VERSION ""

NS_ :

BS_:

BU_: ESM HIB HIP HIS SaGE CBC DASM DIAGNOST EBCM ECM EPS ESC ESL ETM HALF HCP IC OCM ORC PTS RF_HUB SCCM SGW

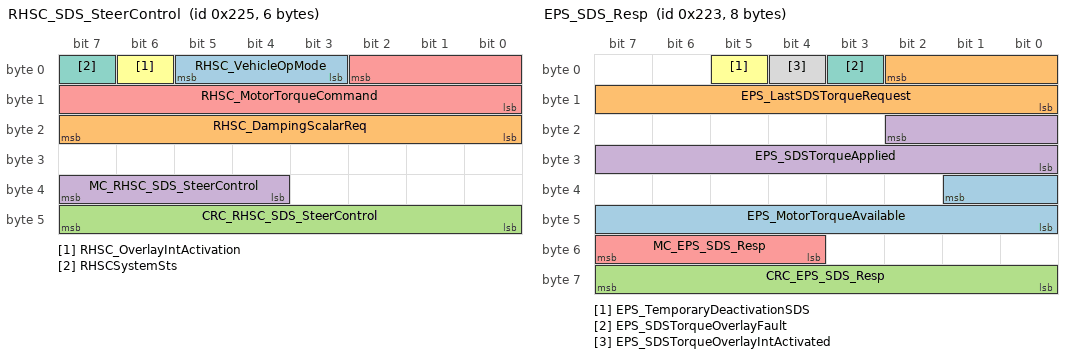
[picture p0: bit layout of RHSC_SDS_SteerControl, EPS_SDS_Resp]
BO_ 549 RHSC_SDS_SteerControl: 6 HIS
 SG_ RHSC_VehicleOpMode : 5|3@0+ (1,0) [0|6] "%"  EPS
 SG_ RHSC_DampingScalarReq : 23|8@0+ (1,0) [0|254] "%"  EPS
 SG_ CRC_RHSC_SDS_SteerControl : 40|8@1+ (1,0) [0|0] ""  EPS
 SG_ MC_RHSC_SDS_SteerControl : 36|4@1+ (1,0) [0|15] ""  EPS
 SG_ RHSC_MotorTorqueCommand : 2|11@0+ (0.0048828125,-5) [-5|4.9951171875] "Nm"  EPS
 SG_ RHSC_OverlayIntActivation : 6|1@1+ (1,0) [0|0] ""  EPS
 SG_ RHSCSystemSts : 7|1@1+ (1,0) [0|0] ""  EPS

BO_ 547 EPS_SDS_Resp: 8 EPS
 SG_ EPS_MotorTorqueAvailable : 33|10@0+ (0.00488281,0) [0|4.99022926] "Nm"  HIS
 SG_ EPS_LastSDSTorqueRequest : 2|11@0+ (0.00488281,-5) [-5|4.99022926] "Nm"  HIS
 SG_ CRC_EPS_SDS_Resp : 56|8@1+ (1,0) [0|0] ""  HIS
 SG_ EPS_SDSTorqueApplied : 18|11@0+ (0.00488281,-5) [-5|4.99022926] "Nm"  HIS
 SG_ MC_EPS_SDS_Resp : 52|4@1+ (1,0) [0|15] ""  HIS
 SG_ EPS_TemporaryDeactivationSDS : 5|1@1+ (1,0) [0|0] ""  HIS
 SG_ EPS_SDSTorqueOverlayFault : 3|1@1+ (1,0) [0|0] ""  HIS
 SG_ EPS_SDSTorqueOverlayIntActivated : 4|1@1+ (1,0) [0|0] ""  HIS

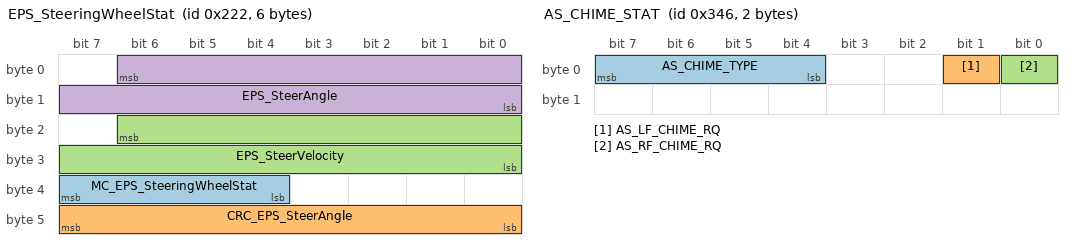
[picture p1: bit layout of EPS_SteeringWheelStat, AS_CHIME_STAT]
BO_ 546 EPS_SteeringWheelStat: 6 EPS
 SG_ MC_EPS_SteeringWheelStat : 36|4@1+ (1,0) [0|15] ""  HIS
 SG_ CRC_EPS_SteerAngle : 40|8@1+ (1,0) [0|0] ""  HIS
 SG_ EPS_SteerVelocity : 22|15@0+ (0.1,-1638.3) [-1638.3|1638.3] "deg/s"  HIS
 SG_ EPS_SteerAngle : 6|15@0+ (0.1,-1638.3) [-1638.3|1638.3] "deg"  HIS

BO_ 969 AMB_TEMP_DISP: 4 CBC
 SG_ AMB_TEMP_AVG_C : 8|8@1+ (1,-40) [-40|210] "°C"  IC,SGW
 SG_ AMB_TEMP_AVG_F : 0|8@1+ (1,-40) [-40|210] "°F"  IC,SGW

BO_ 1788 APPL_ECU_BSMO: 8 DIAGNOST
 SG_ APPL_ECU_BSMO : 7|64@0+ (1,0) [0|0] ""  ESC

BO_ 1729 APPL_ECU_CBC: 8 DIAGNOST
 SG_ APPL_ECU_CBC : 7|64@0+ (1,0) [0|0] ""  CBC

BO_ 1747 APPL_ECU_DASM: 8 DIAGNOST
 SG_ APPL_ECU_DASM : 7|64@0+ (1,0) [0|0] ""  DASM

BO_ 1787 APPL_ECU_EBCM: 8 DIAGNOST
 SG_ APPL_ECU_EBCM : 7|64@0+ (1,0) [0|0] ""  EBCM

BO_ 1784 APPL_ECU_ECM: 8 DIAGNOST
 SG_ APPL_ECU_ECM : 7|64@0+ (1,0) [0|0] ""  ECM

BO_ 1754 APPL_ECU_EPS: 8 DIAGNOST
 SG_ APPL_ECU_EPS : 7|64@0+ (1,0) [0|0] ""  EPS

BO_ 1736 APPL_ECU_ESL: 8 DIAGNOST
 SG_ APPL_ECU_ESL : 7|64@0+ (1,0) [0|0] ""  ESL

BO_ 1737 APPL_ECU_ESM: 8 DIAGNOST
 SG_ APPL_ECU_ESM : 7|64@0+ (1,0) [0|0] "" Vector__XXX

BO_ 1764 APPL_ECU_HALF: 8 DIAGNOST
 SG_ APPL_ECU_HaLF : 7|64@0+ (1,0) [0|0] ""  HALF

BO_ 1786 APPL_ECU_HCP: 8 DIAGNOST
 SG_ APPL_ECU_HCP : 7|64@0+ (1,0) [0|0] ""  HCP

BO_ 1730 APPL_ECU_IC: 8 DIAGNOST
 SG_ APPL_ECU_IC : 7|64@0+ (1,0) [0|0] ""  IC

BO_ 1758 APPL_ECU_OCM: 8 DIAGNOST
 SG_ APPL_ECU_OCM : 7|64@0+ (1,0) [0|0] ""  OCM

BO_ 1732 APPL_ECU_ORC: 8 DIAGNOST
 SG_ APPL_ECU_ORC : 7|64@0+ (1,0) [0|0] ""  ORC

BO_ 1762 APPL_ECU_PTS: 8 DIAGNOST
 SG_ APPL_ECU_PTS : 7|64@0+ (1,0) [0|0] ""  PTS

BO_ 1728 APPL_ECU_RF_HUB: 8 DIAGNOST
 SG_ APPL_ECU_RF_HUB : 7|64@0+ (1,0) [0|0] ""  RF_HUB

BO_ 1763 APPL_ECU_SCCM: 8 DIAGNOST
 SG_ APPL_ECU_SCCM : 7|64@0+ (1,0) [0|0] ""  SCCM

BO_ 838 AS_CHIME_STAT: 2 DASM
 SG_ AS_CHIME_TYPE : 4|4@1+ (1,0) [0|0] ""  CBC,ORC,SGW
 SG_ AS_LF_CHIME_RQ : 1|1@1+ (1,0) [0|0] ""  CBC,SGW
 SG_ AS_RF_CHIME_RQ : 0|1@1+ (1,0) [0|0] ""  CBC,SGW

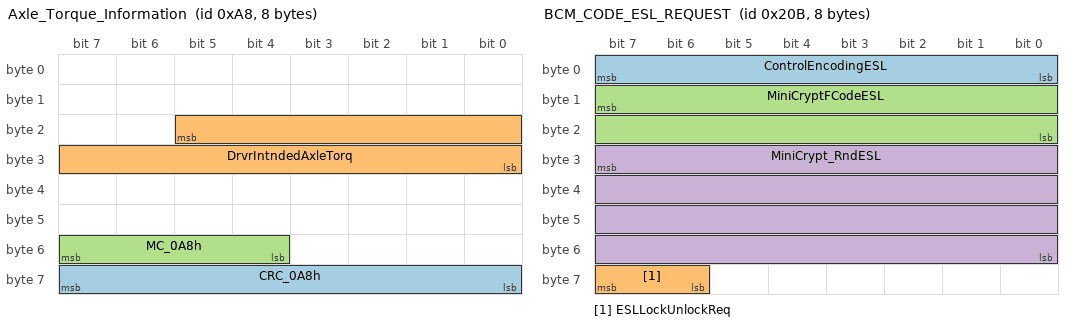
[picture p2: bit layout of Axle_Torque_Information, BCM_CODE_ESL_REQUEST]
BO_ 168 Axle_Torque_Information: 8 ECM
 SG_ CRC_0A8h : 56|8@1+ (1,0) [0|0] ""  HIB,DASM,ESC,SGW
 SG_ DrvrIntndedAxleTorq : 21|14@0+ (1.5625,-4604.688) [-4604.688|20970.3125] "Nm"  HIB,DASM,ESC,ORC,SGW
 SG_ MC_0A8h : 52|4@1+ (1,0) [0|15] ""  HIB,DASM,ESC,SGW

BO_ 523 BCM_CODE_ESL_REQUEST: 8 CBC
 SG_ ControlEncodingESL : 0|8@1+ (1,0) [0|0] ""  ESL,SGW
 SG_ ESLLockUnlockReq : 62|2@1+ (1,0) [0|0] ""  ESL,SGW
 SG_ MiniCryptFCodeESL : 15|16@0+ (1,0) [0|0] ""  ESL,SGW
 SG_ MiniCrypt_RndESL : 31|32@0+ (1,0) [0|0] ""  ESL,SGW

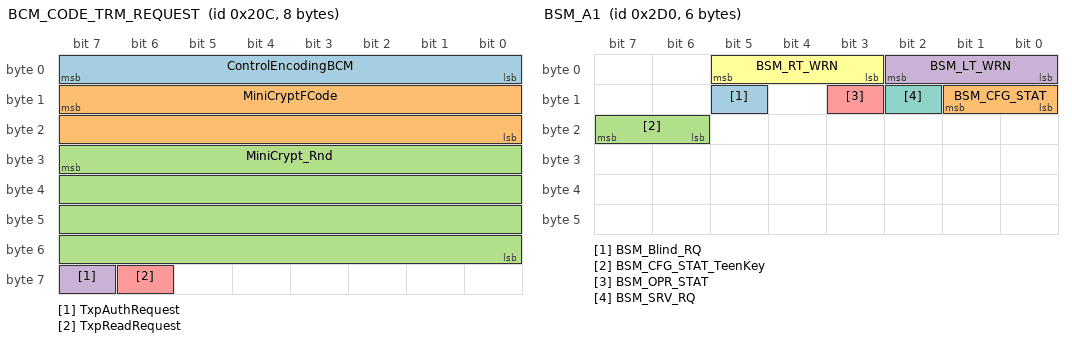
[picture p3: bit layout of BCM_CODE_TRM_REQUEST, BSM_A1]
BO_ 524 BCM_CODE_TRM_REQUEST: 8 CBC
 SG_ ControlEncodingBCM : 0|8@1+ (1,0) [0|0] ""  RF_HUB,SGW
 SG_ MiniCryptFCode : 15|16@0+ (1,0) [0|0] ""  RF_HUB,SGW
 SG_ MiniCrypt_Rnd : 31|32@0+ (1,0) [0|0] ""  RF_HUB,SGW
 SG_ TxpAuthRequest : 63|1@1+ (1,0) [0|0] ""  RF_HUB,SGW
 SG_ TxpReadRequest : 62|1@1+ (1,0) [0|0] ""  RF_HUB,SGW

BO_ 525 BCM_MINICRYPT_ACK: 1 CBC
 SG_ MinicryptReceptionSts : 7|1@1+ (1,0) [0|0] ""  RF_HUB,SGW

BO_ 720 BSM_A1: 6 CBC
 SG_ BSM_Blind_RQ : 13|1@1+ (1,0) [0|0] ""  HIB,DASM,IC,ORC,SGW
 SG_ BSM_CFG_STAT : 8|2@1+ (1,0) [0|0] ""  HIB,DASM,IC,ORC,SGW
 SG_ BSM_CFG_STAT_TeenKey : 22|2@1+ (1,0) [0|0] ""  HIB,DASM,SGW
 SG_ BSM_LT_WRN : 0|3@1+ (1,0) [0|0] ""  HIB,DASM,ORC,SGW
 SG_ BSM_OPR_STAT : 11|1@1+ (1,0) [0|0] ""  HIB,DASM,IC,SGW
 SG_ BSM_RT_WRN : 3|3@1+ (1,0) [0|0] ""  HIB,DASM,ORC,SGW
 SG_ BSM_SRV_RQ : 10|1@1+ (1,0) [0|0] ""  HIB,DASM,IC,ORC,SGW

BO_ 998 BU_NET_CFG_INT: 8 RF_HUB
 SG_ BU_NET_CFG_STAT_INT : 0|2@1+ (1,0) [0|0] ""  CBC,SGW
 SG_ BU_NetCfg_AMP_I : 24|1@1+ (1,0) [0|0] ""  CBC,SGW
 SG_ BU_NetCfg_ANC_I : 39|1@1+ (1,0) [0|0] ""  CBC,SGW
 SG_ BU_NetCfg_BSM : 3|1@1+ (1,0) [0|0] ""  CBC,SGW
 SG_ BU_NetCfg_CBC_IN : 4|1@1+ (1,0) [0|0] ""  CBC,SGW
 SG_ BU_NetCfg_CLOCK : 21|1@1+ (1,0) [0|0] ""  CBC,SGW
 SG_ BU_NetCfg_CRSM : 30|1@1+ (1,0) [0|0] ""  CBC,SGW
 SG_ BU_NetCfg_CSWM : 5|1@1+ (1,0) [0|0] ""  CBC,SGW
 SG_ BU_NetCfg_CVPM : 32|1@1+ (1,0) [0|0] ""  CBC,SGW
 SG_ BU_NetCfg_DCM_DR : 6|1@1+ (1,0) [0|0] ""  CBC,SGW
 SG_ BU_NetCfg_DCM_PASS : 7|1@1+ (1,0) [0|0] ""  CBC,SGW
 SG_ BU_NetCfg_DCM_RL : 8|1@1+ (1,0) [0|0] ""  CBC,SGW
 SG_ BU_NetCfg_DCM_RR : 9|1@1+ (1,0) [0|0] ""  CBC,SGW
 SG_ BU_NetCfg_DCSD : 37|1@1+ (1,0) [0|0] ""  CBC,SGW
 SG_ BU_NetCfg_DTV : 19|1@1+ (1,0) [0|0] ""  CBC,SGW
 SG_ BU_NetCfg_DVD_CDM : 25|1@1+ (1,0) [0|0] ""  CBC,SGW
 SG_ BU_NetCfg_FSM : 16|1@1+ (1,0) [0|0] ""  CBC,SGW
 SG_ BU_NetCfg_HFM_CTM : 26|1@1+ (1,0) [0|0] ""  CBC,SGW
 SG_ BU_NetCfg_HVAC : 10|1@1+ (1,0) [0|0] ""  CBC,SGW
 SG_ BU_NetCfg_HVAC_R : 31|1@1+ (1,0) [0|0] ""  CBC,SGW
 SG_ BU_NetCfg_ICS_I : 27|1@1+ (1,0) [0|0] ""  CBC,SGW
 SG_ BU_NetCfg_ICS_R : 34|1@1+ (1,0) [0|0] ""  CBC,SGW
 SG_ BU_NetCfg_ITM : 23|1@1+ (1,0) [0|0] ""  CBC,SGW
 SG_ BU_NetCfg_MSM : 11|1@1+ (1,0) [0|0] ""  CBC,SGW
 SG_ BU_NetCfg_MSM_PASS : 35|1@1+ (1,0) [0|0] ""  CBC,SGW
 SG_ BU_NetCfg_PLG : 12|1@1+ (1,0) [0|0] ""  CBC,SGW
 SG_ BU_NetCfg_PSD_LT : 14|1@1+ (1,0) [0|0] ""  CBC,SGW
 SG_ BU_NetCfg_PSD_RT : 15|1@1+ (1,0) [0|0] ""  CBC,SGW
 SG_ BU_NetCfg_PTCM : 17|1@1+ (1,0) [0|0] ""  CBC,SGW
 SG_ BU_NetCfg_RBC : 18|1@1+ (1,0) [0|0] ""  CBC,SGW
 SG_ BU_NetCfg_RBSS : 2|1@1+ (1,0) [0|0] ""  CBC,SGW
 SG_ BU_NetCfg_TBM : 38|1@1+ (1,0) [0|0] ""  CBC,SGW
 SG_ BU_NetCfg_TGW : 20|1@1+ (1,0) [0|0] ""  CBC,SGW
 SG_ BU_NetCfg_TMM : 33|1@1+ (1,0) [0|0] ""  CBC,SGW
 SG_ BU_NetCfg_VES2_I : 28|1@1+ (1,0) [0|0] ""  CBC,SGW
 SG_ BU_NetCfg_VES3_I : 29|1@1+ (1,0) [0|0] ""  CBC,SGW
 SG_ BU_NetCfg_VRM : 36|1@1+ (1,0) [0|0] ""  CBC,SGW
 SG_ BU_NetCfg_VSIM : 22|1@1+ (1,0) [0|0] ""  CBC,SGW
 SG_ BU_NetCfg_VTM : 13|1@1+ (1,0) [0|0] ""  CBC,SGW

BO_ 999 BU_NET_CFG_PT: 8 RF_HUB
 SG_ BU_NET_CFG_STAT_PT : 0|2@1+ (1,0) [0|0] ""  CBC,SGW
 SG_ BU_NetCfg_ACC : 2|1@1+ (1,0) [0|0] ""  CBC,SGW
 SG_ BU_NetCfg_ADCM : 3|1@1+ (1,0) [0|0] ""  CBC,SGW
 SG_ BU_NetCfg_AFLS : 28|1@1+ (1,0) [0|0] ""  CBC,SGW
 SG_ BU_NetCfg_AHLM : 4|1@1+ (1,0) [0|0] ""  CBC,SGW
 SG_ BU_NetCfg_ANC : 39|1@1+ (1,0) [0|0] ""  CBC,SGW
 SG_ BU_NetCfg_ASCM : 6|1@1+ (1,0) [0|0] ""  CBC,SGW
 SG_ BU_NetCfg_BSMO : 36|1@1+ (1,0) [0|0] ""  CBC,SGW
 SG_ BU_NetCfg_CBC_PT : 7|1@1+ (1,0) [0|0] ""  CBC,SGW
 SG_ BU_NetCfg_DASM : 16|1@1+ (1,0) [0|0] ""  CBC,SGW
 SG_ BU_NetCfg_DTCM : 8|1@1+ (1,0) [0|0] ""  CBC,SGW
 SG_ BU_NetCfg_ECM : 9|1@1+ (1,0) [0|0] ""  CBC,SGW
 SG_ BU_NetCfg_ELSD : 24|1@1+ (1,0) [0|0] ""  CBC,SGW
 SG_ BU_NetCfg_EPB : 13|1@1+ (1,0) [0|0] ""  CBC,SGW
 SG_ BU_NetCfg_EPPM : 18|1@1+ (1,0) [0|0] ""  CBC,SGW
 SG_ BU_NetCfg_EPS : 10|1@1+ (1,0) [0|0] ""  CBC,SGW
 SG_ BU_NetCfg_ESC : 12|1@1+ (1,0) [0|0] ""  CBC,SGW
 SG_ BU_NetCfg_ESL : 37|1@1+ (1,0) [0|0] ""  CBC,SGW
 SG_ BU_NetCfg_ESM : 11|1@1+ (1,0) [0|0] ""  CBC,SGW
 SG_ BU_NetCfg_FDCM : 17|1@1+ (1,0) [0|0] ""  CBC,SGW
 SG_ BU_NetCfg_HCP : 38|1@1+ (1,0) [0|0] ""  CBC,SGW
 SG_ BU_NetCfg_HaLF : 31|1@1+ (1,0) [0|0] ""  CBC,SGW
 SG_ BU_NetCfg_IC : 15|1@1+ (1,0) [0|0] ""  CBC,SGW
 SG_ BU_NetCfg_ITBM : 29|1@1+ (1,0) [0|0] ""  CBC,SGW
 SG_ BU_NetCfg_OCM : 30|1@1+ (1,0) [0|0] ""  CBC,SGW
 SG_ BU_NetCfg_ORC : 19|1@1+ (1,0) [0|0] ""  CBC,SGW
 SG_ BU_NetCfg_PASS_PT : 27|1@1+ (1,0) [0|0] ""  CBC,SGW
 SG_ BU_NetCfg_PTS : 20|1@1+ (1,0) [0|0] ""  CBC,SGW
 SG_ BU_NetCfg_RF_HUB : 14|1@1+ (1,0) [0|0] ""  CBC,SGW
 SG_ BU_NetCfg_RHSC2 : 44|1@1+ (1,0) [0|0] ""  CBC,SGW
 SG_ BU_NetCfg_SCCM : 23|1@1+ (1,0) [0|0] ""  CBC,SGW
 SG_ BU_NetCfg_TCM : 25|1@1+ (1,0) [0|0] ""  CBC,SGW
 SG_ BU_NetCfg_TPM : 26|1@1+ (1,0) [0|0] ""  CBC,SGW
 SG_ BU_NetCfg_VSIM_C : 5|1@1+ (1,0) [0|0] ""  CBC,SGW

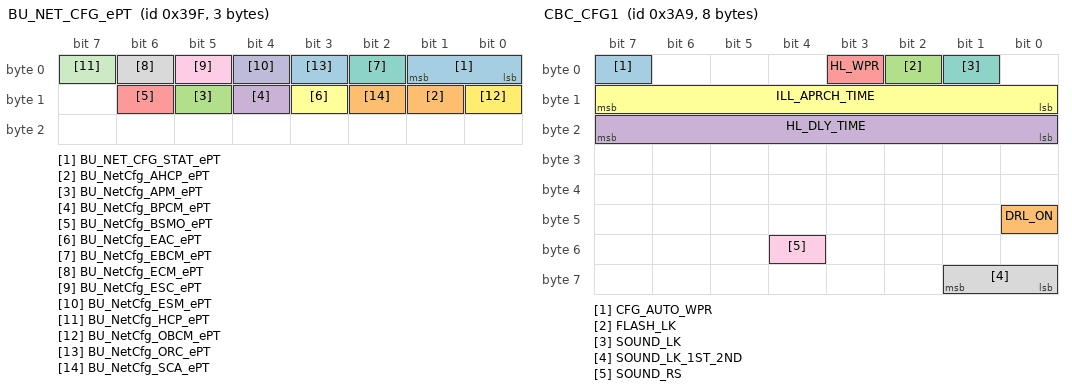
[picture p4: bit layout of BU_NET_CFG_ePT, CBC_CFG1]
BO_ 927 BU_NET_CFG_ePT: 3 RF_HUB
 SG_ BU_NET_CFG_STAT_ePT : 0|2@1+ (1,0) [0|0] ""  CBC,SGW
 SG_ BU_NetCfg_AHCP_ePT : 9|1@1+ (1,0) [0|0] ""  CBC,SGW
 SG_ BU_NetCfg_APM_ePT : 13|1@1+ (1,0) [0|0] ""  CBC,SGW
 SG_ BU_NetCfg_BPCM_ePT : 12|1@1+ (1,0) [0|0] ""  CBC,SGW
 SG_ BU_NetCfg_BSMO_ePT : 14|1@1+ (1,0) [0|0] ""  CBC,SGW
 SG_ BU_NetCfg_EAC_ePT : 11|1@1+ (1,0) [0|0] ""  CBC,SGW
 SG_ BU_NetCfg_EBCM_ePT : 2|1@1+ (1,0) [0|0] ""  CBC,SGW
 SG_ BU_NetCfg_ECM_ePT : 6|1@1+ (1,0) [0|0] ""  CBC,SGW
 SG_ BU_NetCfg_ESC_ePT : 5|1@1+ (1,0) [0|0] ""  CBC,SGW
 SG_ BU_NetCfg_ESM_ePT : 4|1@1+ (1,0) [0|0] ""  CBC,SGW
 SG_ BU_NetCfg_HCP_ePT : 7|1@1+ (1,0) [0|0] ""  CBC,SGW
 SG_ BU_NetCfg_OBCM_ePT : 8|1@1+ (1,0) [0|0] ""  CBC,SGW
 SG_ BU_NetCfg_ORC_ePT : 3|1@1+ (1,0) [0|0] ""  CBC,SGW
 SG_ BU_NetCfg_SCA_ePT : 10|1@1+ (1,0) [0|0] ""  CBC,SGW

BO_ 937 CBC_CFG1: 8 CBC
 SG_ CFG_AUTO_WPR : 7|1@1+ (1,0) [0|0] ""  SGW
 SG_ DRL_ON : 40|1@1+ (1,0) [0|0] ""  SGW
 SG_ FLASH_LK : 2|1@1+ (1,0) [0|0] ""  SGW
 SG_ HL_DLY_TIME : 16|8@1+ (1,0) [0|254] "sec"  SGW
 SG_ HL_WPR : 3|1@1+ (1,0) [0|0] ""  SGW
 SG_ ILL_APRCH_TIME : 8|8@1+ (1,0) [0|254] "sec"  SGW
 SG_ SOUND_LK : 1|1@1+ (1,0) [0|0] ""  SGW
 SG_ SOUND_LK_1ST_2ND : 56|2@1+ (1,0) [0|0] ""  SGW
 SG_ SOUND_RS : 52|1@1+ (1,0) [0|0] ""  SGW

BO_ 820 CBC_PT1: 8 CBC
 SG_ AHB_ACT : 14|1@1+ (1,0) [0|0] ""  IC,SGW
 SG_ BRK_FLUID_LO : 62|1@1+ (1,0) [0|0] ""  ESC,ETM,IC,SGW
 SG_ DAY_LGT_MD : 40|1@1+ (1,0) [0|0] ""  IC,RF_HUB,SCCM,SGW
 SG_ DRV_AJAR : 17|1@1+ (1,0) [0|0] ""  HIB,DASM,ECM,ESC,ETM,HCP,IC,PTS,RF_HUB,SGW
 SG_ DR_LK_STAT : 5|2@1+ (1,0) [0|0] ""  SGW
 SG_ FOB_SrchRq : 8|2@1+ (1,0) [0|0] ""  RF_HUB,SGW
 SG_ FT_FOG_RQ : 2|1@1+ (1,0) [0|0] ""  ETM,IC,SGW
 SG_ FT_WPR_NOT_PRK : 56|1@1+ (1,0) [0|0] ""  HIB,DASM,ECM,HALF,SGW
 SG_ HIBEAM_ON : 58|1@1+ (1,0) [0|0] ""  HIB,ETM,HALF,IC,SGW
 SG_ IGN_OFF_TIME_LNG : 27|12@0+ (1,0) [0|4080] "min"  HIB,DASM,ECM,ESC,SGW
 SG_ LOBEAM_ON : 57|1@1+ (1,0) [0|0] ""  SGW
 SG_ L_R_AJAR : 19|1@1+ (1,0) [0|0] ""  ETM,IC,RF_HUB,SGW
 SG_ PANEL_INTS : 48|8@1+ (0.5,0) [0|100] "%"  IC,RF_HUB,SCCM,SGW
 SG_ PARK_LMP_ON : 16|1@1+ (1,0) [0|0] ""  IC,SGW
 SG_ PSG_AJAR : 18|1@1+ (1,0) [0|0] ""  ESC,ETM,IC,RF_HUB,SGW
 SG_ REV_GEAR : 4|1@1+ (1,0) [0|0] ""  EPS,HALF,ORC,SGW
 SG_ R_FOG_RQ : 3|1@1+ (1,0) [0|0] ""  IC,SGW
 SG_ R_R_AJAR : 20|1@1+ (1,0) [0|0] ""  ETM,IC,RF_HUB,SGW
 SG_ SHIP_STAT : 28|2@1+ (1,0) [0|0] ""  HIB,DASM,HCP,IC,RF_HUB,SGW
 SG_ TLG_AJAR : 22|1@1+ (1,0) [0|0] ""  ETM,IC,PTS,RF_HUB,SGW
 SG_ TurnInd_LT_ON : 30|1@1+ (1,0) [0|0] ""  HIB,ETM,HALF,IC,SGW
 SG_ TurnInd_RT_ON : 31|1@1+ (1,0) [0|0] ""  HIB,ETM,HALF,IC,SGW
 SG_ WASH_FLUID_LO : 63|1@1+ (1,0) [0|0] ""  ETM,IC,SGW

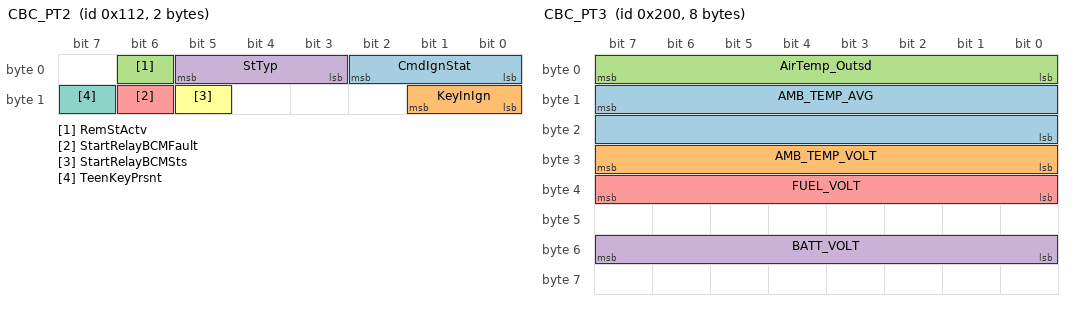
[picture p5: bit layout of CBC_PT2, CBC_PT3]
BO_ 274 CBC_PT2: 2 CBC
 SG_ CmdIgnStat : 0|3@1+ (1,0) [0|0] ""  HIB,DASM,EBCM,ECM,EPS,ESC,ESL,HALF,HCP,IC,OCM,ORC,PTS,RF_HUB,SCCM,SGW
 SG_ KeyInIgn : 8|2@1+ (1,0) [0|0] ""  ESL,HCP,IC,RF_HUB,SGW
 SG_ RemStActv : 6|1@1+ (1,0) [0|0] ""  ECM,HCP,IC,RF_HUB,SGW
 SG_ StTyp : 3|3@1+ (1,0) [0|0] ""  RF_HUB,SGW
 SG_ StartRelayBCMFault : 14|1@1+ (1,0) [0|0] ""  ECM,SGW
 SG_ StartRelayBCMSts : 13|1@1+ (1,0) [0|0] ""  ECM,SGW
 SG_ TeenKeyPrsnt : 15|1@1+ (1,0) [0|0] ""  HIB,DASM,ECM,IC,ORC,PTS,SGW

BO_ 512 CBC_PT3: 8 CBC
 SG_ AMB_TEMP_AVG : 15|16@0+ (0.01,-40) [-40|85] "°C"  HIB,DASM,ECM,EPS,ESC,OCM,PTS,RF_HUB,SGW
 SG_ AMB_TEMP_VOLT : 24|8@1+ (0.019607843,0) [0|4.98] "Volts"  ECM,HCP,SGW
 SG_ AirTemp_Outsd : 0|8@1+ (0.5,-40) [-40|85] "°C"  HIB,DASM,ECM,EPS,RF_HUB,SGW
 SG_ BATT_VOLT : 48|8@1+ (0.1,0) [5|18] "Volts"  HIB,DASM,EBCM,ECM,EPS,ESC,ESL,HALF,HCP,IC,OCM,ORC,PTS,RF_HUB,SCCM,SGW
 SG_ FUEL_VOLT : 32|8@1+ (0.019607843,0) [0|4.98] "Volts"  ECM,IC,SGW

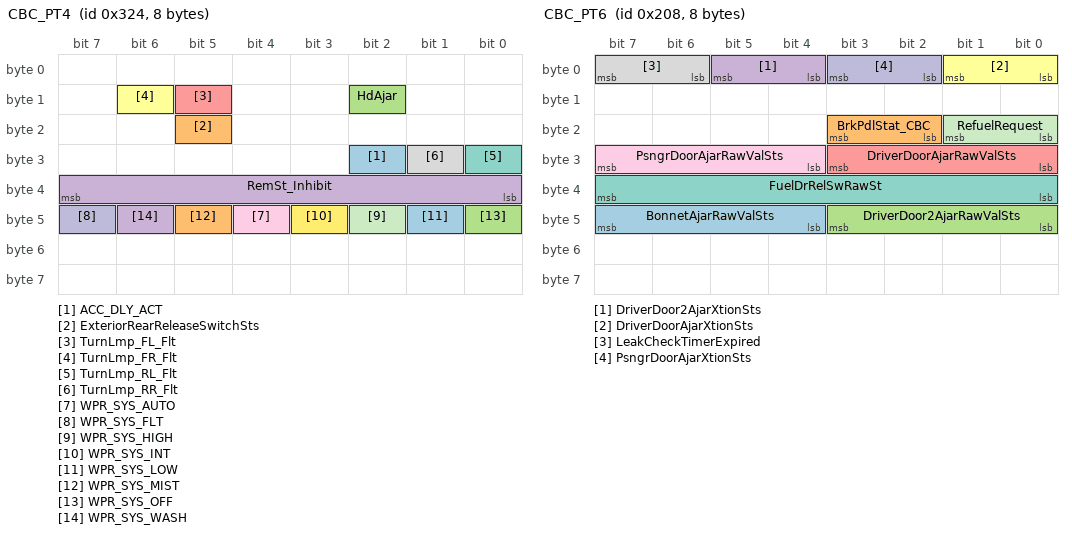
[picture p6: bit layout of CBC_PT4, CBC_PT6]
BO_ 804 CBC_PT4: 8 CBC
 SG_ ACC_DLY_ACT : 26|1@1+ (1,0) [0|0] ""  IC,SGW
 SG_ ExteriorRearReleaseSwitchSts : 21|1@1+ (1,0) [0|0] ""  RF_HUB,SGW
 SG_ HdAjar : 10|1@1+ (1,0) [0|0] ""  HCP,IC,SGW
 SG_ RemSt_Inhibit : 32|8@1+ (1,0) [0|0] ""  ETM,IC,SGW
 SG_ TurnLmp_FL_Flt : 13|1@1+ (1,0) [0|0] ""  HIB,ETM,HALF,IC,SGW
 SG_ TurnLmp_FR_Flt : 14|1@1+ (1,0) [0|0] ""  HIB,ETM,HALF,IC,SGW
 SG_ TurnLmp_RL_Flt : 24|1@1+ (1,0) [0|0] ""  HIB,ETM,HALF,IC,SGW
 SG_ TurnLmp_RR_Flt : 25|1@1+ (1,0) [0|0] ""  HIB,ETM,HALF,IC,SGW
 SG_ WPR_SYS_AUTO : 44|1@1+ (1,0) [0|0] ""  HIB,DASM,ESC,HALF,SGW
 SG_ WPR_SYS_FLT : 47|1@1+ (1,0) [0|0] ""  HIB,DASM,ESC,HALF,SGW
 SG_ WPR_SYS_HIGH : 42|1@1+ (1,0) [0|0] ""  HIB,DASM,ESC,HALF,SGW
 SG_ WPR_SYS_INT : 43|1@1+ (1,0) [0|0] ""  HIB,DASM,ESC,HALF,SGW
 SG_ WPR_SYS_LOW : 41|1@1+ (1,0) [0|0] ""  HIB,DASM,ESC,HALF,SGW
 SG_ WPR_SYS_MIST : 45|1@1+ (1,0) [0|0] ""  HIB,DASM,ESC,HALF,SGW
 SG_ WPR_SYS_OFF : 40|1@1+ (1,0) [0|0] ""  HIB,DASM,ESC,HALF,SGW
 SG_ WPR_SYS_WASH : 46|1@1+ (1,0) [0|0] ""  HIB,DASM,ESC,HALF,SGW

BO_ 520 CBC_PT6: 8 CBC
 SG_ BonnetAjarRawValSts : 44|4@1+ (1,0) [0|0] ""  ECM,HCP,ORC,SGW
 SG_ BrkPdlStat_CBC : 18|2@1+ (1,0) [0|0] ""  RF_HUB,SGW
 SG_ DriverDoor2AjarRawValSts : 40|4@1+ (1,0) [0|0] ""  ECM,ORC,SGW
 SG_ DriverDoor2AjarXtionSts : 4|2@1+ (1,0) [0|0] ""  ECM,SGW
 SG_ DriverDoorAjarRawValSts : 24|4@1+ (1,0) [0|0] ""  ECM,ESC,ORC,SGW
 SG_ DriverDoorAjarXtionSts : 0|2@1+ (1,0) [0|0] ""  ECM,ESC,SGW
 SG_ FuelDrRelSwRawSt : 32|8@1+ (0.019607843,0) [0|4.98] "Volts"  ECM,SGW
 SG_ LeakCheckTimerExpired : 6|2@1+ (1,0) [0|0] ""  ECM,SGW
 SG_ PsngrDoorAjarRawValSts : 28|4@1+ (1,0) [0|0] ""  ECM,ORC,SGW
 SG_ PsngrDoorAjarXtionSts : 2|2@1+ (1,0) [0|0] ""  SGW
 SG_ RefuelRequest : 16|2@1+ (1,0) [0|0] ""  ECM,SGW

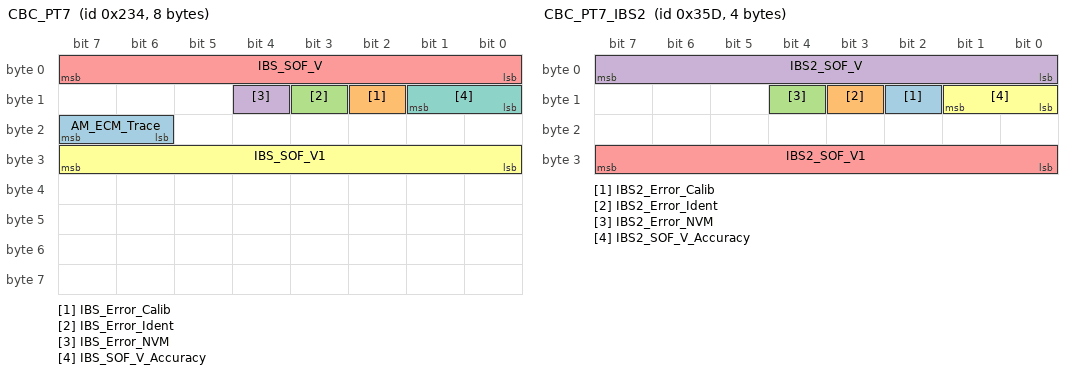
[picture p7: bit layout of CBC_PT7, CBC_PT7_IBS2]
BO_ 564 CBC_PT7: 8 CBC
 SG_ AM_ECM_Trace : 22|2@1+ (1,0) [0|0] ""  ECM,SGW
 SG_ IBS_Error_Calib : 10|1@1+ (1,0) [0|0] ""  SGW
 SG_ IBS_Error_Ident : 11|1@1+ (1,0) [0|0] ""  SGW
 SG_ IBS_Error_NVM : 12|1@1+ (1,0) [0|0] ""  SGW
 SG_ IBS_SOF_V : 0|8@1+ (0.0625,0) [0|15.875] "V"  SGW
 SG_ IBS_SOF_V1 : 24|8@1+ (0.0625,0) [0|15.875] "V"  SGW
 SG_ IBS_SOF_V_Accuracy : 8|2@1+ (1,0) [0|0] ""  SGW

BO_ 861 CBC_PT7_IBS2: 4 CBC
 SG_ IBS2_Error_Calib : 10|1@1+ (1,0) [0|0] ""  SGW
 SG_ IBS2_Error_Ident : 11|1@1+ (1,0) [0|0] ""  SGW
 SG_ IBS2_Error_NVM : 12|1@1+ (1,0) [0|0] ""  SGW
 SG_ IBS2_SOF_V : 0|8@1+ (0.0625,0) [0|15.875] "V"  SGW
 SG_ IBS2_SOF_V1 : 24|8@1+ (0.0625,0) [0|15.875] "V"  SGW
 SG_ IBS2_SOF_V_Accuracy : 8|2@1+ (1,0) [0|0] ""  SGW

BO_TX_BU_ 1788 : DIAGNOST,SGW;
BO_TX_BU_ 1729 : DIAGNOST,SGW;
BO_TX_BU_ 1747 : DIAGNOST,SGW;
BO_TX_BU_ 1787 : DIAGNOST,SGW;
BO_TX_BU_ 1784 : DIAGNOST,SGW;
BO_TX_BU_ 1754 : DIAGNOST,SGW;
BO_TX_BU_ 1736 : DIAGNOST,SGW;
BO_TX_BU_ 1737 : DIAGNOST,SGW;
BO_TX_BU_ 1764 : DIAGNOST,SGW;
BO_TX_BU_ 1786 : DIAGNOST,SGW;
BO_TX_BU_ 1730 : DIAGNOST,SGW;
BO_TX_BU_ 1758 : DIAGNOST,SGW;
BO_TX_BU_ 1732 : DIAGNOST,SGW;
BO_TX_BU_ 1762 : DIAGNOST,SGW;
BO_TX_BU_ 1728 : DIAGNOST,SGW;
BO_TX_BU_ 1763 : DIAGNOST,SGW;

CM_ "Excel Convert to DBC - Written by Vector CANtech, Inc. 2016";
CM_ SG_ 549 RHSC_VehicleOpMode "RHSC vehicle operating mode (Driver Present [0] / Driverless [1])";
CM_ SG_ 549 RHSC_DampingScalarReq "RHSC torque overlay damping scalar request";
CM_ SG_ 549 CRC_RHSC_SDS_SteerControl "CRC-checksum byte 1 to 7 according to SAE J1850";
CM_ SG_ 549 MC_RHSC_SDS_SteerControl "Message counter";
CM_ SG_ 549 RHSC_MotorTorqueCommand "RHSC torque overlay steering request";
CM_ SG_ 549 RHSC_OverlayIntActivation "Torque overlay interface activation; Active = [1]";
CM_ SG_ 549 RHSCSystemSts "Fault of the HALF torque overlay interface; Fault = [1]";
CM_ SG_ 547 EPS_MotorTorqueAvailable "EPS Motor Torque Available for SDS under current conditions";
CM_ SG_ 547 EPS_LastSDSTorqueRequest "Echo Back of Last SDS Valid Torque Request";
CM_ SG_ 547 CRC_EPS_SDS_Resp "CRC-checksum byte 1 to 7 according to SAE J1850";
CM_ SG_ 547 EPS_SDSTorqueApplied "EPS Motor Torque Applied for SDS";
CM_ SG_ 547 MC_EPS_SDS_Resp "Message counter";
CM_ SG_ 547 EPS_TemporaryDeactivationSDS "Temporary deactivation of the EPS SDS torque overlay function, False = [0], True = [1];";
CM_ SG_ 547 EPS_SDSTorqueOverlayFault "Fault of the SDS torque overlay interface, False = [0], True = [1];";
CM_ SG_ 547 EPS_SDSTorqueOverlayIntActivated "Activation Status of the SDS torque overlay interface, False = [0], True = [1];";
CM_ SG_ 546 MC_EPS_SteeringWheelStat "Message counter";
CM_ SG_ 546 CRC_EPS_SteerAngle "CRC-checksum byte 1 to 7 according to SAE J1850";
CM_ SG_ 546 EPS_SteerVelocity "Steer Velocity based on EPS Motor Position sensor";
CM_ SG_ 546 EPS_SteerAngle "Steer Angle based on EPS Motor Position sensor - relative angle from key on";
CM_ SG_ 969 AMB_TEMP_AVG_C "Ambient temperature average - in degrees Celsius";
CM_ SG_ 969 AMB_TEMP_AVG_F "Ambient temperature average - in degrees Fahrenheit";
CM_ SG_ 1788 APPL_ECU_BSMO "External Application to ECU";
CM_ SG_ 1729 APPL_ECU_CBC "External Application to ECU";
CM_ SG_ 1747 APPL_ECU_DASM "External Application to ECU";
CM_ SG_ 1787 APPL_ECU_EBCM "External Application to ECU";
CM_ SG_ 1784 APPL_ECU_ECM "External Application to ECU";
CM_ SG_ 1754 APPL_ECU_EPS "External Application to ECU";
CM_ SG_ 1736 APPL_ECU_ESL "External Application to ECU";
CM_ SG_ 1737 APPL_ECU_ESM "External Application to ECU";
CM_ SG_ 1764 APPL_ECU_HaLF "External Application to ECU";
CM_ SG_ 1786 APPL_ECU_HCP "External Application to ECU";
CM_ SG_ 1730 APPL_ECU_IC "External Application to ECU";
CM_ SG_ 1758 APPL_ECU_OCM "External Application to ECU";
CM_ SG_ 1732 APPL_ECU_ORC "External Application to ECU";
CM_ SG_ 1762 APPL_ECU_PTS "External Application to ECU";
CM_ SG_ 1728 APPL_ECU_RF_HUB "External Application to ECU";
CM_ SG_ 1763 APPL_ECU_SCCM "External Application to ECU";
CM_ SG_ 838 AS_CHIME_TYPE "AS chime type";
CM_ SG_ 838 AS_LF_CHIME_RQ "AS left front chime on request; True = [1]";
CM_ SG_ 838 AS_RF_CHIME_RQ "AS right front chime on request; True = [1]";
CM_ SG_ 168 CRC_0A8h "CRC-Checksum Byte 1 - 7 according to SAE J1850";
CM_ SG_ 168 DrvrIntndedAxleTorq "Driver Intended Axle Torque";
CM_ SG_ 168 MC_0A8h "Message counter   0A8h";
CM_ SG_ 523 ControlEncodingESL "ESL immobilizer action requested";
CM_ SG_ 523 ESLLockUnlockReq "Lock or unlock column";
CM_ SG_ 523 MiniCryptFCodeESL "BCM MiniCrypt code";
CM_ SG_ 523 MiniCrypt_RndESL "MiniCrypt random number";
CM_ SG_ 524 ControlEncodingBCM "Fob authentication or presence query";
CM_ SG_ 524 MiniCryptFCode "MiniCrypt 'F' code output";
CM_ SG_ 524 MiniCrypt_Rnd "MiniCrypt input random number";
CM_ SG_ 524 TxpAuthRequest "Transponder authentication request; Request = [0]";
CM_ SG_ 524 TxpReadRequest "Transponder reading request; Request = [0]";
CM_ SG_ 525 MinicryptReceptionSts "Acknowledge message reception; Received = [1]";
CM_ SG_ 720 BSM_Blind_RQ "Sensor blinded request from BSM; 1= sensor blocked request";
CM_ SG_ 720 BSM_CFG_STAT "BSM configuration status";
CM_ SG_ 720 BSM_CFG_STAT_TeenKey "BSM configuration status for teen key";
CM_ SG_ 720 BSM_LT_WRN "Blind spot detection left side warning";
CM_ SG_ 720 BSM_OPR_STAT "BSM operation status; 1= operational failure";
CM_ SG_ 720 BSM_RT_WRN "Blind spot detection Right side warning";
CM_ SG_ 720 BSM_SRV_RQ "BSM service warning request; 1= service request";
CM_ SG_ 998 BU_NET_CFG_STAT_INT "Backup for network configuration status";
CM_ SG_ 998 BU_NetCfg_AMP_I "Backup for CAN I Amplifier Module (1=present)";
CM_ SG_ 998 BU_NetCfg_ANC_I "Backup for Active Noise Cancellation interior (1=present)";
CM_ SG_ 998 BU_NetCfg_BSM "Backup for Blind-Spot Module (1=present)";
CM_ SG_ 998 BU_NetCfg_CBC_IN "Backup for Common Body Controller Int Bus (1=present)";
CM_ SG_ 998 BU_NetCfg_CLOCK "Backup for CAN I Clock Module (1=present)";
CM_ SG_ 998 BU_NetCfg_CRSM "Backup for CAN I Comfort Rear Seat Module (1=present)";
CM_ SG_ 998 BU_NetCfg_CSWM "Backup for Comfot Seats and Wheel Module (1=present)";
CM_ SG_ 998 BU_NetCfg_CVPM "Backup for CAN I Central Vision Processing Module (1=present)";
CM_ SG_ 998 BU_NetCfg_DCM_DR "Backup for Door Control Module Driver (1=present)";
CM_ SG_ 998 BU_NetCfg_DCM_PASS "Backup for Door Control Module Passenger (1=present)";
CM_ SG_ 998 BU_NetCfg_DCM_RL "Backup for Door Control Module Rear Left (1=present)";
CM_ SG_ 998 BU_NetCfg_DCM_RR "Backup for Door Control Module Rear Right (1=present)";
CM_ SG_ 998 BU_NetCfg_DCSD "Backup for Disassociated Center Stack Display Module (1=present)";
CM_ SG_ 998 BU_NetCfg_DTV "Backup for Digital TV Module (1=present)";
CM_ SG_ 998 BU_NetCfg_DVD_CDM "Backup for CAN I in-dash disc player module (1=present)";
CM_ SG_ 998 BU_NetCfg_FSM "Backup for Folding Seat Module (1=present)";
CM_ SG_ 998 BU_NetCfg_HFM_CTM "Backup for Convergence Telematics Module (1=present)";
CM_ SG_ 998 BU_NetCfg_HVAC "Backup for Heating Ventilation Air Conditioning (1=present)";
CM_ SG_ 998 BU_NetCfg_HVAC_R "Backup for CAN I Rear Heating Ventilation Air Conditioning (1=present)";
CM_ SG_ 998 BU_NetCfg_ICS_I "Backup for CAN I Integrated Center Stack Module (1=present)";
CM_ SG_ 998 BU_NetCfg_ICS_R "Backup for CAN I Integrated rear Center Stack Module (1=present)";
CM_ SG_ 998 BU_NetCfg_ITM "Backup for Intrusion module (1=present)";
CM_ SG_ 998 BU_NetCfg_MSM "Backup for Memory Seat Module (1=present)";
CM_ SG_ 998 BU_NetCfg_MSM_PASS "Backup for CAN I Memory Seat Module Passenger (1=present)";
CM_ SG_ 998 BU_NetCfg_PLG "Backup for Power Liftgate Module (1=present)";
CM_ SG_ 998 BU_NetCfg_PSD_LT "Backup for Power Sliding Door Left Module (1=present)";
CM_ SG_ 998 BU_NetCfg_PSD_RT "Backup for Power Sliding Door Right Module (1=present)";
CM_ SG_ 998 BU_NetCfg_PTCM "Backup for Power Top Control Module (1=present)";
CM_ SG_ 998 BU_NetCfg_RBC "Backup for Rear Body Controller Module (1=present)";
CM_ SG_ 998 BU_NetCfg_RBSS "Backup for Right Blind-Spot Module (1=present)";
CM_ SG_ 998 BU_NetCfg_TBM "Backup for Telematics Box Module (1=present)";
CM_ SG_ 998 BU_NetCfg_TGW "Backup for Telematics gateway (1=present)";
CM_ SG_ 998 BU_NetCfg_TMM "Backup for CAN I Track Mapping Module (1=present)";
CM_ SG_ 998 BU_NetCfg_VES2_I "Backup for CAN I Video Ent. System screen 2 Module (1=present)";
CM_ SG_ 998 BU_NetCfg_VES3_I "Backup for CAN I Video Ent. System screen 1 Module (1=present)";
CM_ SG_ 998 BU_NetCfg_VRM "Backup for Video Routing Module (1=present)";
CM_ SG_ 998 BU_NetCfg_VSIM "Backup for Vehicle System Interface Module (1=present)";
CM_ SG_ 998 BU_NetCfg_VTM "Backup for vehicle theft / tax module (1=present)";
CM_ SG_ 999 BU_NET_CFG_STAT_PT "Backup for network configuration status";
CM_ SG_ 999 BU_NetCfg_ACC "Backup for Active Cruise Control (1=present)";
CM_ SG_ 999 BU_NetCfg_ADCM "Backup for Active Damping Control Module (1=present)";
CM_ SG_ 999 BU_NetCfg_AFLS "Backup for Advanced Front Lighting System (1=present)";
CM_ SG_ 999 BU_NetCfg_AHLM "Backup for Automatic Headlamp Leveling Module (1=present)";
CM_ SG_ 999 BU_NetCfg_ANC "Backup for Active Noise Cancellation (1=present)";
CM_ SG_ 999 BU_NetCfg_ASCM "Backup for Air Suspension Control Module (1=present)";
CM_ SG_ 999 BU_NetCfg_BSMO "Backup for Brake System Module - OBD (1=present)";
CM_ SG_ 999 BU_NetCfg_CBC_PT "Backup for Common Body Controller PT Bus (1=present)";
CM_ SG_ 999 BU_NetCfg_DASM "Backup for Driver Assistance System Module (1=present)";
CM_ SG_ 999 BU_NetCfg_DTCM "Backup for Drivetrain Control Module (1=present)";
CM_ SG_ 999 BU_NetCfg_ECM "Backup for Engine Control Module (1=present)";
CM_ SG_ 999 BU_NetCfg_ELSD "Backup for Electric Limited Slip Differential (1=present)";
CM_ SG_ 999 BU_NetCfg_EPB "Backup for Electric Park Brake Module (1=present)";
CM_ SG_ 999 BU_NetCfg_EPPM "Backup for  Elect. Pedestrian protection module (1=present)";
CM_ SG_ 999 BU_NetCfg_EPS "Backup for Electric Power Steering (1=present)";
CM_ SG_ 999 BU_NetCfg_ESC "Backup for Electronic Stability Module / Anti-Lock Brake (1=present)";
CM_ SG_ 999 BU_NetCfg_ESL "Backup for Electric Steering Lock (1=present)";
CM_ SG_ 999 BU_NetCfg_ESM "Backup for Electronic Shift Module (1=present)";
CM_ SG_ 999 BU_NetCfg_FDCM "Backup for Final Drive Control Module (1=present)";
CM_ SG_ 999 BU_NetCfg_HCP "Backup for Hybrid Control Processor (1=present)";
CM_ SG_ 999 BU_NetCfg_HaLF "Backup for Haptic Lane Feedback module (1=present)";
CM_ SG_ 999 BU_NetCfg_IC "Backup for Instrument Cluster (1=present)";
CM_ SG_ 999 BU_NetCfg_ITBM "Backup for Integrated Trailer Brake Module (1=present)";
CM_ SG_ 999 BU_NetCfg_OCM "Backup for Occupant Classification Module (1=present)";
CM_ SG_ 999 BU_NetCfg_ORC "Backup for Occupant Restraint Controller (1=present)";
CM_ SG_ 999 BU_NetCfg_PASS_PT "Backup for Personal Assistant Safety System Module PT Bus (1=present)";
CM_ SG_ 999 BU_NetCfg_PTS "Backup for Parktronics System (1=present)";
CM_ SG_ 999 BU_NetCfg_RF_HUB "Backup for RF HUB Node (1=present)";
CM_ SG_ 999 BU_NetCfg_RHSC2 "RHSC2 module (1=present)";
CM_ SG_ 999 BU_NetCfg_SCCM "Backup for Steering Column Control Module (1=present)";
CM_ SG_ 999 BU_NetCfg_TCM "Backup for Automatic Transmission Controller (1=present)";
CM_ SG_ 999 BU_NetCfg_TPM "Backup for Tire Pressure Monitor (1=present)";
CM_ SG_ 999 BU_NetCfg_VSIM_C "Backup for Vehicle System Interface Module (1=present)";
CM_ SG_ 927 BU_NET_CFG_STAT_ePT "Backup for network configuration status";
CM_ SG_ 927 BU_NetCfg_AHCP_ePT "Backup for Auxiliary Hybrid Control Processor (1=present)";
CM_ SG_ 927 BU_NetCfg_APM_ePT "Backup for Auxiliary Power Module (1=present)";
CM_ SG_ 927 BU_NetCfg_BPCM_ePT "Backup for Battery Pack Control Module (1=present)";
CM_ SG_ 927 BU_NetCfg_BSMO_ePT "Backup for Brake System Module - OBD (1=present)";
CM_ SG_ 927 BU_NetCfg_EAC_ePT "Backup for Electric AC Compressor (1=present)";
CM_ SG_ 927 BU_NetCfg_EBCM_ePT "Backup for Electronic Boost Control Module (1=present)";
CM_ SG_ 927 BU_NetCfg_ECM_ePT "Backup for Engine Controller Module (1=present)";
CM_ SG_ 927 BU_NetCfg_ESC_ePT "Backup for Electronic Stability Control (1=present)";
CM_ SG_ 927 BU_NetCfg_ESM_ePT "Backup for Electronic Shifter Module (1=present)";
CM_ SG_ 927 BU_NetCfg_HCP_ePT "Backup for Hybrid Control Processor (1=present)";
CM_ SG_ 927 BU_NetCfg_OBCM_ePT "Backup for On Board Charging Module (1=present)";
CM_ SG_ 927 BU_NetCfg_ORC_ePT "Backup for Occupant Restraint Controller (1=present)";
CM_ SG_ 927 BU_NetCfg_SCA_ePT "Backup for Smart Cluch Actuator (1=present)";
CM_ SG_ 937 CFG_AUTO_WPR "Auto wiper configuration; no = [0], yes =[1]";
CM_ SG_ 937 DRL_ON "Daytime running lamps on; enabled = [1]";
CM_ SG_ 937 FLASH_LK "Flash lamps with lock; no = [0], yes = [1]";
CM_ SG_ 937 HL_DLY_TIME "Headlamp delay time";
CM_ SG_ 937 HL_WPR "Headlamp on with wiper; no = [0], yes =[1]";
CM_ SG_ 937 ILL_APRCH_TIME "Illuminated approach time";
CM_ SG_ 937 SOUND_LK "Sound horn on lock; no = [0], yes = [1]";
CM_ SG_ 937 SOUND_LK_1ST_2ND "Sound horn on lock status";
CM_ SG_ 937 SOUND_RS "Sound horn on Remote Start ; no = [0], yes = [1]";
CM_ SG_ 820 AHB_ACT "Automatic high beam active";
CM_ SG_ 820 BRK_FLUID_LO "Low brake fluid warning; low = [1]";
CM_ SG_ 820 DAY_LGT_MD "Day light brightness mode; Night=[0], Day=[1]";
CM_ SG_ 820 DRV_AJAR "Driver door ajar (1 = Door Ajar)";
CM_ SG_ 820 DR_LK_STAT "Door lock status";
CM_ SG_ 820 FOB_SrchRq "FOB search request";
CM_ SG_ 820 FT_FOG_RQ "Front fog request; off=[0], on=[1]";
CM_ SG_ 820 FT_WPR_NOT_PRK "Front wiper outside park position";
CM_ SG_ 820 HIBEAM_ON "High beam is on; off=[0], on=[1]";
CM_ SG_ 820 IGN_OFF_TIME_LNG "Time since last ignition on (long)";
CM_ SG_ 820 LOBEAM_ON "Low beam is on; off=[0], on=[1]";
CM_ SG_ 820 L_R_AJAR "Left rear door ajar";
CM_ SG_ 820 PANEL_INTS "Panel-/display intensity";
CM_ SG_ 820 PARK_LMP_ON "Parklamps are on; off=[0], on=[1]";
CM_ SG_ 820 PSG_AJAR "Passenger door ajar";
CM_ SG_ 820 REV_GEAR "Reverse Gear (manual trans)";
CM_ SG_ 820 R_FOG_RQ "Rear fog request; [0] = off, [1] = on";
CM_ SG_ 820 R_R_AJAR "Right rear door ajar";
CM_ SG_ 820 SHIP_STAT "Shipping status";
CM_ SG_ 820 TLG_AJAR "Trunk/Liftgate ajar";
CM_ SG_ 820 TurnInd_LT_ON "Turn indication left is on";
CM_ SG_ 820 TurnInd_RT_ON "Turn indication right is on";
CM_ SG_ 820 WASH_FLUID_LO "Low washer fluid warning (1=Fluid is low)";
CM_ SG_ 274 CmdIgnStat "Commanded ignition switch status";
CM_ SG_ 274 KeyInIgn "Key in ignition status";
CM_ SG_ 274 RemStActv "Ignition run active for remote start (0=not active, 1=active)";
CM_ SG_ 274 StTyp "Type of start being requested";
CM_ SG_ 274 StartRelayBCMFault "CBC starter relay fault detected";
CM_ SG_ 274 StartRelayBCMSts "CBC starter relay status; [1] = ON";
CM_ SG_ 274 TeenKeyPrsnt "Teen key present; Present = [1]";
CM_ SG_ 512 AMB_TEMP_AVG "Averaged ambient temperature";
CM_ SG_ 512 AMB_TEMP_VOLT "Ambient Temp Sensor A/D Voltage";
CM_ SG_ 512 AirTemp_Outsd "Outside air temperature";
CM_ SG_ 512 BATT_VOLT "System voltage";
CM_ SG_ 512 FUEL_VOLT "Fuel level A/D Voltage (Single tank OR Primary on Saddle/Dual Tank)";
CM_ SG_ 804 ACC_DLY_ACT "Accessory Delay Active";
CM_ SG_ 804 ExteriorRearReleaseSwitchSts "Exterior rear release switch status";
CM_ SG_ 804 HdAjar "Hood latch ajar, left or single (1=ajar)";
CM_ SG_ 804 RemSt_Inhibit "Remote start inhibit";
CM_ SG_ 804 TurnLmp_FL_Flt "Turn indication lamp front left fault";
CM_ SG_ 804 TurnLmp_FR_Flt "Turn indication lamp front right fault";
CM_ SG_ 804 TurnLmp_RL_Flt "Turn indication lamp rear left fault";
CM_ SG_ 804 TurnLmp_RR_Flt "Turn indication lamp rear right fault";
CM_ SG_ 804 WPR_SYS_AUTO "Wiper system auto; [1] = Auto wipers equipped";
CM_ SG_ 804 WPR_SYS_FLT "Wiper system fault present; [1] = fault present";
CM_ SG_ 804 WPR_SYS_HIGH "Wiper system high; [1] = switch is HIGH";
CM_ SG_ 804 WPR_SYS_INT "Wiper system intermittent; [1] = switch is INT";
CM_ SG_ 804 WPR_SYS_LOW "Wiper system low; [1] = switch is LOW";
CM_ SG_ 804 WPR_SYS_MIST "Wiper system mist; [1] = mist request";
CM_ SG_ 804 WPR_SYS_OFF "Wiper system off; [1] = switch is OFF";
CM_ SG_ 804 WPR_SYS_WASH "Wiper system wash; [1] = wash request";
CM_ SG_ 520 BonnetAjarRawValSts "Hood ajar status";
CM_ SG_ 520 BrkPdlStat_CBC "Brake pedal state reported by CBC";
CM_ SG_ 520 DriverDoor2AjarRawValSts "Drivers door switch - 2 ajar status";
CM_ SG_ 520 DriverDoor2AjarXtionSts "Drivers door switch - 2 ajar transition status";
CM_ SG_ 520 DriverDoorAjarRawValSts "Drivers door ajar status";
CM_ SG_ 520 DriverDoorAjarXtionSts "Drivers door ajar transition status";
CM_ SG_ 520 FuelDrRelSwRawSt "Raw voltage of fuel door release switch in the cabin";
CM_ SG_ 520 LeakCheckTimerExpired "Status of leak test timer";
CM_ SG_ 520 PsngrDoorAjarRawValSts "Passengers door ajar status";
CM_ SG_ 520 PsngrDoorAjarXtionSts "Front passenger door ajar transition status";
CM_ SG_ 520 RefuelRequest "Driver has initiated a refueling event";
CM_ SG_ 564 AM_ECM_Trace "Aftermarket ECM trace";
CM_ SG_ 564 IBS_Error_Calib "Error in IBS calibration data; Error = [1]";
CM_ SG_ 564 IBS_Error_Ident "Error in ECU identification; Error = [1]";
CM_ SG_ 564 IBS_Error_NVM "Error in IBS NVM data; Error = [1]";
CM_ SG_ 564 IBS_SOF_V "Predicted battery voltage during cranking V2";
CM_ SG_ 564 IBS_SOF_V1 "Predicted initial battery voltage dip during cranking";
CM_ SG_ 564 IBS_SOF_V_Accuracy "SOF_V accuracy status";
CM_ SG_ 861 IBS2_Error_Calib "Error in IBS2 calibration data; Error = [1]";
CM_ SG_ 861 IBS2_Error_Ident "Error in ECU identification Batt 2; Error = [1]";
CM_ SG_ 861 IBS2_Error_NVM "Error in IBS2 NVM data; Error = [1]";
CM_ SG_ 861 IBS2_SOF_V "Predicted 2nd battery voltage during cranking V2";
CM_ SG_ 861 IBS2_SOF_V1 "Predicted initial 2nd battery voltage dip during cranking";
CM_ SG_ 861 IBS2_SOF_V_Accuracy "SOF_V accuracy status Batt 2";
BA_DEF_ BO_  "App-Botschaft" ENUM  "nein","ja";
BA_DEF_ BO_  "CanMsgMinLen" INT 0 8;
BA_DEF_ BO_  "DiagRequest" ENUM  "nein","ja";
BA_DEF_ BO_  "DiagResponse" ENUM  "nein","ja";
BA_DEF_ BO_  "DiagState" ENUM  "nein","ja";
BA_DEF_ BO_  "GenMsgCycleTime" INT 0 65535;
BA_DEF_ BO_  "GenMsgCycleTimeActive" INT 0 65535;
BA_DEF_ BO_  "GenMsgDelayTime" INT 0 65535;
BA_DEF_ BO_  "GenMsgNrOfRepetitions" INT 0 65535;
BA_DEF_ BO_  "GenMsgSendType" ENUM  "cyclicX","spontanX","cyclicIfActiveX","spontanWithDelay","cyclicAndSpontanX","cyclicAndSpontanWithDelay","spontanWithRepitition","cyclicIfActiveAndSpontanWD","cyclicIfActiveFast","cyclicWithRepeatOnDemand","none";
BA_DEF_ BO_  "GenMsgStartDelayTime" INT 0 65535;
BA_DEF_ BO_  "GenMsgStartValue" STRING ;
BA_DEF_ BO_  "NWM-Botschaft" ENUM  "nein","ja";
BA_DEF_ BO_  "TpTxIndex" INT 0 99;
BA_DEF_  "Baudrate" INT 0 1000000;
BA_DEF_  "Manufacturer" ENUM  "DBAG","VAG","BMWAG","PAG","GM";
BA_DEF_  "NBTMax" INT 0 255;
BA_DEF_  "NBTMin" INT 0 255;
BA_DEF_  "NmMessageCount" INT 0 64;
BA_DEF_  "NWM-Basisadresse" HEX 0 536870911;
BA_DEF_  "NWM-Typ" ENUM  "zentral (MB-W210)","dezentral (MB-OSAN)","keines","VAG-OSEK","BMW-OSEK","PAG-OSEK","DBAG-OSEK";
BA_DEF_  "SamplePointMax" FLOAT 0 100;
BA_DEF_  "SamplePointMin" FLOAT 0 100;
BA_DEF_  "Version" HEX 0 4080;
BA_DEF_  "VersionWeek" INT 0 53;
BA_DEF_  "VersionYear" INT 0 99;
BA_DEF_ BU_  "NWM-Knoten" ENUM  "nein","ja";
BA_DEF_ BU_  "NWM-Stationsadresse" HEX 0 63;
BA_DEF_ BU_  "TpNodeBaseAddress" HEX 0 65535;
BA_DEF_ BU_  "TpOwnSystemEcuNumber" HEX 0 255;
BA_DEF_ SG_  "FlexKomComment" STRING ;
BA_DEF_ SG_  "FlexKomIsMotorola" ENUM  "nein","ja";
BA_DEF_ SG_  "FlexKomSID" INT 0 2147483647;
BA_DEF_ SG_  "FlexKomSigLaenge" INT 0 64;
BA_DEF_ SG_  "FlexKomSigName" STRING ;
BA_DEF_ SG_  "FlexKomSigStartPos" INT 0 63;
BA_DEF_ SG_  "FlexKomSigStartValue" STRING ;
BA_DEF_ SG_  "GenSigCycleTime" INT 0 65535;
BA_DEF_ SG_  "GenSigCycleTimeActive" INT 0 65535;
BA_DEF_ SG_  "GenSigSendType" ENUM  "cyclicX","spontanX","cyclicIfActiveX","spontanWithDelay","cyclicAndSpontanX","cyclicAndSpontanWithDelay","spontanWithRepitition","cyclicIfActiveAndSpontanWD","cyclicIfActiveFast","cyclicWithRepeatOnDemand","none";
BA_DEF_ SG_  "GenSigSNA" STRING ;
BA_DEF_ SG_  "GenSigStartValue" HEX 0 2147483648;
BA_DEF_ SG_  "GenSigTimeout_CBC" INT 0 65535;
BA_DEF_ SG_  "GenSigTimeout_EPS" INT 0 65535;
BA_DEF_ SG_  "GenSigTimeout_ESC" INT 0 65535;
BA_DEF_ SG_  "GenSigTimeout_ESL" INT 0 65535;
BA_DEF_ SG_  "GenSigTimeout_RHSC2" INT 0 65535;
BA_DEF_ SG_  "GenSigTimeout_ETM" INT 0 65535;
BA_DEF_ SG_  "GenSigTimeout_HaLF" INT 0 65535;
BA_DEF_ SG_  "GenSigTimeout_IC" INT 0 65535;
BA_DEF_ SG_  "GenSigTimeout_OCM" INT 0 65535;
BA_DEF_ SG_  "GenSigTimeout_ORC" INT 0 65535;
BA_DEF_ SG_  "GenSigTimeout_PTS" INT 0 65535;
BA_DEF_ SG_  "GenSigTimeout_RF_HUB" INT 0 65535;
BA_DEF_ SG_  "GenSigTimeout_SCCM" INT 0 65535;
BA_DEF_ SG_  "RID" STRING ;
BA_DEF_DEF_  "App-Botschaft" "nein";
BA_DEF_DEF_  "CanMsgMinLen" 0;
BA_DEF_DEF_  "DiagRequest" "nein";
BA_DEF_DEF_  "DiagResponse" "nein";
BA_DEF_DEF_  "DiagState" "nein";
BA_DEF_DEF_  "GenMsgCycleTime" 0;
BA_DEF_DEF_  "GenMsgCycleTimeActive" 0;
BA_DEF_DEF_  "GenMsgDelayTime" 0;
BA_DEF_DEF_  "GenMsgNrOfRepetitions" 0;
BA_DEF_DEF_  "GenMsgSendType" "cyclicX";
BA_DEF_DEF_  "GenMsgStartDelayTime" 0;
BA_DEF_DEF_  "GenMsgStartValue" "";
BA_DEF_DEF_  "NWM-Botschaft" "nein";
BA_DEF_DEF_  "TpTxIndex" 0;
BA_DEF_DEF_  "Baudrate" 500000;
BA_DEF_DEF_  "Manufacturer" "DBAG";
BA_DEF_DEF_  "NBTMax" 20;
BA_DEF_DEF_  "NBTMin" 10;
BA_DEF_DEF_  "NmMessageCount" 64;
BA_DEF_DEF_  "NWM-Basisadresse" 1024;
BA_DEF_DEF_  "NWM-Typ" "DBAG-OSEK";
BA_DEF_DEF_  "SamplePointMax" 81.25;
BA_DEF_DEF_  "SamplePointMin" 75;
BA_DEF_DEF_  "Version" 4;
BA_DEF_DEF_  "VersionWeek" 26;
BA_DEF_DEF_  "VersionYear" 18;
BA_DEF_DEF_  "NWM-Knoten" "nein";
BA_DEF_DEF_  "NWM-Stationsadresse" 0;
BA_DEF_DEF_  "TpNodeBaseAddress" 0;
BA_DEF_DEF_  "TpOwnSystemEcuNumber" 0;
BA_DEF_DEF_  "FlexKomComment" "";
BA_DEF_DEF_  "FlexKomIsMotorola" "nein";
BA_DEF_DEF_  "FlexKomSID" 0;
BA_DEF_DEF_  "FlexKomSigLaenge" 0;
BA_DEF_DEF_  "FlexKomSigName" "";
BA_DEF_DEF_  "FlexKomSigStartPos" 0;
BA_DEF_DEF_  "FlexKomSigStartValue" "";
BA_DEF_DEF_  "GenSigCycleTime" 0;
BA_DEF_DEF_  "GenSigCycleTimeActive" 0;
BA_DEF_DEF_  "GenSigSendType" "cyclicX";
BA_DEF_DEF_  "GenSigSNA" "";
BA_DEF_DEF_  "GenSigStartValue" 0;
BA_DEF_DEF_  "GenSigTimeout_CBC" 0;
BA_DEF_DEF_  "GenSigTimeout_EPS" 0;
BA_DEF_DEF_  "GenSigTimeout_ESC" 0;
BA_DEF_DEF_  "GenSigTimeout_ESL" 0;
BA_DEF_DEF_  "GenSigTimeout_RHSC2" 0;
BA_DEF_DEF_  "GenSigTimeout_ETM" 0;
BA_DEF_DEF_  "GenSigTimeout_HaLF" 0;
BA_DEF_DEF_  "GenSigTimeout_IC" 0;
BA_DEF_DEF_  "GenSigTimeout_OCM" 0;
BA_DEF_DEF_  "GenSigTimeout_ORC" 0;
BA_DEF_DEF_  "GenSigTimeout_PTS" 0;
BA_DEF_DEF_  "GenSigTimeout_RF_HUB" 0;
BA_DEF_DEF_  "GenSigTimeout_SCCM" 0;
BA_DEF_DEF_  "RID" "";
BA_ "NWM-Knoten" BU_ CBC 1;
BA_ "NWM-Stationsadresse" BU_ CBC 1;
BA_ "NWM-Knoten" BU_ EBCM 1;
BA_ "NWM-Stationsadresse" BU_ EBCM 59;
BA_ "NWM-Knoten" BU_ EPS 1;
BA_ "NWM-Stationsadresse" BU_ EPS 26;
BA_ "NWM-Knoten" BU_ ESC 1;
BA_ "NWM-Stationsadresse" BU_ ESC 7;
BA_ "NWM-Knoten" BU_ ESL 1;
BA_ "NWM-Stationsadresse" BU_ ESL 8;
BA_ "NWM-Knoten" BU_ HCP 1;
BA_ "NWM-Stationsadresse" BU_ HCP 58;
BA_ "NWM-Knoten" BU_ IC 1;
BA_ "NWM-Stationsadresse" BU_ IC 2;
BA_ "NWM-Knoten" BU_ RF_HUB 1;
BA_ "NWM-Knoten" BU_ SCCM 1;
BA_ "NWM-Stationsadresse" BU_ SCCM 35;
BA_ "GenMsgCycleTime" BO_ 549 10;
BA_ "GenMsgDelayTime" BO_ 549 20;
BA_ "GenMsgNrOfRepetitions" BO_ 549 2;
BA_ "GenMsgStartValue" BO_ 549 "0400000000FFh";
BA_ "GenMsgStartValue" BO_ 547 "07FF07FF03FF00FFh";
BA_ "GenMsgNrOfRepetitions" BO_ 547 2;
BA_ "GenMsgDelayTime" BO_ 547 20;
BA_ "GenMsgCycleTime" BO_ 547 10;
BA_ "GenMsgStartValue" BO_ 546 "7FFF7FFF00FFh";
BA_ "GenMsgDelayTime" BO_ 546 20;
BA_ "GenMsgCycleTime" BO_ 546 10;
BA_ "GenMsgCycleTime" BO_ 969 1000;
BA_ "GenMsgDelayTime" BO_ 969 20;
BA_ "GenMsgNrOfRepetitions" BO_ 969 2;
BA_ "GenMsgStartValue" BO_ 969 "FFFF0000h";
BA_ "App-Botschaft" BO_ 1788 1;
BA_ "GenMsgDelayTime" BO_ 1788 20;
BA_ "GenMsgNrOfRepetitions" BO_ 1788 2;
BA_ "GenMsgSendType" BO_ 1788 1;
BA_ "GenMsgStartValue" BO_ 1788 "0000000000000000h";
BA_ "App-Botschaft" BO_ 1729 1;
BA_ "GenMsgDelayTime" BO_ 1729 20;
BA_ "GenMsgNrOfRepetitions" BO_ 1729 2;
BA_ "GenMsgSendType" BO_ 1729 1;
BA_ "GenMsgStartValue" BO_ 1729 "0000000000000000h";
BA_ "App-Botschaft" BO_ 1747 1;
BA_ "GenMsgDelayTime" BO_ 1747 20;
BA_ "GenMsgNrOfRepetitions" BO_ 1747 2;
BA_ "GenMsgSendType" BO_ 1747 1;
BA_ "GenMsgStartValue" BO_ 1747 "0000000000000000h";
BA_ "App-Botschaft" BO_ 1787 1;
BA_ "GenMsgDelayTime" BO_ 1787 20;
BA_ "GenMsgNrOfRepetitions" BO_ 1787 2;
BA_ "GenMsgSendType" BO_ 1787 1;
BA_ "GenMsgStartValue" BO_ 1787 "0000000000000000h";
BA_ "App-Botschaft" BO_ 1784 1;
BA_ "GenMsgDelayTime" BO_ 1784 20;
BA_ "GenMsgNrOfRepetitions" BO_ 1784 2;
BA_ "GenMsgSendType" BO_ 1784 1;
BA_ "GenMsgStartValue" BO_ 1784 "0000000000000000h";
BA_ "App-Botschaft" BO_ 1754 1;
BA_ "GenMsgDelayTime" BO_ 1754 20;
BA_ "GenMsgNrOfRepetitions" BO_ 1754 2;
BA_ "GenMsgSendType" BO_ 1754 1;
BA_ "GenMsgStartValue" BO_ 1754 "0000000000000000h";
BA_ "App-Botschaft" BO_ 1736 1;
BA_ "GenMsgDelayTime" BO_ 1736 20;
BA_ "GenMsgNrOfRepetitions" BO_ 1736 2;
BA_ "GenMsgSendType" BO_ 1736 1;
BA_ "GenMsgStartValue" BO_ 1736 "0000000000000000h";
BA_ "App-Botschaft" BO_ 1737 1;
BA_ "GenMsgDelayTime" BO_ 1737 20;
BA_ "GenMsgNrOfRepetitions" BO_ 1737 2;
BA_ "GenMsgSendType" BO_ 1737 1;
BA_ "GenMsgStartValue" BO_ 1737 "0000000000000000h";
BA_ "App-Botschaft" BO_ 1764 1;
BA_ "GenMsgDelayTime" BO_ 1764 20;
BA_ "GenMsgNrOfRepetitions" BO_ 1764 2;
BA_ "GenMsgSendType" BO_ 1764 1;
BA_ "GenMsgStartValue" BO_ 1764 "0000000000000000h";
BA_ "App-Botschaft" BO_ 1786 1;
BA_ "GenMsgDelayTime" BO_ 1786 20;
BA_ "GenMsgNrOfRepetitions" BO_ 1786 2;
BA_ "GenMsgSendType" BO_ 1786 1;
BA_ "GenMsgStartValue" BO_ 1786 "0000000000000000h";
BA_ "App-Botschaft" BO_ 1730 1;
BA_ "GenMsgDelayTime" BO_ 1730 20;
BA_ "GenMsgNrOfRepetitions" BO_ 1730 2;
BA_ "GenMsgSendType" BO_ 1730 1;
BA_ "GenMsgStartValue" BO_ 1730 "0000000000000000h";
BA_ "App-Botschaft" BO_ 1758 1;
BA_ "GenMsgDelayTime" BO_ 1758 20;
BA_ "GenMsgNrOfRepetitions" BO_ 1758 2;
BA_ "GenMsgSendType" BO_ 1758 1;
BA_ "GenMsgStartValue" BO_ 1758 "0000000000000000h";
BA_ "App-Botschaft" BO_ 1732 1;
BA_ "GenMsgDelayTime" BO_ 1732 20;
BA_ "GenMsgNrOfRepetitions" BO_ 1732 2;
BA_ "GenMsgSendType" BO_ 1732 1;
BA_ "GenMsgStartValue" BO_ 1732 "0000000000000000h";
BA_ "App-Botschaft" BO_ 1762 1;
BA_ "GenMsgDelayTime" BO_ 1762 20;
BA_ "GenMsgNrOfRepetitions" BO_ 1762 2;
BA_ "GenMsgSendType" BO_ 1762 1;
BA_ "GenMsgStartValue" BO_ 1762 "0000000000000000h";
BA_ "App-Botschaft" BO_ 1728 1;
BA_ "GenMsgDelayTime" BO_ 1728 20;
BA_ "GenMsgNrOfRepetitions" BO_ 1728 2;
BA_ "GenMsgSendType" BO_ 1728 1;
BA_ "GenMsgStartValue" BO_ 1728 "0000000000000000h";
BA_ "App-Botschaft" BO_ 1763 1;
BA_ "GenMsgDelayTime" BO_ 1763 20;
BA_ "GenMsgNrOfRepetitions" BO_ 1763 2;
BA_ "GenMsgSendType" BO_ 1763 1;
BA_ "GenMsgStartValue" BO_ 1763 "0000000000000000h";
BA_ "GenMsgCycleTime" BO_ 838 1000;
BA_ "GenMsgDelayTime" BO_ 838 20;
BA_ "GenMsgNrOfRepetitions" BO_ 838 2;
BA_ "GenMsgSendType" BO_ 838 5;
BA_ "GenMsgStartValue" BO_ 838 "0000h";
BA_ "GenMsgCycleTime" BO_ 168 10;
BA_ "GenMsgDelayTime" BO_ 168 20;
BA_ "GenMsgNrOfRepetitions" BO_ 168 2;
BA_ "GenMsgStartValue" BO_ 168 "0B830B830B8300FFh";
BA_ "GenMsgDelayTime" BO_ 523 20;
BA_ "GenMsgNrOfRepetitions" BO_ 523 2;
BA_ "GenMsgSendType" BO_ 523 1;
BA_ "GenMsgStartValue" BO_ 523 "0000000000000000h";
BA_ "GenMsgDelayTime" BO_ 524 20;
BA_ "GenMsgNrOfRepetitions" BO_ 524 2;
BA_ "GenMsgSendType" BO_ 524 1;
BA_ "GenMsgStartValue" BO_ 524 "0000000000000000h";
BA_ "GenMsgDelayTime" BO_ 525 20;
BA_ "GenMsgNrOfRepetitions" BO_ 525 2;
BA_ "GenMsgSendType" BO_ 525 1;
BA_ "GenMsgStartValue" BO_ 525 "00h";
BA_ "GenMsgCycleTime" BO_ 720 500;
BA_ "GenMsgDelayTime" BO_ 720 20;
BA_ "GenMsgNrOfRepetitions" BO_ 720 2;
BA_ "GenMsgSendType" BO_ 720 5;
BA_ "GenMsgStartValue" BO_ 720 "0003C0000000h";
BA_ "GenMsgDelayTime" BO_ 998 20;
BA_ "GenMsgNrOfRepetitions" BO_ 998 2;
BA_ "GenMsgSendType" BO_ 998 1;
BA_ "GenMsgStartValue" BO_ 998 "0300000000000000h";
BA_ "GenMsgDelayTime" BO_ 999 20;
BA_ "GenMsgNrOfRepetitions" BO_ 999 2;
BA_ "GenMsgSendType" BO_ 999 1;
BA_ "GenMsgStartValue" BO_ 999 "0300000000000000h";
BA_ "GenMsgDelayTime" BO_ 927 20;
BA_ "GenMsgNrOfRepetitions" BO_ 927 2;
BA_ "GenMsgSendType" BO_ 927 1;
BA_ "GenMsgStartValue" BO_ 927 "030000h";
BA_ "GenMsgCycleTime" BO_ 937 1000;
BA_ "GenMsgDelayTime" BO_ 937 20;
BA_ "GenMsgNrOfRepetitions" BO_ 937 2;
BA_ "GenMsgSendType" BO_ 937 5;
BA_ "GenMsgStartDelayTime" BO_ 937 10;
BA_ "GenMsgStartValue" BO_ 937 "00FFFFFFFF00C003h";
BA_ "GenMsgCycleTime" BO_ 820 1000;
BA_ "GenMsgDelayTime" BO_ 820 20;
BA_ "GenMsgNrOfRepetitions" BO_ 820 2;
BA_ "GenMsgSendType" BO_ 820 5;
BA_ "GenMsgStartDelayTime" BO_ 820 20;
BA_ "GenMsgStartValue" BO_ 820 "6000003FFFFC0000h";
BA_ "GenMsgCycleTime" BO_ 274 20;
BA_ "GenMsgDelayTime" BO_ 274 20;
BA_ "GenMsgNrOfRepetitions" BO_ 274 2;
BA_ "GenMsgStartValue" BO_ 274 "0000h";
BA_ "GenMsgCycleTime" BO_ 512 100;
BA_ "GenMsgDelayTime" BO_ 512 20;
BA_ "GenMsgNrOfRepetitions" BO_ 512 2;
BA_ "GenMsgStartValue" BO_ 512 "FFFFFFFFFFFFFFFFh";
BA_ "GenMsgCycleTime" BO_ 804 1000;
BA_ "GenMsgDelayTime" BO_ 804 20;
BA_ "GenMsgNrOfRepetitions" BO_ 804 2;
BA_ "GenMsgSendType" BO_ 804 5;
BA_ "GenMsgStartDelayTime" BO_ 804 30;
BA_ "GenMsgStartValue" BO_ 804 "000C000000010000h";
BA_ "GenMsgCycleTime" BO_ 520 20;
BA_ "GenMsgDelayTime" BO_ 520 20;
BA_ "GenMsgNrOfRepetitions" BO_ 520 2;
BA_ "GenMsgStartDelayTime" BO_ 520 10;
BA_ "GenMsgStartValue" BO_ 520 "3FFF0C0000000000h";
BA_ "GenMsgCycleTime" BO_ 564 100;
BA_ "GenMsgDelayTime" BO_ 564 20;
BA_ "GenMsgNrOfRepetitions" BO_ 564 2;
BA_ "GenMsgStartDelayTime" BO_ 564 10;
BA_ "GenMsgStartValue" BO_ 564 "FF030CFFh";
BA_ "GenMsgCycleTime" BO_ 861 100;
BA_ "GenMsgDelayTime" BO_ 861 20;
BA_ "GenMsgNrOfRepetitions" BO_ 861 2;
BA_ "GenMsgStartDelayTime" BO_ 861 10;
BA_ "GenMsgStartValue" BO_ 861 "FF030CFFh";
BA_ "FlexKomComment" SG_ 549 RHSC_VehicleOpMode "RHSC_SDS_SteerControl_Pkt";
BA_ "FlexKomIsMotorola" SG_ 549 RHSC_VehicleOpMode 1;
BA_ "FlexKomSID" SG_ 549 RHSC_VehicleOpMode 2598;
BA_ "FlexKomSigLaenge" SG_ 549 RHSC_VehicleOpMode 48;
BA_ "FlexKomSigStartPos" SG_ 549 RHSC_VehicleOpMode 7;
BA_ "FlexKomSigStartValue" SG_ 549 RHSC_VehicleOpMode "0400000000FFh";
BA_ "GenSigCycleTime" SG_ 549 RHSC_VehicleOpMode 10;
BA_ "GenSigSNA" SG_ 549 RHSC_VehicleOpMode "0h";
BA_ "FlexKomSigName" SG_ 549 RHSC_VehicleOpMode "RHSC_SDS_SteerControl_Pkt";
BA_ "GenSigSNA" SG_ 549 RHSC_DampingScalarReq "0h";
BA_ "GenSigCycleTime" SG_ 549 RHSC_DampingScalarReq 10;
BA_ "FlexKomSigStartValue" SG_ 549 RHSC_DampingScalarReq "0400000000FFh";
BA_ "FlexKomSigStartPos" SG_ 549 RHSC_DampingScalarReq 7;
BA_ "FlexKomSigName" SG_ 549 RHSC_DampingScalarReq "RHSC_SDS_SteerControl_Pkt";
BA_ "FlexKomSigLaenge" SG_ 549 RHSC_DampingScalarReq 48;
BA_ "FlexKomSID" SG_ 549 RHSC_DampingScalarReq 2598;
BA_ "FlexKomIsMotorola" SG_ 549 RHSC_DampingScalarReq 1;
BA_ "FlexKomComment" SG_ 549 RHSC_DampingScalarReq "RHSC_SDS_SteerControl_Pkt";
BA_ "FlexKomComment" SG_ 549 CRC_RHSC_SDS_SteerControl "RHSC_SDS_SteerControl_Pkt";
BA_ "FlexKomIsMotorola" SG_ 549 CRC_RHSC_SDS_SteerControl 1;
BA_ "FlexKomSID" SG_ 549 CRC_RHSC_SDS_SteerControl 2598;
BA_ "FlexKomSigLaenge" SG_ 549 CRC_RHSC_SDS_SteerControl 64;
BA_ "FlexKomSigName" SG_ 549 CRC_RHSC_SDS_SteerControl "RHSC_SDS_SteerControl_Pkt";
BA_ "FlexKomSigStartPos" SG_ 549 CRC_RHSC_SDS_SteerControl 7;
BA_ "FlexKomSigStartValue" SG_ 549 CRC_RHSC_SDS_SteerControl "0400000000FFh";
BA_ "GenSigCycleTime" SG_ 549 CRC_RHSC_SDS_SteerControl 10;
BA_ "GenSigSNA" SG_ 549 CRC_RHSC_SDS_SteerControl "FFh";
BA_ "GenSigStartValue" SG_ 549 CRC_RHSC_SDS_SteerControl 255;
BA_ "FlexKomComment" SG_ 549 MC_RHSC_SDS_SteerControl "RHSC_SDS_SteerControl_Pkt";
BA_ "FlexKomIsMotorola" SG_ 549 MC_RHSC_SDS_SteerControl 1;
BA_ "FlexKomSID" SG_ 549 MC_RHSC_SDS_SteerControl 2598;
BA_ "FlexKomSigLaenge" SG_ 549 MC_RHSC_SDS_SteerControl 64;
BA_ "FlexKomSigName" SG_ 549 MC_RHSC_SDS_SteerControl "RHSC_SDS_SteerControl_Pkt";
BA_ "FlexKomSigStartPos" SG_ 549 MC_RHSC_SDS_SteerControl 7;
BA_ "FlexKomSigStartValue" SG_ 549 MC_RHSC_SDS_SteerControl "0400000000FFh";
BA_ "GenSigCycleTime" SG_ 549 MC_RHSC_SDS_SteerControl 10;
BA_ "GenSigSNA" SG_ 549 MC_RHSC_SDS_SteerControl "0h";
BA_ "FlexKomComment" SG_ 549 RHSC_MotorTorqueCommand "RHSC_SDS_SteerControl_Pkt";
BA_ "FlexKomIsMotorola" SG_ 549 RHSC_MotorTorqueCommand 1;
BA_ "FlexKomSID" SG_ 549 RHSC_MotorTorqueCommand 2598;
BA_ "FlexKomSigLaenge" SG_ 549 RHSC_MotorTorqueCommand 48;
BA_ "FlexKomSigName" SG_ 549 RHSC_MotorTorqueCommand "RHSC_SDS_SteerControl_Pkt";
BA_ "FlexKomSigStartPos" SG_ 549 RHSC_MotorTorqueCommand 7;
BA_ "FlexKomSigStartValue" SG_ 549 RHSC_MotorTorqueCommand "0400000000FFh";
BA_ "GenSigCycleTime" SG_ 549 RHSC_MotorTorqueCommand 10;
BA_ "GenSigSNA" SG_ 549 RHSC_MotorTorqueCommand "0h";
BA_ "GenSigStartValue" SG_ 549 RHSC_MotorTorqueCommand 1024;
BA_ "FlexKomComment" SG_ 549 RHSC_OverlayIntActivation "RHSC_SDS_SteerControl_Pkt";
BA_ "FlexKomIsMotorola" SG_ 549 RHSC_OverlayIntActivation 1;
BA_ "FlexKomSID" SG_ 549 RHSC_OverlayIntActivation 2598;
BA_ "FlexKomSigLaenge" SG_ 549 RHSC_OverlayIntActivation 48;
BA_ "FlexKomSigName" SG_ 549 RHSC_OverlayIntActivation "RHSC_SDS_SteerControl_Pkt";
BA_ "FlexKomSigStartPos" SG_ 549 RHSC_OverlayIntActivation 7;
BA_ "FlexKomSigStartValue" SG_ 549 RHSC_OverlayIntActivation "0400000000FFh";
BA_ "GenSigCycleTime" SG_ 549 RHSC_OverlayIntActivation 10;
BA_ "GenSigSNA" SG_ 549 RHSC_OverlayIntActivation "0h";
BA_ "FlexKomComment" SG_ 549 RHSCSystemSts "RHSC_SDS_SteerControl_Pkt";
BA_ "FlexKomIsMotorola" SG_ 549 RHSCSystemSts 1;
BA_ "FlexKomSID" SG_ 549 RHSCSystemSts 2598;
BA_ "FlexKomSigLaenge" SG_ 549 RHSCSystemSts 64;
BA_ "FlexKomSigName" SG_ 549 RHSCSystemSts "RHSC_SDS_SteerControl_Pkt";
BA_ "FlexKomSigStartPos" SG_ 549 RHSCSystemSts 7;
BA_ "FlexKomSigStartValue" SG_ 549 RHSCSystemSts "0400000000FFh";
BA_ "GenSigCycleTime" SG_ 549 RHSCSystemSts 10;
BA_ "GenSigSNA" SG_ 549 RHSCSystemSts "0h";
BA_ "FlexKomComment" SG_ 547 EPS_MotorTorqueAvailable "EPS_SDS_Resp_Pkt";
BA_ "FlexKomIsMotorola" SG_ 547 EPS_MotorTorqueAvailable 1;
BA_ "FlexKomSID" SG_ 547 EPS_MotorTorqueAvailable 2594;
BA_ "FlexKomSigLaenge" SG_ 547 EPS_MotorTorqueAvailable 32;
BA_ "FlexKomSigName" SG_ 547 EPS_MotorTorqueAvailable "EPS_SDS_Resp_Pkt";
BA_ "FlexKomSigStartPos" SG_ 547 EPS_MotorTorqueAvailable 7;
BA_ "FlexKomSigStartValue" SG_ 547 EPS_MotorTorqueAvailable "07FF07FF03FF00FFh";
BA_ "GenSigCycleTime" SG_ 547 EPS_MotorTorqueAvailable 10;
BA_ "GenSigSNA" SG_ 547 EPS_MotorTorqueAvailable "0x7FFF";
BA_ "GenSigStartValue" SG_ 547 EPS_MotorTorqueAvailable 1023;
BA_ "GenSigSNA" SG_ 547 EPS_LastSDSTorqueRequest "0x7FFF";
BA_ "FlexKomSigStartValue" SG_ 547 EPS_LastSDSTorqueRequest "07FF07FF03FF00FFh";
BA_ "FlexKomSigStartPos" SG_ 547 EPS_LastSDSTorqueRequest 7;
BA_ "FlexKomSigName" SG_ 547 EPS_LastSDSTorqueRequest "EPS_SDS_Resp_Pkt";
BA_ "FlexKomSigLaenge" SG_ 547 EPS_LastSDSTorqueRequest 32;
BA_ "FlexKomSID" SG_ 547 EPS_LastSDSTorqueRequest 2594;
BA_ "FlexKomIsMotorola" SG_ 547 EPS_LastSDSTorqueRequest 1;
BA_ "FlexKomComment" SG_ 547 EPS_LastSDSTorqueRequest "EPS_SDS_Resp_Pkt";
BA_ "GenSigStartValue" SG_ 547 EPS_LastSDSTorqueRequest 2047;
BA_ "GenSigCycleTime" SG_ 547 EPS_LastSDSTorqueRequest 10;
BA_ "FlexKomComment" SG_ 547 CRC_EPS_SDS_Resp "EPS_SDS_Resp_Pkt";
BA_ "FlexKomIsMotorola" SG_ 547 CRC_EPS_SDS_Resp 1;
BA_ "FlexKomSID" SG_ 547 CRC_EPS_SDS_Resp 2594;
BA_ "FlexKomSigLaenge" SG_ 547 CRC_EPS_SDS_Resp 64;
BA_ "FlexKomSigName" SG_ 547 CRC_EPS_SDS_Resp "EPS_SDS_Resp_Pkt";
BA_ "FlexKomSigStartPos" SG_ 547 CRC_EPS_SDS_Resp 7;
BA_ "FlexKomSigStartValue" SG_ 547 CRC_EPS_SDS_Resp "07FF07FF03FF00FFh";
BA_ "GenSigCycleTime" SG_ 547 CRC_EPS_SDS_Resp 10;
BA_ "GenSigSNA" SG_ 547 CRC_EPS_SDS_Resp "FFh";
BA_ "GenSigStartValue" SG_ 547 CRC_EPS_SDS_Resp 255;
BA_ "FlexKomComment" SG_ 547 EPS_SDSTorqueApplied "EPS_SDS_Resp_Pkt";
BA_ "FlexKomIsMotorola" SG_ 547 EPS_SDSTorqueApplied 1;
BA_ "FlexKomSID" SG_ 547 EPS_SDSTorqueApplied 2594;
BA_ "FlexKomSigLaenge" SG_ 547 EPS_SDSTorqueApplied 32;
BA_ "FlexKomSigName" SG_ 547 EPS_SDSTorqueApplied "EPS_SDS_Resp_Pkt";
BA_ "FlexKomSigStartPos" SG_ 547 EPS_SDSTorqueApplied 7;
BA_ "FlexKomSigStartValue" SG_ 547 EPS_SDSTorqueApplied "07FF07FF03FF00FFh";
BA_ "GenSigCycleTime" SG_ 547 EPS_SDSTorqueApplied 10;
BA_ "GenSigSNA" SG_ 547 EPS_SDSTorqueApplied "7FFh";
BA_ "GenSigStartValue" SG_ 547 EPS_SDSTorqueApplied 2047;
BA_ "FlexKomComment" SG_ 547 MC_EPS_SDS_Resp "EPS_SDS_Resp_Pkt";
BA_ "FlexKomIsMotorola" SG_ 547 MC_EPS_SDS_Resp 1;
BA_ "FlexKomSID" SG_ 547 MC_EPS_SDS_Resp 2594;
BA_ "FlexKomSigLaenge" SG_ 547 MC_EPS_SDS_Resp 64;
BA_ "FlexKomSigName" SG_ 547 MC_EPS_SDS_Resp "EPS_SDS_Resp_Pkt";
BA_ "FlexKomSigStartPos" SG_ 547 MC_EPS_SDS_Resp 7;
BA_ "FlexKomSigStartValue" SG_ 547 MC_EPS_SDS_Resp "07FF07FF03FF00FFh";
BA_ "GenSigCycleTime" SG_ 547 MC_EPS_SDS_Resp 10;
BA_ "GenSigSNA" SG_ 547 MC_EPS_SDS_Resp "0h";
BA_ "FlexKomComment" SG_ 547 EPS_TemporaryDeactivationSDS "EPS_SDS_Resp_Pkt";
BA_ "FlexKomIsMotorola" SG_ 547 EPS_TemporaryDeactivationSDS 1;
BA_ "FlexKomSID" SG_ 547 EPS_TemporaryDeactivationSDS 2594;
BA_ "FlexKomSigLaenge" SG_ 547 EPS_TemporaryDeactivationSDS 64;
BA_ "FlexKomSigName" SG_ 547 EPS_TemporaryDeactivationSDS "EPS_SDS_Resp_Pkt";
BA_ "FlexKomSigStartPos" SG_ 547 EPS_TemporaryDeactivationSDS 7;
BA_ "FlexKomSigStartValue" SG_ 547 EPS_TemporaryDeactivationSDS "07FF07FF03FF00FFh";
BA_ "GenSigCycleTime" SG_ 547 EPS_TemporaryDeactivationSDS 10;
BA_ "GenSigSNA" SG_ 547 EPS_TemporaryDeactivationSDS "0h";
BA_ "FlexKomComment" SG_ 547 EPS_SDSTorqueOverlayFault "EPS_SDS_Resp_Pkt";
BA_ "FlexKomIsMotorola" SG_ 547 EPS_SDSTorqueOverlayFault 1;
BA_ "FlexKomSID" SG_ 547 EPS_SDSTorqueOverlayFault 2594;
BA_ "FlexKomSigLaenge" SG_ 547 EPS_SDSTorqueOverlayFault 64;
BA_ "FlexKomSigName" SG_ 547 EPS_SDSTorqueOverlayFault "EPS_SDS_Resp_Pkt";
BA_ "FlexKomSigStartPos" SG_ 547 EPS_SDSTorqueOverlayFault 7;
BA_ "FlexKomSigStartValue" SG_ 547 EPS_SDSTorqueOverlayFault "07FF07FF03FF00FFh";
BA_ "GenSigCycleTime" SG_ 547 EPS_SDSTorqueOverlayFault 10;
BA_ "GenSigSNA" SG_ 547 EPS_SDSTorqueOverlayFault "0h";
BA_ "FlexKomComment" SG_ 547 EPS_SDSTorqueOverlayIntActivated "EPS_SDS_Resp_Pkt";
BA_ "FlexKomIsMotorola" SG_ 547 EPS_SDSTorqueOverlayIntActivated 1;
BA_ "FlexKomSID" SG_ 547 EPS_SDSTorqueOverlayIntActivated 2594;
BA_ "FlexKomSigLaenge" SG_ 547 EPS_SDSTorqueOverlayIntActivated 64;
BA_ "FlexKomSigName" SG_ 547 EPS_SDSTorqueOverlayIntActivated "EPS_SDS_Resp_Pkt";
BA_ "FlexKomSigStartPos" SG_ 547 EPS_SDSTorqueOverlayIntActivated 7;
BA_ "FlexKomSigStartValue" SG_ 547 EPS_SDSTorqueOverlayIntActivated "07FF07FF03FF00FFh";
BA_ "GenSigCycleTime" SG_ 547 EPS_SDSTorqueOverlayIntActivated 10;
BA_ "GenSigSNA" SG_ 547 EPS_SDSTorqueOverlayIntActivated "0h";
BA_ "GenSigSNA" SG_ 546 MC_EPS_SteeringWheelStat "0h";
BA_ "GenSigCycleTime" SG_ 546 MC_EPS_SteeringWheelStat 10;
BA_ "FlexKomSigStartValue" SG_ 546 MC_EPS_SteeringWheelStat "7FFF7FFF00FFh";
BA_ "FlexKomSigStartPos" SG_ 546 MC_EPS_SteeringWheelStat 7;
BA_ "FlexKomSigName" SG_ 546 MC_EPS_SteeringWheelStat "EPS_SteeringWheelStat_Pkt";
BA_ "FlexKomSigLaenge" SG_ 546 MC_EPS_SteeringWheelStat 64;
BA_ "FlexKomSID" SG_ 546 MC_EPS_SteeringWheelStat 2596;
BA_ "FlexKomIsMotorola" SG_ 546 MC_EPS_SteeringWheelStat 1;
BA_ "FlexKomComment" SG_ 546 MC_EPS_SteeringWheelStat "EPS_SteeringWheelStat_Pkt";
BA_ "GenSigStartValue" SG_ 546 CRC_EPS_SteerAngle 255;
BA_ "GenSigSNA" SG_ 546 CRC_EPS_SteerAngle "FFh";
BA_ "GenSigCycleTime" SG_ 546 CRC_EPS_SteerAngle 10;
BA_ "FlexKomSigStartValue" SG_ 546 CRC_EPS_SteerAngle "7FFF7FFF00FFh";
BA_ "FlexKomSigStartPos" SG_ 546 CRC_EPS_SteerAngle 7;
BA_ "FlexKomSigName" SG_ 546 CRC_EPS_SteerAngle "EPS_SteeringWheelStat_Pkt";
BA_ "FlexKomSigLaenge" SG_ 546 CRC_EPS_SteerAngle 64;
BA_ "FlexKomSID" SG_ 546 CRC_EPS_SteerAngle 2596;
BA_ "FlexKomIsMotorola" SG_ 546 CRC_EPS_SteerAngle 1;
BA_ "FlexKomComment" SG_ 546 CRC_EPS_SteerAngle "EPS_SteeringWheelStat_Pkt";
BA_ "FlexKomComment" SG_ 546 EPS_SteerVelocity "EPS_SteeringWheelStat_Pkt";
BA_ "FlexKomIsMotorola" SG_ 546 EPS_SteerVelocity 1;
BA_ "FlexKomSID" SG_ 546 EPS_SteerVelocity 2596;
BA_ "FlexKomSigLaenge" SG_ 546 EPS_SteerVelocity 32;
BA_ "FlexKomSigName" SG_ 546 EPS_SteerVelocity "EPS_SteeringWheelStat_Pkt";
BA_ "FlexKomSigStartPos" SG_ 546 EPS_SteerVelocity 7;
BA_ "FlexKomSigStartValue" SG_ 546 EPS_SteerVelocity "7FFF7FFF00FFh";
BA_ "GenSigCycleTime" SG_ 546 EPS_SteerVelocity 10;
BA_ "GenSigSNA" SG_ 546 EPS_SteerVelocity "0x7FFFh";
BA_ "GenSigStartValue" SG_ 546 EPS_SteerVelocity 32767;
BA_ "FlexKomComment" SG_ 546 EPS_SteerAngle "EPS_SteeringWheelStat_Pkt";
BA_ "FlexKomIsMotorola" SG_ 546 EPS_SteerAngle 1;
BA_ "FlexKomSID" SG_ 546 EPS_SteerAngle 2596;
BA_ "FlexKomSigLaenge" SG_ 546 EPS_SteerAngle 32;
BA_ "FlexKomSigName" SG_ 546 EPS_SteerAngle "EPS_SteeringWheelStat_Pkt";
BA_ "FlexKomSigStartPos" SG_ 546 EPS_SteerAngle 7;
BA_ "FlexKomSigStartValue" SG_ 546 EPS_SteerAngle "7FFF7FFF00FFh";
BA_ "GenSigCycleTime" SG_ 546 EPS_SteerAngle 10;
BA_ "GenSigSNA" SG_ 546 EPS_SteerAngle "0x7FFF";
BA_ "GenSigStartValue" SG_ 546 EPS_SteerAngle 32767;
BA_ "FlexKomComment" SG_ 969 AMB_TEMP_AVG_C "Ambient temperature average - in degrees Celsius";
BA_ "FlexKomIsMotorola" SG_ 969 AMB_TEMP_AVG_C 1;
BA_ "FlexKomSID" SG_ 969 AMB_TEMP_AVG_C 1427;
BA_ "FlexKomSigLaenge" SG_ 969 AMB_TEMP_AVG_C 8;
BA_ "FlexKomSigName" SG_ 969 AMB_TEMP_AVG_C "AMB_TEMP_AVG_C";
BA_ "FlexKomSigStartPos" SG_ 969 AMB_TEMP_AVG_C 15;
BA_ "FlexKomSigStartValue" SG_ 969 AMB_TEMP_AVG_C "FFh";
BA_ "GenSigCycleTime" SG_ 969 AMB_TEMP_AVG_C 1000;
BA_ "GenSigSNA" SG_ 969 AMB_TEMP_AVG_C "FFh";
BA_ "GenSigStartValue" SG_ 969 AMB_TEMP_AVG_C 255;
BA_ "GenSigTimeout_IC" SG_ 969 AMB_TEMP_AVG_C 10500;
BA_ "FlexKomComment" SG_ 969 AMB_TEMP_AVG_F "Ambient temperature average - in degrees Fahrenhei";
BA_ "FlexKomIsMotorola" SG_ 969 AMB_TEMP_AVG_F 1;
BA_ "FlexKomSID" SG_ 969 AMB_TEMP_AVG_F 1428;
BA_ "FlexKomSigLaenge" SG_ 969 AMB_TEMP_AVG_F 8;
BA_ "FlexKomSigName" SG_ 969 AMB_TEMP_AVG_F "AMB_TEMP_AVG_F";
BA_ "FlexKomSigStartPos" SG_ 969 AMB_TEMP_AVG_F 7;
BA_ "FlexKomSigStartValue" SG_ 969 AMB_TEMP_AVG_F "FFh";
BA_ "GenSigCycleTime" SG_ 969 AMB_TEMP_AVG_F 1000;
BA_ "GenSigSNA" SG_ 969 AMB_TEMP_AVG_F "FFh";
BA_ "GenSigStartValue" SG_ 969 AMB_TEMP_AVG_F 255;
BA_ "GenSigTimeout_IC" SG_ 969 AMB_TEMP_AVG_F 10500;
BA_ "FlexKomComment" SG_ 1788 APPL_ECU_BSMO "External Application to ECU";
BA_ "FlexKomIsMotorola" SG_ 1788 APPL_ECU_BSMO 1;
BA_ "FlexKomSID" SG_ 1788 APPL_ECU_BSMO 2285;
BA_ "FlexKomSigLaenge" SG_ 1788 APPL_ECU_BSMO 64;
BA_ "FlexKomSigName" SG_ 1788 APPL_ECU_BSMO "APPL_ECU_BSMO";
BA_ "FlexKomSigStartPos" SG_ 1788 APPL_ECU_BSMO 7;
BA_ "FlexKomSigStartValue" SG_ 1788 APPL_ECU_BSMO "0000000000000000h";
BA_ "GenSigSendType" SG_ 1788 APPL_ECU_BSMO 1;
BA_ "GenSigSNA" SG_ 1788 APPL_ECU_BSMO "0h";
BA_ "FlexKomComment" SG_ 1729 APPL_ECU_CBC "External Application to ECU";
BA_ "FlexKomIsMotorola" SG_ 1729 APPL_ECU_CBC 1;
BA_ "FlexKomSID" SG_ 1729 APPL_ECU_CBC 280;
BA_ "FlexKomSigLaenge" SG_ 1729 APPL_ECU_CBC 64;
BA_ "FlexKomSigName" SG_ 1729 APPL_ECU_CBC "APPL_ECU_CBC";
BA_ "FlexKomSigStartPos" SG_ 1729 APPL_ECU_CBC 7;
BA_ "FlexKomSigStartValue" SG_ 1729 APPL_ECU_CBC "0000000000000000h";
BA_ "GenSigSendType" SG_ 1729 APPL_ECU_CBC 1;
BA_ "GenSigSNA" SG_ 1729 APPL_ECU_CBC "0h";
BA_ "FlexKomComment" SG_ 1747 APPL_ECU_DASM "External Application to ECU";
BA_ "FlexKomIsMotorola" SG_ 1747 APPL_ECU_DASM 1;
BA_ "FlexKomSID" SG_ 1747 APPL_ECU_DASM 298;
BA_ "FlexKomSigLaenge" SG_ 1747 APPL_ECU_DASM 64;
BA_ "FlexKomSigName" SG_ 1747 APPL_ECU_DASM "APPL_ECU_DASM";
BA_ "FlexKomSigStartPos" SG_ 1747 APPL_ECU_DASM 7;
BA_ "FlexKomSigStartValue" SG_ 1747 APPL_ECU_DASM "0000000000000000h";
BA_ "GenSigSendType" SG_ 1747 APPL_ECU_DASM 1;
BA_ "GenSigSNA" SG_ 1747 APPL_ECU_DASM "0h";
BA_ "FlexKomComment" SG_ 1787 APPL_ECU_EBCM "External Application to ECU";
BA_ "FlexKomIsMotorola" SG_ 1787 APPL_ECU_EBCM 1;
BA_ "FlexKomSID" SG_ 1787 APPL_ECU_EBCM 2149;
BA_ "FlexKomSigLaenge" SG_ 1787 APPL_ECU_EBCM 64;
BA_ "FlexKomSigName" SG_ 1787 APPL_ECU_EBCM "APPL_ECU_EBCM";
BA_ "FlexKomSigStartPos" SG_ 1787 APPL_ECU_EBCM 7;
BA_ "FlexKomSigStartValue" SG_ 1787 APPL_ECU_EBCM "0000000000000000h";
BA_ "GenSigSendType" SG_ 1787 APPL_ECU_EBCM 1;
BA_ "GenSigSNA" SG_ 1787 APPL_ECU_EBCM "0h";
BA_ "FlexKomComment" SG_ 1784 APPL_ECU_ECM "External Application to ECU";
BA_ "FlexKomIsMotorola" SG_ 1784 APPL_ECU_ECM 1;
BA_ "FlexKomSID" SG_ 1784 APPL_ECU_ECM 287;
BA_ "FlexKomSigLaenge" SG_ 1784 APPL_ECU_ECM 64;
BA_ "FlexKomSigName" SG_ 1784 APPL_ECU_ECM "APPL_ECU_ECM";
BA_ "FlexKomSigStartPos" SG_ 1784 APPL_ECU_ECM 7;
BA_ "FlexKomSigStartValue" SG_ 1784 APPL_ECU_ECM "0000000000000000h";
BA_ "GenSigSendType" SG_ 1784 APPL_ECU_ECM 1;
BA_ "GenSigSNA" SG_ 1784 APPL_ECU_ECM "0h";
BA_ "FlexKomComment" SG_ 1754 APPL_ECU_EPS "External Application to ECU";
BA_ "FlexKomIsMotorola" SG_ 1754 APPL_ECU_EPS 1;
BA_ "FlexKomSID" SG_ 1754 APPL_ECU_EPS 289;
BA_ "FlexKomSigLaenge" SG_ 1754 APPL_ECU_EPS 64;
BA_ "FlexKomSigName" SG_ 1754 APPL_ECU_EPS "APPL_ECU_EPS";
BA_ "FlexKomSigStartPos" SG_ 1754 APPL_ECU_EPS 7;
BA_ "FlexKomSigStartValue" SG_ 1754 APPL_ECU_EPS "0000000000000000h";
BA_ "GenSigSendType" SG_ 1754 APPL_ECU_EPS 1;
BA_ "GenSigSNA" SG_ 1754 APPL_ECU_EPS "0h";
BA_ "FlexKomComment" SG_ 1736 APPL_ECU_ESL "External Application to ECU";
BA_ "FlexKomIsMotorola" SG_ 1736 APPL_ECU_ESL 1;
BA_ "FlexKomSID" SG_ 1736 APPL_ECU_ESL 2338;
BA_ "FlexKomSigLaenge" SG_ 1736 APPL_ECU_ESL 64;
BA_ "FlexKomSigName" SG_ 1736 APPL_ECU_ESL "APPL_ECU_ESL";
BA_ "FlexKomSigStartPos" SG_ 1736 APPL_ECU_ESL 7;
BA_ "FlexKomSigStartValue" SG_ 1736 APPL_ECU_ESL "0000000000000000h";
BA_ "GenSigSendType" SG_ 1736 APPL_ECU_ESL 1;
BA_ "GenSigSNA" SG_ 1736 APPL_ECU_ESL "0h";
BA_ "FlexKomComment" SG_ 1737 APPL_ECU_ESM "External Application to ECU";
BA_ "FlexKomIsMotorola" SG_ 1737 APPL_ECU_ESM 1;
BA_ "FlexKomSID" SG_ 1737 APPL_ECU_ESM 290;
BA_ "FlexKomSigLaenge" SG_ 1737 APPL_ECU_ESM 64;
BA_ "FlexKomSigName" SG_ 1737 APPL_ECU_ESM "APPL_ECU_ESM";
BA_ "FlexKomSigStartPos" SG_ 1737 APPL_ECU_ESM 7;
BA_ "FlexKomSigStartValue" SG_ 1737 APPL_ECU_ESM "0000000000000000h";
BA_ "GenSigSendType" SG_ 1737 APPL_ECU_ESM 1;
BA_ "GenSigSNA" SG_ 1737 APPL_ECU_ESM "0h";
BA_ "RID" SG_ 1737 APPL_ECU_ESM "9609";
BA_ "FlexKomComment" SG_ 1764 APPL_ECU_HaLF "External Application to ECU";
BA_ "FlexKomIsMotorola" SG_ 1764 APPL_ECU_HaLF 1;
BA_ "FlexKomSID" SG_ 1764 APPL_ECU_HaLF 1631;
BA_ "FlexKomSigLaenge" SG_ 1764 APPL_ECU_HaLF 64;
BA_ "FlexKomSigName" SG_ 1764 APPL_ECU_HaLF "APPL_ECU_HaLF";
BA_ "FlexKomSigStartPos" SG_ 1764 APPL_ECU_HaLF 7;
BA_ "FlexKomSigStartValue" SG_ 1764 APPL_ECU_HaLF "0000000000000000h";
BA_ "GenSigSendType" SG_ 1764 APPL_ECU_HaLF 1;
BA_ "GenSigSNA" SG_ 1764 APPL_ECU_HaLF "0h";
BA_ "FlexKomComment" SG_ 1786 APPL_ECU_HCP "External Application to ECU";
BA_ "FlexKomIsMotorola" SG_ 1786 APPL_ECU_HCP 1;
BA_ "FlexKomSID" SG_ 1786 APPL_ECU_HCP 2117;
BA_ "FlexKomSigLaenge" SG_ 1786 APPL_ECU_HCP 64;
BA_ "FlexKomSigName" SG_ 1786 APPL_ECU_HCP "APPL_ECU_HCP";
BA_ "FlexKomSigStartPos" SG_ 1786 APPL_ECU_HCP 7;
BA_ "FlexKomSigStartValue" SG_ 1786 APPL_ECU_HCP "0000000000000000h";
BA_ "GenSigSendType" SG_ 1786 APPL_ECU_HCP 1;
BA_ "GenSigSNA" SG_ 1786 APPL_ECU_HCP "0h";
BA_ "FlexKomComment" SG_ 1730 APPL_ECU_IC "External Application to ECU";
BA_ "FlexKomIsMotorola" SG_ 1730 APPL_ECU_IC 1;
BA_ "FlexKomSID" SG_ 1730 APPL_ECU_IC 296;
BA_ "FlexKomSigLaenge" SG_ 1730 APPL_ECU_IC 64;
BA_ "FlexKomSigName" SG_ 1730 APPL_ECU_IC "APPL_ECU_IC";
BA_ "FlexKomSigStartPos" SG_ 1730 APPL_ECU_IC 7;
BA_ "FlexKomSigStartValue" SG_ 1730 APPL_ECU_IC "0000000000000000h";
BA_ "GenSigSendType" SG_ 1730 APPL_ECU_IC 1;
BA_ "GenSigSNA" SG_ 1730 APPL_ECU_IC "0h";
BA_ "FlexKomComment" SG_ 1758 APPL_ECU_OCM "External Application to ECU";
BA_ "FlexKomIsMotorola" SG_ 1758 APPL_ECU_OCM 1;
BA_ "FlexKomSID" SG_ 1758 APPL_ECU_OCM 1539;
BA_ "FlexKomSigLaenge" SG_ 1758 APPL_ECU_OCM 64;
BA_ "FlexKomSigName" SG_ 1758 APPL_ECU_OCM "APPL_ECU_OCM";
BA_ "FlexKomSigStartPos" SG_ 1758 APPL_ECU_OCM 7;
BA_ "FlexKomSigStartValue" SG_ 1758 APPL_ECU_OCM "0000000000000000h";
BA_ "GenSigSendType" SG_ 1758 APPL_ECU_OCM 1;
BA_ "GenSigSNA" SG_ 1758 APPL_ECU_OCM "0h";
BA_ "FlexKomComment" SG_ 1732 APPL_ECU_ORC "External Application to ECU";
BA_ "FlexKomIsMotorola" SG_ 1732 APPL_ECU_ORC 1;
BA_ "FlexKomSID" SG_ 1732 APPL_ECU_ORC 302;
BA_ "FlexKomSigLaenge" SG_ 1732 APPL_ECU_ORC 64;
BA_ "FlexKomSigName" SG_ 1732 APPL_ECU_ORC "APPL_ECU_ORC";
BA_ "FlexKomSigStartPos" SG_ 1732 APPL_ECU_ORC 7;
BA_ "FlexKomSigStartValue" SG_ 1732 APPL_ECU_ORC "0000000000000000h";
BA_ "GenSigSendType" SG_ 1732 APPL_ECU_ORC 1;
BA_ "GenSigSNA" SG_ 1732 APPL_ECU_ORC "0h";
BA_ "FlexKomComment" SG_ 1762 APPL_ECU_PTS "External Application to ECU";
BA_ "FlexKomIsMotorola" SG_ 1762 APPL_ECU_PTS 1;
BA_ "FlexKomSID" SG_ 1762 APPL_ECU_PTS 310;
BA_ "FlexKomSigLaenge" SG_ 1762 APPL_ECU_PTS 64;
BA_ "FlexKomSigName" SG_ 1762 APPL_ECU_PTS "APPL_ECU_PTS";
BA_ "FlexKomSigStartPos" SG_ 1762 APPL_ECU_PTS 7;
BA_ "FlexKomSigStartValue" SG_ 1762 APPL_ECU_PTS "0000000000000000h";
BA_ "GenSigSendType" SG_ 1762 APPL_ECU_PTS 1;
BA_ "GenSigSNA" SG_ 1762 APPL_ECU_PTS "0h";
BA_ "FlexKomComment" SG_ 1728 APPL_ECU_RF_HUB "External Application to ECU";
BA_ "FlexKomIsMotorola" SG_ 1728 APPL_ECU_RF_HUB 1;
BA_ "FlexKomSID" SG_ 1728 APPL_ECU_RF_HUB 293;
BA_ "FlexKomSigLaenge" SG_ 1728 APPL_ECU_RF_HUB 64;
BA_ "FlexKomSigName" SG_ 1728 APPL_ECU_RF_HUB "APPL_ECU_RF_HUB";
BA_ "FlexKomSigStartPos" SG_ 1728 APPL_ECU_RF_HUB 7;
BA_ "FlexKomSigStartValue" SG_ 1728 APPL_ECU_RF_HUB "0000000000000000h";
BA_ "GenSigSendType" SG_ 1728 APPL_ECU_RF_HUB 1;
BA_ "GenSigSNA" SG_ 1728 APPL_ECU_RF_HUB "0h";
BA_ "FlexKomComment" SG_ 1763 APPL_ECU_SCCM "External Application to ECU";
BA_ "FlexKomIsMotorola" SG_ 1763 APPL_ECU_SCCM 1;
BA_ "FlexKomSID" SG_ 1763 APPL_ECU_SCCM 314;
BA_ "FlexKomSigLaenge" SG_ 1763 APPL_ECU_SCCM 64;
BA_ "FlexKomSigName" SG_ 1763 APPL_ECU_SCCM "APPL_ECU_SCCM";
BA_ "FlexKomSigStartPos" SG_ 1763 APPL_ECU_SCCM 7;
BA_ "FlexKomSigStartValue" SG_ 1763 APPL_ECU_SCCM "0000000000000000h";
BA_ "GenSigSendType" SG_ 1763 APPL_ECU_SCCM 1;
BA_ "GenSigSNA" SG_ 1763 APPL_ECU_SCCM "0h";
BA_ "FlexKomComment" SG_ 838 AS_CHIME_TYPE "AS chime status";
BA_ "FlexKomIsMotorola" SG_ 838 AS_CHIME_TYPE 1;
BA_ "FlexKomSID" SG_ 838 AS_CHIME_TYPE 1016;
BA_ "FlexKomSigLaenge" SG_ 838 AS_CHIME_TYPE 16;
BA_ "FlexKomSigName" SG_ 838 AS_CHIME_TYPE "AS_CHIME_STAT";
BA_ "FlexKomSigStartPos" SG_ 838 AS_CHIME_TYPE 7;
BA_ "FlexKomSigStartValue" SG_ 838 AS_CHIME_TYPE "0000h";
BA_ "GenSigCycleTime" SG_ 838 AS_CHIME_TYPE 1000;
BA_ "GenSigSendType" SG_ 838 AS_CHIME_TYPE 5;
BA_ "GenSigSNA" SG_ 838 AS_CHIME_TYPE "Fh";
BA_ "GenSigTimeout_IC" SG_ 838 AS_CHIME_TYPE 10500;
BA_ "GenSigTimeout_ORC" SG_ 838 AS_CHIME_TYPE 3500;
BA_ "RID" SG_ 838 AS_CHIME_TYPE "1056";
BA_ "FlexKomComment" SG_ 838 AS_LF_CHIME_RQ "AS chime status";
BA_ "FlexKomIsMotorola" SG_ 838 AS_LF_CHIME_RQ 1;
BA_ "FlexKomSID" SG_ 838 AS_LF_CHIME_RQ 1016;
BA_ "FlexKomSigLaenge" SG_ 838 AS_LF_CHIME_RQ 16;
BA_ "FlexKomSigName" SG_ 838 AS_LF_CHIME_RQ "AS_CHIME_STAT";
BA_ "FlexKomSigStartPos" SG_ 838 AS_LF_CHIME_RQ 7;
BA_ "FlexKomSigStartValue" SG_ 838 AS_LF_CHIME_RQ "0000h";
BA_ "GenSigCycleTime" SG_ 838 AS_LF_CHIME_RQ 1000;
BA_ "GenSigSendType" SG_ 838 AS_LF_CHIME_RQ 5;
BA_ "GenSigSNA" SG_ 838 AS_LF_CHIME_RQ "0h";
BA_ "RID" SG_ 838 AS_LF_CHIME_RQ "1121";
BA_ "FlexKomComment" SG_ 838 AS_RF_CHIME_RQ "AS chime status";
BA_ "FlexKomIsMotorola" SG_ 838 AS_RF_CHIME_RQ 1;
BA_ "FlexKomSID" SG_ 838 AS_RF_CHIME_RQ 1016;
BA_ "FlexKomSigLaenge" SG_ 838 AS_RF_CHIME_RQ 16;
BA_ "FlexKomSigName" SG_ 838 AS_RF_CHIME_RQ "AS_CHIME_STAT";
BA_ "FlexKomSigStartPos" SG_ 838 AS_RF_CHIME_RQ 7;
BA_ "FlexKomSigStartValue" SG_ 838 AS_RF_CHIME_RQ "0000h";
BA_ "GenSigCycleTime" SG_ 838 AS_RF_CHIME_RQ 1000;
BA_ "GenSigSendType" SG_ 838 AS_RF_CHIME_RQ 5;
BA_ "GenSigSNA" SG_ 838 AS_RF_CHIME_RQ "0h";
BA_ "RID" SG_ 838 AS_RF_CHIME_RQ "1245";
BA_ "FlexKomComment" SG_ 168 CRC_0A8h ".";
BA_ "FlexKomIsMotorola" SG_ 168 CRC_0A8h 1;
BA_ "FlexKomSID" SG_ 168 CRC_0A8h 2291;
BA_ "FlexKomSigLaenge" SG_ 168 CRC_0A8h 64;
BA_ "FlexKomSigName" SG_ 168 CRC_0A8h "Axle_Torque_Information";
BA_ "FlexKomSigStartPos" SG_ 168 CRC_0A8h 7;
BA_ "FlexKomSigStartValue" SG_ 168 CRC_0A8h "0B830B830B8300FFh";
BA_ "GenSigCycleTime" SG_ 168 CRC_0A8h 10;
BA_ "GenSigSNA" SG_ 168 CRC_0A8h "FFh";
BA_ "GenSigStartValue" SG_ 168 CRC_0A8h 255;
BA_ "FlexKomComment" SG_ 168 DrvrIntndedAxleTorq ".";
BA_ "FlexKomIsMotorola" SG_ 168 DrvrIntndedAxleTorq 1;
BA_ "FlexKomSID" SG_ 168 DrvrIntndedAxleTorq 2291;
BA_ "FlexKomSigLaenge" SG_ 168 DrvrIntndedAxleTorq 64;
BA_ "FlexKomSigName" SG_ 168 DrvrIntndedAxleTorq "Axle_Torque_Information";
BA_ "FlexKomSigStartPos" SG_ 168 DrvrIntndedAxleTorq 7;
BA_ "FlexKomSigStartValue" SG_ 168 DrvrIntndedAxleTorq "0B830B830B8300FFh";
BA_ "GenSigCycleTime" SG_ 168 DrvrIntndedAxleTorq 10;
BA_ "GenSigSNA" SG_ 168 DrvrIntndedAxleTorq "3FFFh";
BA_ "GenSigStartValue" SG_ 168 DrvrIntndedAxleTorq 2947;
BA_ "FlexKomComment" SG_ 168 MC_0A8h ".";
BA_ "FlexKomIsMotorola" SG_ 168 MC_0A8h 1;
BA_ "FlexKomSID" SG_ 168 MC_0A8h 2291;
BA_ "FlexKomSigLaenge" SG_ 168 MC_0A8h 64;
BA_ "FlexKomSigName" SG_ 168 MC_0A8h "Axle_Torque_Information";
BA_ "FlexKomSigStartPos" SG_ 168 MC_0A8h 7;
BA_ "FlexKomSigStartValue" SG_ 168 MC_0A8h "0B830B830B8300FFh";
BA_ "GenSigCycleTime" SG_ 168 MC_0A8h 10;
BA_ "GenSigSNA" SG_ 168 MC_0A8h "0h";
BA_ "FlexKomComment" SG_ 523 ControlEncodingESL "Code steering lock request packet";
BA_ "FlexKomIsMotorola" SG_ 523 ControlEncodingESL 1;
BA_ "FlexKomSID" SG_ 523 ControlEncodingESL 2345;
BA_ "FlexKomSigLaenge" SG_ 523 ControlEncodingESL 64;
BA_ "FlexKomSigName" SG_ 523 ControlEncodingESL "Code_ESL_RqPkt";
BA_ "FlexKomSigStartPos" SG_ 523 ControlEncodingESL 7;
BA_ "FlexKomSigStartValue" SG_ 523 ControlEncodingESL "0000000000000000h";
BA_ "GenSigSendType" SG_ 523 ControlEncodingESL 1;
BA_ "GenSigSNA" SG_ 523 ControlEncodingESL "0h";
BA_ "FlexKomComment" SG_ 523 ESLLockUnlockReq "Code steering lock request packet";
BA_ "FlexKomIsMotorola" SG_ 523 ESLLockUnlockReq 1;
BA_ "FlexKomSID" SG_ 523 ESLLockUnlockReq 2345;
BA_ "FlexKomSigLaenge" SG_ 523 ESLLockUnlockReq 64;
BA_ "FlexKomSigName" SG_ 523 ESLLockUnlockReq "Code_ESL_RqPkt";
BA_ "FlexKomSigStartPos" SG_ 523 ESLLockUnlockReq 7;
BA_ "FlexKomSigStartValue" SG_ 523 ESLLockUnlockReq "0000000000000000h";
BA_ "GenSigSendType" SG_ 523 ESLLockUnlockReq 1;
BA_ "GenSigSNA" SG_ 523 ESLLockUnlockReq "0h";
BA_ "FlexKomComment" SG_ 523 MiniCryptFCodeESL "Code steering lock request packet";
BA_ "FlexKomIsMotorola" SG_ 523 MiniCryptFCodeESL 1;
BA_ "FlexKomSID" SG_ 523 MiniCryptFCodeESL 2345;
BA_ "FlexKomSigLaenge" SG_ 523 MiniCryptFCodeESL 64;
BA_ "FlexKomSigName" SG_ 523 MiniCryptFCodeESL "Code_ESL_RqPkt";
BA_ "FlexKomSigStartPos" SG_ 523 MiniCryptFCodeESL 7;
BA_ "FlexKomSigStartValue" SG_ 523 MiniCryptFCodeESL "0000000000000000h";
BA_ "GenSigSendType" SG_ 523 MiniCryptFCodeESL 1;
BA_ "GenSigSNA" SG_ 523 MiniCryptFCodeESL "0h";
BA_ "FlexKomComment" SG_ 523 MiniCrypt_RndESL "Code steering lock request packet";
BA_ "FlexKomIsMotorola" SG_ 523 MiniCrypt_RndESL 1;
BA_ "FlexKomSID" SG_ 523 MiniCrypt_RndESL 2345;
BA_ "FlexKomSigLaenge" SG_ 523 MiniCrypt_RndESL 64;
BA_ "FlexKomSigName" SG_ 523 MiniCrypt_RndESL "Code_ESL_RqPkt";
BA_ "FlexKomSigStartPos" SG_ 523 MiniCrypt_RndESL 7;
BA_ "FlexKomSigStartValue" SG_ 523 MiniCrypt_RndESL "0000000000000000h";
BA_ "GenSigSendType" SG_ 523 MiniCrypt_RndESL 1;
BA_ "GenSigSNA" SG_ 523 MiniCrypt_RndESL "0h";
BA_ "FlexKomComment" SG_ 524 ControlEncodingBCM "Code transponder request packet";
BA_ "FlexKomIsMotorola" SG_ 524 ControlEncodingBCM 1;
BA_ "FlexKomSID" SG_ 524 ControlEncodingBCM 2331;
BA_ "FlexKomSigLaenge" SG_ 524 ControlEncodingBCM 64;
BA_ "FlexKomSigName" SG_ 524 ControlEncodingBCM "Code_TRM_RqPkt";
BA_ "FlexKomSigStartPos" SG_ 524 ControlEncodingBCM 7;
BA_ "FlexKomSigStartValue" SG_ 524 ControlEncodingBCM "0000000000000000h";
BA_ "GenSigSendType" SG_ 524 ControlEncodingBCM 1;
BA_ "GenSigSNA" SG_ 524 ControlEncodingBCM "0h";
BA_ "FlexKomComment" SG_ 524 MiniCryptFCode "Code transponder request packet";
BA_ "FlexKomIsMotorola" SG_ 524 MiniCryptFCode 1;
BA_ "FlexKomSID" SG_ 524 MiniCryptFCode 2331;
BA_ "FlexKomSigLaenge" SG_ 524 MiniCryptFCode 64;
BA_ "FlexKomSigName" SG_ 524 MiniCryptFCode "Code_TRM_RqPkt";
BA_ "FlexKomSigStartPos" SG_ 524 MiniCryptFCode 7;
BA_ "FlexKomSigStartValue" SG_ 524 MiniCryptFCode "0000000000000000h";
BA_ "GenSigSendType" SG_ 524 MiniCryptFCode 1;
BA_ "GenSigSNA" SG_ 524 MiniCryptFCode "0h";
BA_ "FlexKomComment" SG_ 524 MiniCrypt_Rnd "Code transponder request packet";
BA_ "FlexKomIsMotorola" SG_ 524 MiniCrypt_Rnd 1;
BA_ "FlexKomSID" SG_ 524 MiniCrypt_Rnd 2331;
BA_ "FlexKomSigLaenge" SG_ 524 MiniCrypt_Rnd 64;
BA_ "FlexKomSigName" SG_ 524 MiniCrypt_Rnd "Code_TRM_RqPkt";
BA_ "FlexKomSigStartPos" SG_ 524 MiniCrypt_Rnd 7;
BA_ "FlexKomSigStartValue" SG_ 524 MiniCrypt_Rnd "0000000000000000h";
BA_ "GenSigSendType" SG_ 524 MiniCrypt_Rnd 1;
BA_ "GenSigSNA" SG_ 524 MiniCrypt_Rnd "0h";
BA_ "FlexKomComment" SG_ 524 TxpAuthRequest "Code transponder request packet";
BA_ "FlexKomIsMotorola" SG_ 524 TxpAuthRequest 1;
BA_ "FlexKomSID" SG_ 524 TxpAuthRequest 2331;
BA_ "FlexKomSigLaenge" SG_ 524 TxpAuthRequest 64;
BA_ "FlexKomSigName" SG_ 524 TxpAuthRequest "Code_TRM_RqPkt";
BA_ "FlexKomSigStartPos" SG_ 524 TxpAuthRequest 7;
BA_ "FlexKomSigStartValue" SG_ 524 TxpAuthRequest "0000000000000000h";
BA_ "GenSigSendType" SG_ 524 TxpAuthRequest 1;
BA_ "GenSigSNA" SG_ 524 TxpAuthRequest "0h";
BA_ "FlexKomComment" SG_ 524 TxpReadRequest "Code transponder request packet";
BA_ "FlexKomIsMotorola" SG_ 524 TxpReadRequest 1;
BA_ "FlexKomSID" SG_ 524 TxpReadRequest 2331;
BA_ "FlexKomSigLaenge" SG_ 524 TxpReadRequest 64;
BA_ "FlexKomSigName" SG_ 524 TxpReadRequest "Code_TRM_RqPkt";
BA_ "FlexKomSigStartPos" SG_ 524 TxpReadRequest 7;
BA_ "FlexKomSigStartValue" SG_ 524 TxpReadRequest "0000000000000000h";
BA_ "GenSigSendType" SG_ 524 TxpReadRequest 1;
BA_ "GenSigSNA" SG_ 524 TxpReadRequest "0h";
BA_ "FlexKomComment" SG_ 525 MinicryptReceptionSts "Minicrypt acknowledge packet";
BA_ "FlexKomIsMotorola" SG_ 525 MinicryptReceptionSts 1;
BA_ "FlexKomSID" SG_ 525 MinicryptReceptionSts 2332;
BA_ "FlexKomSigLaenge" SG_ 525 MinicryptReceptionSts 8;
BA_ "FlexKomSigName" SG_ 525 MinicryptReceptionSts "Minicrypt_AckPkt";
BA_ "FlexKomSigStartPos" SG_ 525 MinicryptReceptionSts 7;
BA_ "FlexKomSigStartValue" SG_ 525 MinicryptReceptionSts "00h";
BA_ "GenSigSendType" SG_ 525 MinicryptReceptionSts 1;
BA_ "GenSigSNA" SG_ 525 MinicryptReceptionSts "0h";
BA_ "FlexKomComment" SG_ 720 BSM_Blind_RQ "Sensor blinded request from BSM; 1= sensor blocked";
BA_ "FlexKomIsMotorola" SG_ 720 BSM_Blind_RQ 1;
BA_ "FlexKomSID" SG_ 720 BSM_Blind_RQ 1362;
BA_ "FlexKomSigLaenge" SG_ 720 BSM_Blind_RQ 1;
BA_ "FlexKomSigName" SG_ 720 BSM_Blind_RQ "BSM_Blind_RQ";
BA_ "FlexKomSigStartPos" SG_ 720 BSM_Blind_RQ 13;
BA_ "FlexKomSigStartValue" SG_ 720 BSM_Blind_RQ "00h";
BA_ "GenSigCycleTime" SG_ 720 BSM_Blind_RQ 500;
BA_ "GenSigSendType" SG_ 720 BSM_Blind_RQ 5;
BA_ "GenSigSNA" SG_ 720 BSM_Blind_RQ "0h";
BA_ "GenSigTimeout_HaLF" SG_ 720 BSM_Blind_RQ 5250;
BA_ "GenSigTimeout_IC" SG_ 720 BSM_Blind_RQ 5250;
BA_ "RID" SG_ 720 BSM_Blind_RQ "1158";
BA_ "FlexKomComment" SG_ 720 BSM_CFG_STAT "BSM configuration status";
BA_ "FlexKomIsMotorola" SG_ 720 BSM_CFG_STAT 1;
BA_ "FlexKomSID" SG_ 720 BSM_CFG_STAT 4;
BA_ "FlexKomSigLaenge" SG_ 720 BSM_CFG_STAT 2;
BA_ "FlexKomSigName" SG_ 720 BSM_CFG_STAT "BSM_CFG_STAT";
BA_ "FlexKomSigStartPos" SG_ 720 BSM_CFG_STAT 9;
BA_ "FlexKomSigStartValue" SG_ 720 BSM_CFG_STAT "03h";
BA_ "GenSigCycleTime" SG_ 720 BSM_CFG_STAT 500;
BA_ "GenSigSendType" SG_ 720 BSM_CFG_STAT 5;
BA_ "GenSigSNA" SG_ 720 BSM_CFG_STAT "3h";
BA_ "GenSigStartValue" SG_ 720 BSM_CFG_STAT 3;
BA_ "GenSigTimeout_HaLF" SG_ 720 BSM_CFG_STAT 5250;
BA_ "GenSigTimeout_IC" SG_ 720 BSM_CFG_STAT 5250;
BA_ "RID" SG_ 720 BSM_CFG_STAT "1248";
BA_ "FlexKomComment" SG_ 720 BSM_CFG_STAT_TeenKey "BSM configuration status for teen key";
BA_ "FlexKomIsMotorola" SG_ 720 BSM_CFG_STAT_TeenKey 1;
BA_ "FlexKomSID" SG_ 720 BSM_CFG_STAT_TeenKey 2328;
BA_ "FlexKomSigLaenge" SG_ 720 BSM_CFG_STAT_TeenKey 2;
BA_ "FlexKomSigName" SG_ 720 BSM_CFG_STAT_TeenKey "BSM_CFG_STAT_TeenKey";
BA_ "FlexKomSigStartPos" SG_ 720 BSM_CFG_STAT_TeenKey 23;
BA_ "FlexKomSigStartValue" SG_ 720 BSM_CFG_STAT_TeenKey "03h";
BA_ "GenSigCycleTime" SG_ 720 BSM_CFG_STAT_TeenKey 500;
BA_ "GenSigSendType" SG_ 720 BSM_CFG_STAT_TeenKey 5;
BA_ "GenSigSNA" SG_ 720 BSM_CFG_STAT_TeenKey "3h";
BA_ "GenSigStartValue" SG_ 720 BSM_CFG_STAT_TeenKey 3;
BA_ "RID" SG_ 720 BSM_CFG_STAT_TeenKey "2164";
BA_ "FlexKomComment" SG_ 720 BSM_LT_WRN "Blind spot detection warning status";
BA_ "FlexKomIsMotorola" SG_ 720 BSM_LT_WRN 1;
BA_ "FlexKomSID" SG_ 720 BSM_LT_WRN 9;
BA_ "FlexKomSigLaenge" SG_ 720 BSM_LT_WRN 6;
BA_ "FlexKomSigName" SG_ 720 BSM_LT_WRN "BSM_WRN";
BA_ "FlexKomSigStartPos" SG_ 720 BSM_LT_WRN 5;
BA_ "FlexKomSigStartValue" SG_ 720 BSM_LT_WRN "00h";
BA_ "GenSigCycleTime" SG_ 720 BSM_LT_WRN 500;
BA_ "GenSigSendType" SG_ 720 BSM_LT_WRN 5;
BA_ "GenSigSNA" SG_ 720 BSM_LT_WRN "7h";
BA_ "GenSigTimeout_HaLF" SG_ 720 BSM_LT_WRN 5250;
BA_ "GenSigTimeout_IC" SG_ 720 BSM_LT_WRN 5250;
BA_ "RID" SG_ 720 BSM_LT_WRN "1209";
BA_ "FlexKomComment" SG_ 720 BSM_OPR_STAT "BSM operation status; 1= operational failure";
BA_ "FlexKomIsMotorola" SG_ 720 BSM_OPR_STAT 1;
BA_ "FlexKomSID" SG_ 720 BSM_OPR_STAT 7;
BA_ "FlexKomSigLaenge" SG_ 720 BSM_OPR_STAT 1;
BA_ "FlexKomSigName" SG_ 720 BSM_OPR_STAT "BSM_OPR_STAT";
BA_ "FlexKomSigStartPos" SG_ 720 BSM_OPR_STAT 11;
BA_ "FlexKomSigStartValue" SG_ 720 BSM_OPR_STAT "00h";
BA_ "GenSigCycleTime" SG_ 720 BSM_OPR_STAT 500;
BA_ "GenSigSendType" SG_ 720 BSM_OPR_STAT 5;
BA_ "GenSigSNA" SG_ 720 BSM_OPR_STAT "0h";
BA_ "GenSigTimeout_HaLF" SG_ 720 BSM_OPR_STAT 5250;
BA_ "GenSigTimeout_IC" SG_ 720 BSM_OPR_STAT 5250;
BA_ "RID" SG_ 720 BSM_OPR_STAT "1115";
BA_ "FlexKomComment" SG_ 720 BSM_RT_WRN "Blind spot detection warning status";
BA_ "FlexKomIsMotorola" SG_ 720 BSM_RT_WRN 1;
BA_ "FlexKomSID" SG_ 720 BSM_RT_WRN 9;
BA_ "FlexKomSigLaenge" SG_ 720 BSM_RT_WRN 6;
BA_ "FlexKomSigName" SG_ 720 BSM_RT_WRN "BSM_WRN";
BA_ "FlexKomSigStartPos" SG_ 720 BSM_RT_WRN 5;
BA_ "FlexKomSigStartValue" SG_ 720 BSM_RT_WRN "00h";
BA_ "GenSigCycleTime" SG_ 720 BSM_RT_WRN 500;
BA_ "GenSigSendType" SG_ 720 BSM_RT_WRN 5;
BA_ "GenSigSNA" SG_ 720 BSM_RT_WRN "7h";
BA_ "GenSigTimeout_HaLF" SG_ 720 BSM_RT_WRN 5250;
BA_ "GenSigTimeout_IC" SG_ 720 BSM_RT_WRN 5250;
BA_ "RID" SG_ 720 BSM_RT_WRN "1169";
BA_ "FlexKomComment" SG_ 720 BSM_SRV_RQ "BSM service warning request; 1= service request";
BA_ "FlexKomIsMotorola" SG_ 720 BSM_SRV_RQ 1;
BA_ "FlexKomSID" SG_ 720 BSM_SRV_RQ 6;
BA_ "FlexKomSigLaenge" SG_ 720 BSM_SRV_RQ 1;
BA_ "FlexKomSigName" SG_ 720 BSM_SRV_RQ "BSM_SRV_RQ";
BA_ "FlexKomSigStartPos" SG_ 720 BSM_SRV_RQ 10;
BA_ "FlexKomSigStartValue" SG_ 720 BSM_SRV_RQ "00h";
BA_ "GenSigCycleTime" SG_ 720 BSM_SRV_RQ 500;
BA_ "GenSigSendType" SG_ 720 BSM_SRV_RQ 5;
BA_ "GenSigSNA" SG_ 720 BSM_SRV_RQ "0h";
BA_ "GenSigTimeout_HaLF" SG_ 720 BSM_SRV_RQ 5250;
BA_ "GenSigTimeout_IC" SG_ 720 BSM_SRV_RQ 5250;
BA_ "RID" SG_ 720 BSM_SRV_RQ "1242";
BA_ "FlexKomComment" SG_ 998 BU_NET_CFG_STAT_INT "Backup for network ECU config data for interior";
BA_ "FlexKomIsMotorola" SG_ 998 BU_NET_CFG_STAT_INT 1;
BA_ "FlexKomSID" SG_ 998 BU_NET_CFG_STAT_INT 871;
BA_ "FlexKomSigLaenge" SG_ 998 BU_NET_CFG_STAT_INT 64;
BA_ "FlexKomSigName" SG_ 998 BU_NET_CFG_STAT_INT "BU_NET_CFG_DATA_INT";
BA_ "FlexKomSigStartPos" SG_ 998 BU_NET_CFG_STAT_INT 7;
BA_ "FlexKomSigStartValue" SG_ 998 BU_NET_CFG_STAT_INT "0300000000000000h";
BA_ "GenSigSendType" SG_ 998 BU_NET_CFG_STAT_INT 1;
BA_ "GenSigSNA" SG_ 998 BU_NET_CFG_STAT_INT "3h";
BA_ "GenSigStartValue" SG_ 998 BU_NET_CFG_STAT_INT 3;
BA_ "FlexKomComment" SG_ 998 BU_NetCfg_AMP_I "Backup for network ECU config data for interior";
BA_ "FlexKomIsMotorola" SG_ 998 BU_NetCfg_AMP_I 1;
BA_ "FlexKomSID" SG_ 998 BU_NetCfg_AMP_I 871;
BA_ "FlexKomSigLaenge" SG_ 998 BU_NetCfg_AMP_I 64;
BA_ "FlexKomSigName" SG_ 998 BU_NetCfg_AMP_I "BU_NET_CFG_DATA_INT";
BA_ "FlexKomSigStartPos" SG_ 998 BU_NetCfg_AMP_I 7;
BA_ "FlexKomSigStartValue" SG_ 998 BU_NetCfg_AMP_I "0300000000000000h";
BA_ "GenSigSendType" SG_ 998 BU_NetCfg_AMP_I 1;
BA_ "GenSigSNA" SG_ 998 BU_NetCfg_AMP_I "0h";
BA_ "FlexKomComment" SG_ 998 BU_NetCfg_ANC_I "Backup for network ECU config data for interior";
BA_ "FlexKomIsMotorola" SG_ 998 BU_NetCfg_ANC_I 1;
BA_ "FlexKomSID" SG_ 998 BU_NetCfg_ANC_I 871;
BA_ "FlexKomSigLaenge" SG_ 998 BU_NetCfg_ANC_I 64;
BA_ "FlexKomSigName" SG_ 998 BU_NetCfg_ANC_I "BU_NET_CFG_DATA_INT";
BA_ "FlexKomSigStartPos" SG_ 998 BU_NetCfg_ANC_I 7;
BA_ "FlexKomSigStartValue" SG_ 998 BU_NetCfg_ANC_I "0300000000000000h";
BA_ "GenSigSendType" SG_ 998 BU_NetCfg_ANC_I 1;
BA_ "GenSigSNA" SG_ 998 BU_NetCfg_ANC_I "0h";
BA_ "FlexKomComment" SG_ 998 BU_NetCfg_BSM "Backup for network ECU config data for interior";
BA_ "FlexKomIsMotorola" SG_ 998 BU_NetCfg_BSM 1;
BA_ "FlexKomSID" SG_ 998 BU_NetCfg_BSM 871;
BA_ "FlexKomSigLaenge" SG_ 998 BU_NetCfg_BSM 64;
BA_ "FlexKomSigName" SG_ 998 BU_NetCfg_BSM "BU_NET_CFG_DATA_INT";
BA_ "FlexKomSigStartPos" SG_ 998 BU_NetCfg_BSM 7;
BA_ "FlexKomSigStartValue" SG_ 998 BU_NetCfg_BSM "0300000000000000h";
BA_ "GenSigSendType" SG_ 998 BU_NetCfg_BSM 1;
BA_ "GenSigSNA" SG_ 998 BU_NetCfg_BSM "0h";
BA_ "FlexKomComment" SG_ 998 BU_NetCfg_CBC_IN "Backup for network ECU config data for interior";
BA_ "FlexKomIsMotorola" SG_ 998 BU_NetCfg_CBC_IN 1;
BA_ "FlexKomSID" SG_ 998 BU_NetCfg_CBC_IN 871;
BA_ "FlexKomSigLaenge" SG_ 998 BU_NetCfg_CBC_IN 64;
BA_ "FlexKomSigName" SG_ 998 BU_NetCfg_CBC_IN "BU_NET_CFG_DATA_INT";
BA_ "FlexKomSigStartPos" SG_ 998 BU_NetCfg_CBC_IN 7;
BA_ "FlexKomSigStartValue" SG_ 998 BU_NetCfg_CBC_IN "0300000000000000h";
BA_ "GenSigSendType" SG_ 998 BU_NetCfg_CBC_IN 1;
BA_ "GenSigSNA" SG_ 998 BU_NetCfg_CBC_IN "0h";
BA_ "FlexKomComment" SG_ 998 BU_NetCfg_CLOCK "Backup for network ECU config data for interior";
BA_ "FlexKomIsMotorola" SG_ 998 BU_NetCfg_CLOCK 1;
BA_ "FlexKomSID" SG_ 998 BU_NetCfg_CLOCK 871;
BA_ "FlexKomSigLaenge" SG_ 998 BU_NetCfg_CLOCK 64;
BA_ "FlexKomSigName" SG_ 998 BU_NetCfg_CLOCK "BU_NET_CFG_DATA_INT";
BA_ "FlexKomSigStartPos" SG_ 998 BU_NetCfg_CLOCK 7;
BA_ "FlexKomSigStartValue" SG_ 998 BU_NetCfg_CLOCK "0300000000000000h";
BA_ "GenSigSendType" SG_ 998 BU_NetCfg_CLOCK 1;
BA_ "GenSigSNA" SG_ 998 BU_NetCfg_CLOCK "0h";
BA_ "FlexKomComment" SG_ 998 BU_NetCfg_CRSM "Backup for network ECU config data for interior";
BA_ "FlexKomIsMotorola" SG_ 998 BU_NetCfg_CRSM 1;
BA_ "FlexKomSID" SG_ 998 BU_NetCfg_CRSM 871;
BA_ "FlexKomSigLaenge" SG_ 998 BU_NetCfg_CRSM 64;
BA_ "FlexKomSigName" SG_ 998 BU_NetCfg_CRSM "BU_NET_CFG_DATA_INT";
BA_ "FlexKomSigStartPos" SG_ 998 BU_NetCfg_CRSM 7;
BA_ "FlexKomSigStartValue" SG_ 998 BU_NetCfg_CRSM "0300000000000000h";
BA_ "GenSigSendType" SG_ 998 BU_NetCfg_CRSM 1;
BA_ "GenSigSNA" SG_ 998 BU_NetCfg_CRSM "0h";
BA_ "FlexKomComment" SG_ 998 BU_NetCfg_CSWM "Backup for network ECU config data for interior";
BA_ "FlexKomIsMotorola" SG_ 998 BU_NetCfg_CSWM 1;
BA_ "FlexKomSID" SG_ 998 BU_NetCfg_CSWM 871;
BA_ "FlexKomSigLaenge" SG_ 998 BU_NetCfg_CSWM 64;
BA_ "FlexKomSigName" SG_ 998 BU_NetCfg_CSWM "BU_NET_CFG_DATA_INT";
BA_ "FlexKomSigStartPos" SG_ 998 BU_NetCfg_CSWM 7;
BA_ "FlexKomSigStartValue" SG_ 998 BU_NetCfg_CSWM "0300000000000000h";
BA_ "GenSigSendType" SG_ 998 BU_NetCfg_CSWM 1;
BA_ "GenSigSNA" SG_ 998 BU_NetCfg_CSWM "0h";
BA_ "FlexKomComment" SG_ 998 BU_NetCfg_CVPM "Backup for network ECU config data for interior";
BA_ "FlexKomIsMotorola" SG_ 998 BU_NetCfg_CVPM 1;
BA_ "FlexKomSID" SG_ 998 BU_NetCfg_CVPM 871;
BA_ "FlexKomSigLaenge" SG_ 998 BU_NetCfg_CVPM 64;
BA_ "FlexKomSigName" SG_ 998 BU_NetCfg_CVPM "BU_NET_CFG_DATA_INT";
BA_ "FlexKomSigStartPos" SG_ 998 BU_NetCfg_CVPM 7;
BA_ "FlexKomSigStartValue" SG_ 998 BU_NetCfg_CVPM "0300000000000000h";
BA_ "GenSigSendType" SG_ 998 BU_NetCfg_CVPM 1;
BA_ "GenSigSNA" SG_ 998 BU_NetCfg_CVPM "0h";
BA_ "FlexKomComment" SG_ 998 BU_NetCfg_DCM_DR "Backup for network ECU config data for interior";
BA_ "FlexKomIsMotorola" SG_ 998 BU_NetCfg_DCM_DR 1;
BA_ "FlexKomSID" SG_ 998 BU_NetCfg_DCM_DR 871;
BA_ "FlexKomSigLaenge" SG_ 998 BU_NetCfg_DCM_DR 64;
BA_ "FlexKomSigName" SG_ 998 BU_NetCfg_DCM_DR "BU_NET_CFG_DATA_INT";
BA_ "FlexKomSigStartPos" SG_ 998 BU_NetCfg_DCM_DR 7;
BA_ "FlexKomSigStartValue" SG_ 998 BU_NetCfg_DCM_DR "0300000000000000h";
BA_ "GenSigSendType" SG_ 998 BU_NetCfg_DCM_DR 1;
BA_ "GenSigSNA" SG_ 998 BU_NetCfg_DCM_DR "0h";
BA_ "FlexKomComment" SG_ 998 BU_NetCfg_DCM_PASS "Backup for network ECU config data for interior";
BA_ "FlexKomIsMotorola" SG_ 998 BU_NetCfg_DCM_PASS 1;
BA_ "FlexKomSID" SG_ 998 BU_NetCfg_DCM_PASS 871;
BA_ "FlexKomSigLaenge" SG_ 998 BU_NetCfg_DCM_PASS 64;
BA_ "FlexKomSigName" SG_ 998 BU_NetCfg_DCM_PASS "BU_NET_CFG_DATA_INT";
BA_ "FlexKomSigStartPos" SG_ 998 BU_NetCfg_DCM_PASS 7;
BA_ "FlexKomSigStartValue" SG_ 998 BU_NetCfg_DCM_PASS "0300000000000000h";
BA_ "GenSigSendType" SG_ 998 BU_NetCfg_DCM_PASS 1;
BA_ "GenSigSNA" SG_ 998 BU_NetCfg_DCM_PASS "0h";
BA_ "FlexKomComment" SG_ 998 BU_NetCfg_DCM_RL "Backup for network ECU config data for interior";
BA_ "FlexKomIsMotorola" SG_ 998 BU_NetCfg_DCM_RL 1;
BA_ "FlexKomSID" SG_ 998 BU_NetCfg_DCM_RL 871;
BA_ "FlexKomSigLaenge" SG_ 998 BU_NetCfg_DCM_RL 64;
BA_ "FlexKomSigName" SG_ 998 BU_NetCfg_DCM_RL "BU_NET_CFG_DATA_INT";
BA_ "FlexKomSigStartPos" SG_ 998 BU_NetCfg_DCM_RL 7;
BA_ "FlexKomSigStartValue" SG_ 998 BU_NetCfg_DCM_RL "0300000000000000h";
BA_ "GenSigSendType" SG_ 998 BU_NetCfg_DCM_RL 1;
BA_ "GenSigSNA" SG_ 998 BU_NetCfg_DCM_RL "0h";
BA_ "FlexKomComment" SG_ 998 BU_NetCfg_DCM_RR "Backup for network ECU config data for interior";
BA_ "FlexKomIsMotorola" SG_ 998 BU_NetCfg_DCM_RR 1;
BA_ "FlexKomSID" SG_ 998 BU_NetCfg_DCM_RR 871;
BA_ "FlexKomSigLaenge" SG_ 998 BU_NetCfg_DCM_RR 64;
BA_ "FlexKomSigName" SG_ 998 BU_NetCfg_DCM_RR "BU_NET_CFG_DATA_INT";
BA_ "FlexKomSigStartPos" SG_ 998 BU_NetCfg_DCM_RR 7;
BA_ "FlexKomSigStartValue" SG_ 998 BU_NetCfg_DCM_RR "0300000000000000h";
BA_ "GenSigSendType" SG_ 998 BU_NetCfg_DCM_RR 1;
BA_ "GenSigSNA" SG_ 998 BU_NetCfg_DCM_RR "0h";
BA_ "FlexKomComment" SG_ 998 BU_NetCfg_DCSD "Backup for network ECU config data for interior";
BA_ "FlexKomIsMotorola" SG_ 998 BU_NetCfg_DCSD 1;
BA_ "FlexKomSID" SG_ 998 BU_NetCfg_DCSD 871;
BA_ "FlexKomSigLaenge" SG_ 998 BU_NetCfg_DCSD 64;
BA_ "FlexKomSigName" SG_ 998 BU_NetCfg_DCSD "BU_NET_CFG_DATA_INT";
BA_ "FlexKomSigStartPos" SG_ 998 BU_NetCfg_DCSD 7;
BA_ "FlexKomSigStartValue" SG_ 998 BU_NetCfg_DCSD "0300000000000000h";
BA_ "GenSigSendType" SG_ 998 BU_NetCfg_DCSD 1;
BA_ "GenSigSNA" SG_ 998 BU_NetCfg_DCSD "0h";
BA_ "FlexKomComment" SG_ 998 BU_NetCfg_DTV "Backup for network ECU config data for interior";
BA_ "FlexKomIsMotorola" SG_ 998 BU_NetCfg_DTV 1;
BA_ "FlexKomSID" SG_ 998 BU_NetCfg_DTV 871;
BA_ "FlexKomSigLaenge" SG_ 998 BU_NetCfg_DTV 64;
BA_ "FlexKomSigName" SG_ 998 BU_NetCfg_DTV "BU_NET_CFG_DATA_INT";
BA_ "FlexKomSigStartPos" SG_ 998 BU_NetCfg_DTV 7;
BA_ "FlexKomSigStartValue" SG_ 998 BU_NetCfg_DTV "0300000000000000h";
BA_ "GenSigSendType" SG_ 998 BU_NetCfg_DTV 1;
BA_ "GenSigSNA" SG_ 998 BU_NetCfg_DTV "0h";
BA_ "FlexKomComment" SG_ 998 BU_NetCfg_DVD_CDM "Backup for network ECU config data for interior";
BA_ "FlexKomIsMotorola" SG_ 998 BU_NetCfg_DVD_CDM 1;
BA_ "FlexKomSID" SG_ 998 BU_NetCfg_DVD_CDM 871;
BA_ "FlexKomSigLaenge" SG_ 998 BU_NetCfg_DVD_CDM 64;
BA_ "FlexKomSigName" SG_ 998 BU_NetCfg_DVD_CDM "BU_NET_CFG_DATA_INT";
BA_ "FlexKomSigStartPos" SG_ 998 BU_NetCfg_DVD_CDM 7;
BA_ "FlexKomSigStartValue" SG_ 998 BU_NetCfg_DVD_CDM "0300000000000000h";
BA_ "GenSigSendType" SG_ 998 BU_NetCfg_DVD_CDM 1;
BA_ "GenSigSNA" SG_ 998 BU_NetCfg_DVD_CDM "0h";
BA_ "FlexKomComment" SG_ 998 BU_NetCfg_FSM "Backup for network ECU config data for interior";
BA_ "FlexKomIsMotorola" SG_ 998 BU_NetCfg_FSM 1;
BA_ "FlexKomSID" SG_ 998 BU_NetCfg_FSM 871;
BA_ "FlexKomSigLaenge" SG_ 998 BU_NetCfg_FSM 64;
BA_ "FlexKomSigName" SG_ 998 BU_NetCfg_FSM "BU_NET_CFG_DATA_INT";
BA_ "FlexKomSigStartPos" SG_ 998 BU_NetCfg_FSM 7;
BA_ "FlexKomSigStartValue" SG_ 998 BU_NetCfg_FSM "0300000000000000h";
BA_ "GenSigSendType" SG_ 998 BU_NetCfg_FSM 1;
BA_ "GenSigSNA" SG_ 998 BU_NetCfg_FSM "0h";
BA_ "FlexKomComment" SG_ 998 BU_NetCfg_HFM_CTM "Backup for network ECU config data for interior";
BA_ "FlexKomIsMotorola" SG_ 998 BU_NetCfg_HFM_CTM 1;
BA_ "FlexKomSID" SG_ 998 BU_NetCfg_HFM_CTM 871;
BA_ "FlexKomSigLaenge" SG_ 998 BU_NetCfg_HFM_CTM 64;
BA_ "FlexKomSigName" SG_ 998 BU_NetCfg_HFM_CTM "BU_NET_CFG_DATA_INT";
BA_ "FlexKomSigStartPos" SG_ 998 BU_NetCfg_HFM_CTM 7;
BA_ "FlexKomSigStartValue" SG_ 998 BU_NetCfg_HFM_CTM "0300000000000000h";
BA_ "GenSigSendType" SG_ 998 BU_NetCfg_HFM_CTM 1;
BA_ "GenSigSNA" SG_ 998 BU_NetCfg_HFM_CTM "0h";
BA_ "FlexKomComment" SG_ 998 BU_NetCfg_HVAC "Backup for network ECU config data for interior";
BA_ "FlexKomIsMotorola" SG_ 998 BU_NetCfg_HVAC 1;
BA_ "FlexKomSID" SG_ 998 BU_NetCfg_HVAC 871;
BA_ "FlexKomSigLaenge" SG_ 998 BU_NetCfg_HVAC 64;
BA_ "FlexKomSigName" SG_ 998 BU_NetCfg_HVAC "BU_NET_CFG_DATA_INT";
BA_ "FlexKomSigStartPos" SG_ 998 BU_NetCfg_HVAC 7;
BA_ "FlexKomSigStartValue" SG_ 998 BU_NetCfg_HVAC "0300000000000000h";
BA_ "GenSigSendType" SG_ 998 BU_NetCfg_HVAC 1;
BA_ "GenSigSNA" SG_ 998 BU_NetCfg_HVAC "0h";
BA_ "FlexKomComment" SG_ 998 BU_NetCfg_HVAC_R "Backup for network ECU config data for interior";
BA_ "FlexKomIsMotorola" SG_ 998 BU_NetCfg_HVAC_R 1;
BA_ "FlexKomSID" SG_ 998 BU_NetCfg_HVAC_R 871;
BA_ "FlexKomSigLaenge" SG_ 998 BU_NetCfg_HVAC_R 64;
BA_ "FlexKomSigName" SG_ 998 BU_NetCfg_HVAC_R "BU_NET_CFG_DATA_INT";
BA_ "FlexKomSigStartPos" SG_ 998 BU_NetCfg_HVAC_R 7;
BA_ "FlexKomSigStartValue" SG_ 998 BU_NetCfg_HVAC_R "0300000000000000h";
BA_ "GenSigSendType" SG_ 998 BU_NetCfg_HVAC_R 1;
BA_ "GenSigSNA" SG_ 998 BU_NetCfg_HVAC_R "0h";
BA_ "FlexKomComment" SG_ 998 BU_NetCfg_ICS_I "Backup for network ECU config data for interior";
BA_ "FlexKomIsMotorola" SG_ 998 BU_NetCfg_ICS_I 1;
BA_ "FlexKomSID" SG_ 998 BU_NetCfg_ICS_I 871;
BA_ "FlexKomSigLaenge" SG_ 998 BU_NetCfg_ICS_I 64;
BA_ "FlexKomSigName" SG_ 998 BU_NetCfg_ICS_I "BU_NET_CFG_DATA_INT";
BA_ "FlexKomSigStartPos" SG_ 998 BU_NetCfg_ICS_I 7;
BA_ "FlexKomSigStartValue" SG_ 998 BU_NetCfg_ICS_I "0300000000000000h";
BA_ "GenSigSendType" SG_ 998 BU_NetCfg_ICS_I 1;
BA_ "GenSigSNA" SG_ 998 BU_NetCfg_ICS_I "0h";
BA_ "FlexKomComment" SG_ 998 BU_NetCfg_ICS_R "Backup for network ECU config data for interior";
BA_ "FlexKomIsMotorola" SG_ 998 BU_NetCfg_ICS_R 1;
BA_ "FlexKomSID" SG_ 998 BU_NetCfg_ICS_R 871;
BA_ "FlexKomSigLaenge" SG_ 998 BU_NetCfg_ICS_R 64;
BA_ "FlexKomSigName" SG_ 998 BU_NetCfg_ICS_R "BU_NET_CFG_DATA_INT";
BA_ "FlexKomSigStartPos" SG_ 998 BU_NetCfg_ICS_R 7;
BA_ "FlexKomSigStartValue" SG_ 998 BU_NetCfg_ICS_R "0300000000000000h";
BA_ "GenSigSendType" SG_ 998 BU_NetCfg_ICS_R 1;
BA_ "GenSigSNA" SG_ 998 BU_NetCfg_ICS_R "0h";
BA_ "FlexKomComment" SG_ 998 BU_NetCfg_ITM "Backup for network ECU config data for interior";
BA_ "FlexKomIsMotorola" SG_ 998 BU_NetCfg_ITM 1;
BA_ "FlexKomSID" SG_ 998 BU_NetCfg_ITM 871;
BA_ "FlexKomSigLaenge" SG_ 998 BU_NetCfg_ITM 64;
BA_ "FlexKomSigName" SG_ 998 BU_NetCfg_ITM "BU_NET_CFG_DATA_INT";
BA_ "FlexKomSigStartPos" SG_ 998 BU_NetCfg_ITM 7;
BA_ "FlexKomSigStartValue" SG_ 998 BU_NetCfg_ITM "0300000000000000h";
BA_ "GenSigSendType" SG_ 998 BU_NetCfg_ITM 1;
BA_ "GenSigSNA" SG_ 998 BU_NetCfg_ITM "0h";
BA_ "FlexKomComment" SG_ 998 BU_NetCfg_MSM "Backup for network ECU config data for interior";
BA_ "FlexKomIsMotorola" SG_ 998 BU_NetCfg_MSM 1;
BA_ "FlexKomSID" SG_ 998 BU_NetCfg_MSM 871;
BA_ "FlexKomSigLaenge" SG_ 998 BU_NetCfg_MSM 64;
BA_ "FlexKomSigName" SG_ 998 BU_NetCfg_MSM "BU_NET_CFG_DATA_INT";
BA_ "FlexKomSigStartPos" SG_ 998 BU_NetCfg_MSM 7;
BA_ "FlexKomSigStartValue" SG_ 998 BU_NetCfg_MSM "0300000000000000h";
BA_ "GenSigSendType" SG_ 998 BU_NetCfg_MSM 1;
BA_ "GenSigSNA" SG_ 998 BU_NetCfg_MSM "0h";
BA_ "FlexKomComment" SG_ 998 BU_NetCfg_MSM_PASS "Backup for network ECU config data for interior";
BA_ "FlexKomIsMotorola" SG_ 998 BU_NetCfg_MSM_PASS 1;
BA_ "FlexKomSID" SG_ 998 BU_NetCfg_MSM_PASS 871;
BA_ "FlexKomSigLaenge" SG_ 998 BU_NetCfg_MSM_PASS 64;
BA_ "FlexKomSigName" SG_ 998 BU_NetCfg_MSM_PASS "BU_NET_CFG_DATA_INT";
BA_ "FlexKomSigStartPos" SG_ 998 BU_NetCfg_MSM_PASS 7;
BA_ "FlexKomSigStartValue" SG_ 998 BU_NetCfg_MSM_PASS "0300000000000000h";
BA_ "GenSigSendType" SG_ 998 BU_NetCfg_MSM_PASS 1;
BA_ "GenSigSNA" SG_ 998 BU_NetCfg_MSM_PASS "0h";
BA_ "FlexKomComment" SG_ 998 BU_NetCfg_PLG "Backup for network ECU config data for interior";
BA_ "FlexKomIsMotorola" SG_ 998 BU_NetCfg_PLG 1;
BA_ "FlexKomSID" SG_ 998 BU_NetCfg_PLG 871;
BA_ "FlexKomSigLaenge" SG_ 998 BU_NetCfg_PLG 64;
BA_ "FlexKomSigName" SG_ 998 BU_NetCfg_PLG "BU_NET_CFG_DATA_INT";
BA_ "FlexKomSigStartPos" SG_ 998 BU_NetCfg_PLG 7;
BA_ "FlexKomSigStartValue" SG_ 998 BU_NetCfg_PLG "0300000000000000h";
BA_ "GenSigSendType" SG_ 998 BU_NetCfg_PLG 1;
BA_ "GenSigSNA" SG_ 998 BU_NetCfg_PLG "0h";
BA_ "FlexKomComment" SG_ 998 BU_NetCfg_PSD_LT "Backup for network ECU config data for interior";
BA_ "FlexKomIsMotorola" SG_ 998 BU_NetCfg_PSD_LT 1;
BA_ "FlexKomSID" SG_ 998 BU_NetCfg_PSD_LT 871;
BA_ "FlexKomSigLaenge" SG_ 998 BU_NetCfg_PSD_LT 64;
BA_ "FlexKomSigName" SG_ 998 BU_NetCfg_PSD_LT "BU_NET_CFG_DATA_INT";
BA_ "FlexKomSigStartPos" SG_ 998 BU_NetCfg_PSD_LT 7;
BA_ "FlexKomSigStartValue" SG_ 998 BU_NetCfg_PSD_LT "0300000000000000h";
BA_ "GenSigSendType" SG_ 998 BU_NetCfg_PSD_LT 1;
BA_ "GenSigSNA" SG_ 998 BU_NetCfg_PSD_LT "0h";
BA_ "FlexKomComment" SG_ 998 BU_NetCfg_PSD_RT "Backup for network ECU config data for interior";
BA_ "FlexKomIsMotorola" SG_ 998 BU_NetCfg_PSD_RT 1;
BA_ "FlexKomSID" SG_ 998 BU_NetCfg_PSD_RT 871;
BA_ "FlexKomSigLaenge" SG_ 998 BU_NetCfg_PSD_RT 64;
BA_ "FlexKomSigName" SG_ 998 BU_NetCfg_PSD_RT "BU_NET_CFG_DATA_INT";
BA_ "FlexKomSigStartPos" SG_ 998 BU_NetCfg_PSD_RT 7;
BA_ "FlexKomSigStartValue" SG_ 998 BU_NetCfg_PSD_RT "0300000000000000h";
BA_ "GenSigSendType" SG_ 998 BU_NetCfg_PSD_RT 1;
BA_ "GenSigSNA" SG_ 998 BU_NetCfg_PSD_RT "0h";
BA_ "FlexKomComment" SG_ 998 BU_NetCfg_PTCM "Backup for network ECU config data for interior";
BA_ "FlexKomIsMotorola" SG_ 998 BU_NetCfg_PTCM 1;
BA_ "FlexKomSID" SG_ 998 BU_NetCfg_PTCM 871;
BA_ "FlexKomSigLaenge" SG_ 998 BU_NetCfg_PTCM 64;
BA_ "FlexKomSigName" SG_ 998 BU_NetCfg_PTCM "BU_NET_CFG_DATA_INT";
BA_ "FlexKomSigStartPos" SG_ 998 BU_NetCfg_PTCM 7;
BA_ "FlexKomSigStartValue" SG_ 998 BU_NetCfg_PTCM "0300000000000000h";
BA_ "GenSigSendType" SG_ 998 BU_NetCfg_PTCM 1;
BA_ "GenSigSNA" SG_ 998 BU_NetCfg_PTCM "0h";
BA_ "FlexKomComment" SG_ 998 BU_NetCfg_RBC "Backup for network ECU config data for interior";
BA_ "FlexKomIsMotorola" SG_ 998 BU_NetCfg_RBC 1;
BA_ "FlexKomSID" SG_ 998 BU_NetCfg_RBC 871;
BA_ "FlexKomSigLaenge" SG_ 998 BU_NetCfg_RBC 64;
BA_ "FlexKomSigName" SG_ 998 BU_NetCfg_RBC "BU_NET_CFG_DATA_INT";
BA_ "FlexKomSigStartPos" SG_ 998 BU_NetCfg_RBC 7;
BA_ "FlexKomSigStartValue" SG_ 998 BU_NetCfg_RBC "0300000000000000h";
BA_ "GenSigSendType" SG_ 998 BU_NetCfg_RBC 1;
BA_ "GenSigSNA" SG_ 998 BU_NetCfg_RBC "0h";
BA_ "FlexKomComment" SG_ 998 BU_NetCfg_RBSS "Backup for network ECU config data for interior";
BA_ "FlexKomIsMotorola" SG_ 998 BU_NetCfg_RBSS 1;
BA_ "FlexKomSID" SG_ 998 BU_NetCfg_RBSS 871;
BA_ "FlexKomSigLaenge" SG_ 998 BU_NetCfg_RBSS 64;
BA_ "FlexKomSigName" SG_ 998 BU_NetCfg_RBSS "BU_NET_CFG_DATA_INT";
BA_ "FlexKomSigStartPos" SG_ 998 BU_NetCfg_RBSS 7;
BA_ "FlexKomSigStartValue" SG_ 998 BU_NetCfg_RBSS "0300000000000000h";
BA_ "GenSigSendType" SG_ 998 BU_NetCfg_RBSS 1;
BA_ "GenSigSNA" SG_ 998 BU_NetCfg_RBSS "0h";
BA_ "FlexKomComment" SG_ 998 BU_NetCfg_TBM "Backup for network ECU config data for interior";
BA_ "FlexKomIsMotorola" SG_ 998 BU_NetCfg_TBM 1;
BA_ "FlexKomSID" SG_ 998 BU_NetCfg_TBM 871;
BA_ "FlexKomSigLaenge" SG_ 998 BU_NetCfg_TBM 64;
BA_ "FlexKomSigName" SG_ 998 BU_NetCfg_TBM "BU_NET_CFG_DATA_INT";
BA_ "FlexKomSigStartPos" SG_ 998 BU_NetCfg_TBM 7;
BA_ "FlexKomSigStartValue" SG_ 998 BU_NetCfg_TBM "0300000000000000h";
BA_ "GenSigSendType" SG_ 998 BU_NetCfg_TBM 1;
BA_ "GenSigSNA" SG_ 998 BU_NetCfg_TBM "0h";
BA_ "FlexKomComment" SG_ 998 BU_NetCfg_TGW "Backup for network ECU config data for interior";
BA_ "FlexKomIsMotorola" SG_ 998 BU_NetCfg_TGW 1;
BA_ "FlexKomSID" SG_ 998 BU_NetCfg_TGW 871;
BA_ "FlexKomSigLaenge" SG_ 998 BU_NetCfg_TGW 64;
BA_ "FlexKomSigName" SG_ 998 BU_NetCfg_TGW "BU_NET_CFG_DATA_INT";
BA_ "FlexKomSigStartPos" SG_ 998 BU_NetCfg_TGW 7;
BA_ "FlexKomSigStartValue" SG_ 998 BU_NetCfg_TGW "0300000000000000h";
BA_ "GenSigSendType" SG_ 998 BU_NetCfg_TGW 1;
BA_ "GenSigSNA" SG_ 998 BU_NetCfg_TGW "0h";
BA_ "FlexKomComment" SG_ 998 BU_NetCfg_TMM "Backup for network ECU config data for interior";
BA_ "FlexKomIsMotorola" SG_ 998 BU_NetCfg_TMM 1;
BA_ "FlexKomSID" SG_ 998 BU_NetCfg_TMM 871;
BA_ "FlexKomSigLaenge" SG_ 998 BU_NetCfg_TMM 64;
BA_ "FlexKomSigName" SG_ 998 BU_NetCfg_TMM "BU_NET_CFG_DATA_INT";
BA_ "FlexKomSigStartPos" SG_ 998 BU_NetCfg_TMM 7;
BA_ "FlexKomSigStartValue" SG_ 998 BU_NetCfg_TMM "0300000000000000h";
BA_ "GenSigSendType" SG_ 998 BU_NetCfg_TMM 1;
BA_ "GenSigSNA" SG_ 998 BU_NetCfg_TMM "0h";
BA_ "FlexKomComment" SG_ 998 BU_NetCfg_VES2_I "Backup for network ECU config data for interior";
BA_ "FlexKomIsMotorola" SG_ 998 BU_NetCfg_VES2_I 1;
BA_ "FlexKomSID" SG_ 998 BU_NetCfg_VES2_I 871;
BA_ "FlexKomSigLaenge" SG_ 998 BU_NetCfg_VES2_I 64;
BA_ "FlexKomSigName" SG_ 998 BU_NetCfg_VES2_I "BU_NET_CFG_DATA_INT";
BA_ "FlexKomSigStartPos" SG_ 998 BU_NetCfg_VES2_I 7;
BA_ "FlexKomSigStartValue" SG_ 998 BU_NetCfg_VES2_I "0300000000000000h";
BA_ "GenSigSendType" SG_ 998 BU_NetCfg_VES2_I 1;
BA_ "GenSigSNA" SG_ 998 BU_NetCfg_VES2_I "0h";
BA_ "FlexKomComment" SG_ 998 BU_NetCfg_VES3_I "Backup for network ECU config data for interior";
BA_ "FlexKomIsMotorola" SG_ 998 BU_NetCfg_VES3_I 1;
BA_ "FlexKomSID" SG_ 998 BU_NetCfg_VES3_I 871;
BA_ "FlexKomSigLaenge" SG_ 998 BU_NetCfg_VES3_I 64;
BA_ "FlexKomSigName" SG_ 998 BU_NetCfg_VES3_I "BU_NET_CFG_DATA_INT";
BA_ "FlexKomSigStartPos" SG_ 998 BU_NetCfg_VES3_I 7;
BA_ "FlexKomSigStartValue" SG_ 998 BU_NetCfg_VES3_I "0300000000000000h";
BA_ "GenSigSendType" SG_ 998 BU_NetCfg_VES3_I 1;
BA_ "GenSigSNA" SG_ 998 BU_NetCfg_VES3_I "0h";
BA_ "FlexKomComment" SG_ 998 BU_NetCfg_VRM "Backup for network ECU config data for interior";
BA_ "FlexKomIsMotorola" SG_ 998 BU_NetCfg_VRM 1;
BA_ "FlexKomSID" SG_ 998 BU_NetCfg_VRM 871;
BA_ "FlexKomSigLaenge" SG_ 998 BU_NetCfg_VRM 64;
BA_ "FlexKomSigName" SG_ 998 BU_NetCfg_VRM "BU_NET_CFG_DATA_INT";
BA_ "FlexKomSigStartPos" SG_ 998 BU_NetCfg_VRM 7;
BA_ "FlexKomSigStartValue" SG_ 998 BU_NetCfg_VRM "0300000000000000h";
BA_ "GenSigSendType" SG_ 998 BU_NetCfg_VRM 1;
BA_ "GenSigSNA" SG_ 998 BU_NetCfg_VRM "0h";
BA_ "FlexKomComment" SG_ 998 BU_NetCfg_VSIM "Backup for network ECU config data for interior";
BA_ "FlexKomIsMotorola" SG_ 998 BU_NetCfg_VSIM 1;
BA_ "FlexKomSID" SG_ 998 BU_NetCfg_VSIM 871;
BA_ "FlexKomSigLaenge" SG_ 998 BU_NetCfg_VSIM 64;
BA_ "FlexKomSigName" SG_ 998 BU_NetCfg_VSIM "BU_NET_CFG_DATA_INT";
BA_ "FlexKomSigStartPos" SG_ 998 BU_NetCfg_VSIM 7;
BA_ "FlexKomSigStartValue" SG_ 998 BU_NetCfg_VSIM "0300000000000000h";
BA_ "GenSigSendType" SG_ 998 BU_NetCfg_VSIM 1;
BA_ "GenSigSNA" SG_ 998 BU_NetCfg_VSIM "0h";
BA_ "FlexKomComment" SG_ 998 BU_NetCfg_VTM "Backup for network ECU config data for interior";
BA_ "FlexKomIsMotorola" SG_ 998 BU_NetCfg_VTM 1;
BA_ "FlexKomSID" SG_ 998 BU_NetCfg_VTM 871;
BA_ "FlexKomSigLaenge" SG_ 998 BU_NetCfg_VTM 64;
BA_ "FlexKomSigName" SG_ 998 BU_NetCfg_VTM "BU_NET_CFG_DATA_INT";
BA_ "FlexKomSigStartPos" SG_ 998 BU_NetCfg_VTM 7;
BA_ "FlexKomSigStartValue" SG_ 998 BU_NetCfg_VTM "0300000000000000h";
BA_ "GenSigSendType" SG_ 998 BU_NetCfg_VTM 1;
BA_ "GenSigSNA" SG_ 998 BU_NetCfg_VTM "0h";
BA_ "FlexKomComment" SG_ 999 BU_NET_CFG_STAT_PT "Backup for network ECU config data for Powertrain";
BA_ "FlexKomIsMotorola" SG_ 999 BU_NET_CFG_STAT_PT 1;
BA_ "FlexKomSID" SG_ 999 BU_NET_CFG_STAT_PT 872;
BA_ "FlexKomSigLaenge" SG_ 999 BU_NET_CFG_STAT_PT 64;
BA_ "FlexKomSigName" SG_ 999 BU_NET_CFG_STAT_PT "BU_NET_CFG_DATA_PT";
BA_ "FlexKomSigStartPos" SG_ 999 BU_NET_CFG_STAT_PT 7;
BA_ "FlexKomSigStartValue" SG_ 999 BU_NET_CFG_STAT_PT "0300000000000000h";
BA_ "GenSigSendType" SG_ 999 BU_NET_CFG_STAT_PT 1;
BA_ "GenSigSNA" SG_ 999 BU_NET_CFG_STAT_PT "3h";
BA_ "GenSigStartValue" SG_ 999 BU_NET_CFG_STAT_PT 3;
BA_ "FlexKomComment" SG_ 999 BU_NetCfg_ACC "Backup for network ECU config data for Powertrain";
BA_ "FlexKomIsMotorola" SG_ 999 BU_NetCfg_ACC 1;
BA_ "FlexKomSID" SG_ 999 BU_NetCfg_ACC 872;
BA_ "FlexKomSigLaenge" SG_ 999 BU_NetCfg_ACC 64;
BA_ "FlexKomSigName" SG_ 999 BU_NetCfg_ACC "BU_NET_CFG_DATA_PT";
BA_ "FlexKomSigStartPos" SG_ 999 BU_NetCfg_ACC 7;
BA_ "FlexKomSigStartValue" SG_ 999 BU_NetCfg_ACC "0300000000000000h";
BA_ "GenSigSendType" SG_ 999 BU_NetCfg_ACC 1;
BA_ "GenSigSNA" SG_ 999 BU_NetCfg_ACC "0h";
BA_ "FlexKomComment" SG_ 999 BU_NetCfg_ADCM "Backup for network ECU config data for Powertrain";
BA_ "FlexKomIsMotorola" SG_ 999 BU_NetCfg_ADCM 1;
BA_ "FlexKomSID" SG_ 999 BU_NetCfg_ADCM 872;
BA_ "FlexKomSigLaenge" SG_ 999 BU_NetCfg_ADCM 64;
BA_ "FlexKomSigName" SG_ 999 BU_NetCfg_ADCM "BU_NET_CFG_DATA_PT";
BA_ "FlexKomSigStartPos" SG_ 999 BU_NetCfg_ADCM 7;
BA_ "FlexKomSigStartValue" SG_ 999 BU_NetCfg_ADCM "0300000000000000h";
BA_ "GenSigSendType" SG_ 999 BU_NetCfg_ADCM 1;
BA_ "GenSigSNA" SG_ 999 BU_NetCfg_ADCM "0h";
BA_ "FlexKomComment" SG_ 999 BU_NetCfg_AFLS "Backup for network ECU config data for Powertrain";
BA_ "FlexKomIsMotorola" SG_ 999 BU_NetCfg_AFLS 1;
BA_ "FlexKomSID" SG_ 999 BU_NetCfg_AFLS 872;
BA_ "FlexKomSigLaenge" SG_ 999 BU_NetCfg_AFLS 64;
BA_ "FlexKomSigName" SG_ 999 BU_NetCfg_AFLS "BU_NET_CFG_DATA_PT";
BA_ "FlexKomSigStartPos" SG_ 999 BU_NetCfg_AFLS 7;
BA_ "FlexKomSigStartValue" SG_ 999 BU_NetCfg_AFLS "0300000000000000h";
BA_ "GenSigSendType" SG_ 999 BU_NetCfg_AFLS 1;
BA_ "GenSigSNA" SG_ 999 BU_NetCfg_AFLS "0h";
BA_ "FlexKomComment" SG_ 999 BU_NetCfg_AHLM "Backup for network ECU config data for Powertrain";
BA_ "FlexKomIsMotorola" SG_ 999 BU_NetCfg_AHLM 1;
BA_ "FlexKomSID" SG_ 999 BU_NetCfg_AHLM 872;
BA_ "FlexKomSigLaenge" SG_ 999 BU_NetCfg_AHLM 64;
BA_ "FlexKomSigName" SG_ 999 BU_NetCfg_AHLM "BU_NET_CFG_DATA_PT";
BA_ "FlexKomSigStartPos" SG_ 999 BU_NetCfg_AHLM 7;
BA_ "FlexKomSigStartValue" SG_ 999 BU_NetCfg_AHLM "0300000000000000h";
BA_ "GenSigSendType" SG_ 999 BU_NetCfg_AHLM 1;
BA_ "GenSigSNA" SG_ 999 BU_NetCfg_AHLM "0h";
BA_ "FlexKomComment" SG_ 999 BU_NetCfg_ANC "Backup for network ECU config data for Powertrain";
BA_ "FlexKomIsMotorola" SG_ 999 BU_NetCfg_ANC 1;
BA_ "FlexKomSID" SG_ 999 BU_NetCfg_ANC 872;
BA_ "FlexKomSigLaenge" SG_ 999 BU_NetCfg_ANC 64;
BA_ "FlexKomSigName" SG_ 999 BU_NetCfg_ANC "BU_NET_CFG_DATA_PT";
BA_ "FlexKomSigStartPos" SG_ 999 BU_NetCfg_ANC 7;
BA_ "FlexKomSigStartValue" SG_ 999 BU_NetCfg_ANC "0300000000000000h";
BA_ "GenSigSendType" SG_ 999 BU_NetCfg_ANC 1;
BA_ "GenSigSNA" SG_ 999 BU_NetCfg_ANC "0h";
BA_ "FlexKomComment" SG_ 999 BU_NetCfg_ASCM "Backup for network ECU config data for Powertrain";
BA_ "FlexKomIsMotorola" SG_ 999 BU_NetCfg_ASCM 1;
BA_ "FlexKomSID" SG_ 999 BU_NetCfg_ASCM 872;
BA_ "FlexKomSigLaenge" SG_ 999 BU_NetCfg_ASCM 64;
BA_ "FlexKomSigName" SG_ 999 BU_NetCfg_ASCM "BU_NET_CFG_DATA_PT";
BA_ "FlexKomSigStartPos" SG_ 999 BU_NetCfg_ASCM 7;
BA_ "FlexKomSigStartValue" SG_ 999 BU_NetCfg_ASCM "0300000000000000h";
BA_ "GenSigSendType" SG_ 999 BU_NetCfg_ASCM 1;
BA_ "GenSigSNA" SG_ 999 BU_NetCfg_ASCM "0h";
BA_ "FlexKomComment" SG_ 999 BU_NetCfg_BSMO "Backup for network ECU config data for Powertrain";
BA_ "FlexKomIsMotorola" SG_ 999 BU_NetCfg_BSMO 1;
BA_ "FlexKomSID" SG_ 999 BU_NetCfg_BSMO 872;
BA_ "FlexKomSigLaenge" SG_ 999 BU_NetCfg_BSMO 64;
BA_ "FlexKomSigName" SG_ 999 BU_NetCfg_BSMO "BU_NET_CFG_DATA_PT";
BA_ "FlexKomSigStartPos" SG_ 999 BU_NetCfg_BSMO 7;
BA_ "FlexKomSigStartValue" SG_ 999 BU_NetCfg_BSMO "0300000000000000h";
BA_ "GenSigSendType" SG_ 999 BU_NetCfg_BSMO 1;
BA_ "GenSigSNA" SG_ 999 BU_NetCfg_BSMO "0h";
BA_ "FlexKomComment" SG_ 999 BU_NetCfg_CBC_PT "Backup for network ECU config data for Powertrain";
BA_ "FlexKomIsMotorola" SG_ 999 BU_NetCfg_CBC_PT 1;
BA_ "FlexKomSID" SG_ 999 BU_NetCfg_CBC_PT 872;
BA_ "FlexKomSigLaenge" SG_ 999 BU_NetCfg_CBC_PT 64;
BA_ "FlexKomSigName" SG_ 999 BU_NetCfg_CBC_PT "BU_NET_CFG_DATA_PT";
BA_ "FlexKomSigStartPos" SG_ 999 BU_NetCfg_CBC_PT 7;
BA_ "FlexKomSigStartValue" SG_ 999 BU_NetCfg_CBC_PT "0300000000000000h";
BA_ "GenSigSendType" SG_ 999 BU_NetCfg_CBC_PT 1;
BA_ "GenSigSNA" SG_ 999 BU_NetCfg_CBC_PT "0h";
BA_ "FlexKomComment" SG_ 999 BU_NetCfg_DASM "Backup for network ECU config data for Powertrain";
BA_ "FlexKomIsMotorola" SG_ 999 BU_NetCfg_DASM 1;
BA_ "FlexKomSID" SG_ 999 BU_NetCfg_DASM 872;
BA_ "FlexKomSigLaenge" SG_ 999 BU_NetCfg_DASM 64;
BA_ "FlexKomSigName" SG_ 999 BU_NetCfg_DASM "BU_NET_CFG_DATA_PT";
BA_ "FlexKomSigStartPos" SG_ 999 BU_NetCfg_DASM 7;
BA_ "FlexKomSigStartValue" SG_ 999 BU_NetCfg_DASM "0300000000000000h";
BA_ "GenSigSendType" SG_ 999 BU_NetCfg_DASM 1;
BA_ "GenSigSNA" SG_ 999 BU_NetCfg_DASM "0h";
BA_ "FlexKomComment" SG_ 999 BU_NetCfg_DTCM "Backup for network ECU config data for Powertrain";
BA_ "FlexKomIsMotorola" SG_ 999 BU_NetCfg_DTCM 1;
BA_ "FlexKomSID" SG_ 999 BU_NetCfg_DTCM 872;
BA_ "FlexKomSigLaenge" SG_ 999 BU_NetCfg_DTCM 64;
BA_ "FlexKomSigName" SG_ 999 BU_NetCfg_DTCM "BU_NET_CFG_DATA_PT";
BA_ "FlexKomSigStartPos" SG_ 999 BU_NetCfg_DTCM 7;
BA_ "FlexKomSigStartValue" SG_ 999 BU_NetCfg_DTCM "0300000000000000h";
BA_ "GenSigSendType" SG_ 999 BU_NetCfg_DTCM 1;
BA_ "GenSigSNA" SG_ 999 BU_NetCfg_DTCM "0h";
BA_ "FlexKomComment" SG_ 999 BU_NetCfg_ECM "Backup for network ECU config data for Powertrain";
BA_ "FlexKomIsMotorola" SG_ 999 BU_NetCfg_ECM 1;
BA_ "FlexKomSID" SG_ 999 BU_NetCfg_ECM 872;
BA_ "FlexKomSigLaenge" SG_ 999 BU_NetCfg_ECM 64;
BA_ "FlexKomSigName" SG_ 999 BU_NetCfg_ECM "BU_NET_CFG_DATA_PT";
BA_ "FlexKomSigStartPos" SG_ 999 BU_NetCfg_ECM 7;
BA_ "FlexKomSigStartValue" SG_ 999 BU_NetCfg_ECM "0300000000000000h";
BA_ "GenSigSendType" SG_ 999 BU_NetCfg_ECM 1;
BA_ "GenSigSNA" SG_ 999 BU_NetCfg_ECM "0h";
BA_ "FlexKomComment" SG_ 999 BU_NetCfg_ELSD "Backup for network ECU config data for Powertrain";
BA_ "FlexKomIsMotorola" SG_ 999 BU_NetCfg_ELSD 1;
BA_ "FlexKomSID" SG_ 999 BU_NetCfg_ELSD 872;
BA_ "FlexKomSigLaenge" SG_ 999 BU_NetCfg_ELSD 64;
BA_ "FlexKomSigName" SG_ 999 BU_NetCfg_ELSD "BU_NET_CFG_DATA_PT";
BA_ "FlexKomSigStartPos" SG_ 999 BU_NetCfg_ELSD 7;
BA_ "FlexKomSigStartValue" SG_ 999 BU_NetCfg_ELSD "0300000000000000h";
BA_ "GenSigSendType" SG_ 999 BU_NetCfg_ELSD 1;
BA_ "GenSigSNA" SG_ 999 BU_NetCfg_ELSD "0h";
BA_ "FlexKomComment" SG_ 999 BU_NetCfg_EPB "Backup for network ECU config data for Powertrain";
BA_ "FlexKomIsMotorola" SG_ 999 BU_NetCfg_EPB 1;
BA_ "FlexKomSID" SG_ 999 BU_NetCfg_EPB 872;
BA_ "FlexKomSigLaenge" SG_ 999 BU_NetCfg_EPB 64;
BA_ "FlexKomSigName" SG_ 999 BU_NetCfg_EPB "BU_NET_CFG_DATA_PT";
BA_ "FlexKomSigStartPos" SG_ 999 BU_NetCfg_EPB 7;
BA_ "FlexKomSigStartValue" SG_ 999 BU_NetCfg_EPB "0300000000000000h";
BA_ "GenSigSendType" SG_ 999 BU_NetCfg_EPB 1;
BA_ "GenSigSNA" SG_ 999 BU_NetCfg_EPB "0h";
BA_ "FlexKomComment" SG_ 999 BU_NetCfg_EPPM "Backup for network ECU config data for Powertrain";
BA_ "FlexKomIsMotorola" SG_ 999 BU_NetCfg_EPPM 1;
BA_ "FlexKomSID" SG_ 999 BU_NetCfg_EPPM 872;
BA_ "FlexKomSigLaenge" SG_ 999 BU_NetCfg_EPPM 64;
BA_ "FlexKomSigName" SG_ 999 BU_NetCfg_EPPM "BU_NET_CFG_DATA_PT";
BA_ "FlexKomSigStartPos" SG_ 999 BU_NetCfg_EPPM 7;
BA_ "FlexKomSigStartValue" SG_ 999 BU_NetCfg_EPPM "0300000000000000h";
BA_ "GenSigSendType" SG_ 999 BU_NetCfg_EPPM 1;
BA_ "GenSigSNA" SG_ 999 BU_NetCfg_EPPM "0h";
BA_ "FlexKomComment" SG_ 999 BU_NetCfg_EPS "Backup for network ECU config data for Powertrain";
BA_ "FlexKomIsMotorola" SG_ 999 BU_NetCfg_EPS 1;
BA_ "FlexKomSID" SG_ 999 BU_NetCfg_EPS 872;
BA_ "FlexKomSigLaenge" SG_ 999 BU_NetCfg_EPS 64;
BA_ "FlexKomSigName" SG_ 999 BU_NetCfg_EPS "BU_NET_CFG_DATA_PT";
BA_ "FlexKomSigStartPos" SG_ 999 BU_NetCfg_EPS 7;
BA_ "FlexKomSigStartValue" SG_ 999 BU_NetCfg_EPS "0300000000000000h";
BA_ "GenSigSendType" SG_ 999 BU_NetCfg_EPS 1;
BA_ "GenSigSNA" SG_ 999 BU_NetCfg_EPS "0h";
BA_ "FlexKomComment" SG_ 999 BU_NetCfg_ESC "Backup for network ECU config data for Powertrain";
BA_ "FlexKomIsMotorola" SG_ 999 BU_NetCfg_ESC 1;
BA_ "FlexKomSID" SG_ 999 BU_NetCfg_ESC 872;
BA_ "FlexKomSigLaenge" SG_ 999 BU_NetCfg_ESC 64;
BA_ "FlexKomSigName" SG_ 999 BU_NetCfg_ESC "BU_NET_CFG_DATA_PT";
BA_ "FlexKomSigStartPos" SG_ 999 BU_NetCfg_ESC 7;
BA_ "FlexKomSigStartValue" SG_ 999 BU_NetCfg_ESC "0300000000000000h";
BA_ "GenSigSendType" SG_ 999 BU_NetCfg_ESC 1;
BA_ "GenSigSNA" SG_ 999 BU_NetCfg_ESC "0h";
BA_ "FlexKomComment" SG_ 999 BU_NetCfg_ESL "Backup for network ECU config data for Powertrain";
BA_ "FlexKomIsMotorola" SG_ 999 BU_NetCfg_ESL 1;
BA_ "FlexKomSID" SG_ 999 BU_NetCfg_ESL 872;
BA_ "FlexKomSigLaenge" SG_ 999 BU_NetCfg_ESL 64;
BA_ "FlexKomSigName" SG_ 999 BU_NetCfg_ESL "BU_NET_CFG_DATA_PT";
BA_ "FlexKomSigStartPos" SG_ 999 BU_NetCfg_ESL 7;
BA_ "FlexKomSigStartValue" SG_ 999 BU_NetCfg_ESL "0300000000000000h";
BA_ "GenSigSendType" SG_ 999 BU_NetCfg_ESL 1;
BA_ "GenSigSNA" SG_ 999 BU_NetCfg_ESL "0h";
BA_ "FlexKomComment" SG_ 999 BU_NetCfg_ESM "Backup for network ECU config data for Powertrain";
BA_ "FlexKomIsMotorola" SG_ 999 BU_NetCfg_ESM 1;
BA_ "FlexKomSID" SG_ 999 BU_NetCfg_ESM 872;
BA_ "FlexKomSigLaenge" SG_ 999 BU_NetCfg_ESM 64;
BA_ "FlexKomSigName" SG_ 999 BU_NetCfg_ESM "BU_NET_CFG_DATA_PT";
BA_ "FlexKomSigStartPos" SG_ 999 BU_NetCfg_ESM 7;
BA_ "FlexKomSigStartValue" SG_ 999 BU_NetCfg_ESM "0300000000000000h";
BA_ "GenSigSendType" SG_ 999 BU_NetCfg_ESM 1;
BA_ "GenSigSNA" SG_ 999 BU_NetCfg_ESM "0h";
BA_ "FlexKomComment" SG_ 999 BU_NetCfg_FDCM "Backup for network ECU config data for Powertrain";
BA_ "FlexKomIsMotorola" SG_ 999 BU_NetCfg_FDCM 1;
BA_ "FlexKomSID" SG_ 999 BU_NetCfg_FDCM 872;
BA_ "FlexKomSigLaenge" SG_ 999 BU_NetCfg_FDCM 64;
BA_ "FlexKomSigName" SG_ 999 BU_NetCfg_FDCM "BU_NET_CFG_DATA_PT";
BA_ "FlexKomSigStartPos" SG_ 999 BU_NetCfg_FDCM 7;
BA_ "FlexKomSigStartValue" SG_ 999 BU_NetCfg_FDCM "0300000000000000h";
BA_ "GenSigSendType" SG_ 999 BU_NetCfg_FDCM 1;
BA_ "GenSigSNA" SG_ 999 BU_NetCfg_FDCM "0h";
BA_ "FlexKomComment" SG_ 999 BU_NetCfg_HCP "Backup for network ECU config data for Powertrain";
BA_ "FlexKomIsMotorola" SG_ 999 BU_NetCfg_HCP 1;
BA_ "FlexKomSID" SG_ 999 BU_NetCfg_HCP 872;
BA_ "FlexKomSigLaenge" SG_ 999 BU_NetCfg_HCP 64;
BA_ "FlexKomSigName" SG_ 999 BU_NetCfg_HCP "BU_NET_CFG_DATA_PT";
BA_ "FlexKomSigStartPos" SG_ 999 BU_NetCfg_HCP 7;
BA_ "FlexKomSigStartValue" SG_ 999 BU_NetCfg_HCP "0300000000000000h";
BA_ "GenSigSendType" SG_ 999 BU_NetCfg_HCP 1;
BA_ "GenSigSNA" SG_ 999 BU_NetCfg_HCP "0h";
BA_ "FlexKomComment" SG_ 999 BU_NetCfg_HaLF "Backup for network ECU config data for Powertrain";
BA_ "FlexKomIsMotorola" SG_ 999 BU_NetCfg_HaLF 1;
BA_ "FlexKomSID" SG_ 999 BU_NetCfg_HaLF 872;
BA_ "FlexKomSigLaenge" SG_ 999 BU_NetCfg_HaLF 64;
BA_ "FlexKomSigName" SG_ 999 BU_NetCfg_HaLF "BU_NET_CFG_DATA_PT";
BA_ "FlexKomSigStartPos" SG_ 999 BU_NetCfg_HaLF 7;
BA_ "FlexKomSigStartValue" SG_ 999 BU_NetCfg_HaLF "0300000000000000h";
BA_ "GenSigSendType" SG_ 999 BU_NetCfg_HaLF 1;
BA_ "GenSigSNA" SG_ 999 BU_NetCfg_HaLF "0h";
BA_ "FlexKomComment" SG_ 999 BU_NetCfg_IC "Backup for network ECU config data for Powertrain";
BA_ "FlexKomIsMotorola" SG_ 999 BU_NetCfg_IC 1;
BA_ "FlexKomSID" SG_ 999 BU_NetCfg_IC 872;
BA_ "FlexKomSigLaenge" SG_ 999 BU_NetCfg_IC 64;
BA_ "FlexKomSigName" SG_ 999 BU_NetCfg_IC "BU_NET_CFG_DATA_PT";
BA_ "FlexKomSigStartPos" SG_ 999 BU_NetCfg_IC 7;
BA_ "FlexKomSigStartValue" SG_ 999 BU_NetCfg_IC "0300000000000000h";
BA_ "GenSigSendType" SG_ 999 BU_NetCfg_IC 1;
BA_ "GenSigSNA" SG_ 999 BU_NetCfg_IC "0h";
BA_ "FlexKomComment" SG_ 999 BU_NetCfg_ITBM "Backup for network ECU config data for Powertrain";
BA_ "FlexKomIsMotorola" SG_ 999 BU_NetCfg_ITBM 1;
BA_ "FlexKomSID" SG_ 999 BU_NetCfg_ITBM 872;
BA_ "FlexKomSigLaenge" SG_ 999 BU_NetCfg_ITBM 64;
BA_ "FlexKomSigName" SG_ 999 BU_NetCfg_ITBM "BU_NET_CFG_DATA_PT";
BA_ "FlexKomSigStartPos" SG_ 999 BU_NetCfg_ITBM 7;
BA_ "FlexKomSigStartValue" SG_ 999 BU_NetCfg_ITBM "0300000000000000h";
BA_ "GenSigSendType" SG_ 999 BU_NetCfg_ITBM 1;
BA_ "GenSigSNA" SG_ 999 BU_NetCfg_ITBM "0h";
BA_ "FlexKomComment" SG_ 999 BU_NetCfg_OCM "Backup for network ECU config data for Powertrain";
BA_ "FlexKomIsMotorola" SG_ 999 BU_NetCfg_OCM 1;
BA_ "FlexKomSID" SG_ 999 BU_NetCfg_OCM 872;
BA_ "FlexKomSigLaenge" SG_ 999 BU_NetCfg_OCM 64;
BA_ "FlexKomSigName" SG_ 999 BU_NetCfg_OCM "BU_NET_CFG_DATA_PT";
BA_ "FlexKomSigStartPos" SG_ 999 BU_NetCfg_OCM 7;
BA_ "FlexKomSigStartValue" SG_ 999 BU_NetCfg_OCM "0300000000000000h";
BA_ "GenSigSendType" SG_ 999 BU_NetCfg_OCM 1;
BA_ "GenSigSNA" SG_ 999 BU_NetCfg_OCM "0h";
BA_ "FlexKomComment" SG_ 999 BU_NetCfg_ORC "Backup for network ECU config data for Powertrain";
BA_ "FlexKomIsMotorola" SG_ 999 BU_NetCfg_ORC 1;
BA_ "FlexKomSID" SG_ 999 BU_NetCfg_ORC 872;
BA_ "FlexKomSigLaenge" SG_ 999 BU_NetCfg_ORC 64;
BA_ "FlexKomSigName" SG_ 999 BU_NetCfg_ORC "BU_NET_CFG_DATA_PT";
BA_ "FlexKomSigStartPos" SG_ 999 BU_NetCfg_ORC 7;
BA_ "FlexKomSigStartValue" SG_ 999 BU_NetCfg_ORC "0300000000000000h";
BA_ "GenSigSendType" SG_ 999 BU_NetCfg_ORC 1;
BA_ "GenSigSNA" SG_ 999 BU_NetCfg_ORC "0h";
BA_ "FlexKomComment" SG_ 999 BU_NetCfg_PASS_PT "Backup for network ECU config data for Powertrain";
BA_ "FlexKomIsMotorola" SG_ 999 BU_NetCfg_PASS_PT 1;
BA_ "FlexKomSID" SG_ 999 BU_NetCfg_PASS_PT 872;
BA_ "FlexKomSigLaenge" SG_ 999 BU_NetCfg_PASS_PT 64;
BA_ "FlexKomSigName" SG_ 999 BU_NetCfg_PASS_PT "BU_NET_CFG_DATA_PT";
BA_ "FlexKomSigStartPos" SG_ 999 BU_NetCfg_PASS_PT 7;
BA_ "FlexKomSigStartValue" SG_ 999 BU_NetCfg_PASS_PT "0300000000000000h";
BA_ "GenSigSendType" SG_ 999 BU_NetCfg_PASS_PT 1;
BA_ "GenSigSNA" SG_ 999 BU_NetCfg_PASS_PT "0h";
BA_ "FlexKomComment" SG_ 999 BU_NetCfg_PTS "Backup for network ECU config data for Powertrain";
BA_ "FlexKomIsMotorola" SG_ 999 BU_NetCfg_PTS 1;
BA_ "FlexKomSID" SG_ 999 BU_NetCfg_PTS 872;
BA_ "FlexKomSigLaenge" SG_ 999 BU_NetCfg_PTS 64;
BA_ "FlexKomSigName" SG_ 999 BU_NetCfg_PTS "BU_NET_CFG_DATA_PT";
BA_ "FlexKomSigStartPos" SG_ 999 BU_NetCfg_PTS 7;
BA_ "FlexKomSigStartValue" SG_ 999 BU_NetCfg_PTS "0300000000000000h";
BA_ "GenSigSendType" SG_ 999 BU_NetCfg_PTS 1;
BA_ "GenSigSNA" SG_ 999 BU_NetCfg_PTS "0h";
BA_ "FlexKomComment" SG_ 999 BU_NetCfg_RF_HUB "Backup for network ECU config data for Powertrain";
BA_ "FlexKomIsMotorola" SG_ 999 BU_NetCfg_RF_HUB 1;
BA_ "FlexKomSID" SG_ 999 BU_NetCfg_RF_HUB 872;
BA_ "FlexKomSigLaenge" SG_ 999 BU_NetCfg_RF_HUB 64;
BA_ "FlexKomSigName" SG_ 999 BU_NetCfg_RF_HUB "BU_NET_CFG_DATA_PT";
BA_ "FlexKomSigStartPos" SG_ 999 BU_NetCfg_RF_HUB 7;
BA_ "FlexKomSigStartValue" SG_ 999 BU_NetCfg_RF_HUB "0300000000000000h";
BA_ "GenSigSendType" SG_ 999 BU_NetCfg_RF_HUB 1;
BA_ "GenSigSNA" SG_ 999 BU_NetCfg_RF_HUB "0h";
BA_ "FlexKomComment" SG_ 999 BU_NetCfg_RHSC2 "Backup for network ECU config data for Powertrain";
BA_ "FlexKomIsMotorola" SG_ 999 BU_NetCfg_RHSC2 1;
BA_ "FlexKomSID" SG_ 999 BU_NetCfg_RHSC2 872;
BA_ "FlexKomSigLaenge" SG_ 999 BU_NetCfg_RHSC2 64;
BA_ "FlexKomSigName" SG_ 999 BU_NetCfg_RHSC2 "BU_NET_CFG_DATA_PT";
BA_ "FlexKomSigStartPos" SG_ 999 BU_NetCfg_RHSC2 7;
BA_ "FlexKomSigStartValue" SG_ 999 BU_NetCfg_RHSC2 "0300000000000000h";
BA_ "GenSigSendType" SG_ 999 BU_NetCfg_RHSC2 1;
BA_ "GenSigSNA" SG_ 999 BU_NetCfg_RHSC2 "0h";
BA_ "FlexKomComment" SG_ 999 BU_NetCfg_SCCM "Backup for network ECU config data for Powertrain";
BA_ "FlexKomIsMotorola" SG_ 999 BU_NetCfg_SCCM 1;
BA_ "FlexKomSID" SG_ 999 BU_NetCfg_SCCM 872;
BA_ "FlexKomSigLaenge" SG_ 999 BU_NetCfg_SCCM 64;
BA_ "FlexKomSigName" SG_ 999 BU_NetCfg_SCCM "BU_NET_CFG_DATA_PT";
BA_ "FlexKomSigStartPos" SG_ 999 BU_NetCfg_SCCM 7;
BA_ "FlexKomSigStartValue" SG_ 999 BU_NetCfg_SCCM "0300000000000000h";
BA_ "GenSigSendType" SG_ 999 BU_NetCfg_SCCM 1;
BA_ "GenSigSNA" SG_ 999 BU_NetCfg_SCCM "0h";
BA_ "FlexKomComment" SG_ 999 BU_NetCfg_TCM "Backup for network ECU config data for Powertrain";
BA_ "FlexKomIsMotorola" SG_ 999 BU_NetCfg_TCM 1;
BA_ "FlexKomSID" SG_ 999 BU_NetCfg_TCM 872;
BA_ "FlexKomSigLaenge" SG_ 999 BU_NetCfg_TCM 64;
BA_ "FlexKomSigName" SG_ 999 BU_NetCfg_TCM "BU_NET_CFG_DATA_PT";
BA_ "FlexKomSigStartPos" SG_ 999 BU_NetCfg_TCM 7;
BA_ "FlexKomSigStartValue" SG_ 999 BU_NetCfg_TCM "0300000000000000h";
BA_ "GenSigSendType" SG_ 999 BU_NetCfg_TCM 1;
BA_ "GenSigSNA" SG_ 999 BU_NetCfg_TCM "0h";
BA_ "FlexKomComment" SG_ 999 BU_NetCfg_TPM "Backup for network ECU config data for Powertrain";
BA_ "FlexKomIsMotorola" SG_ 999 BU_NetCfg_TPM 1;
BA_ "FlexKomSID" SG_ 999 BU_NetCfg_TPM 872;
BA_ "FlexKomSigLaenge" SG_ 999 BU_NetCfg_TPM 64;
BA_ "FlexKomSigName" SG_ 999 BU_NetCfg_TPM "BU_NET_CFG_DATA_PT";
BA_ "FlexKomSigStartPos" SG_ 999 BU_NetCfg_TPM 7;
BA_ "FlexKomSigStartValue" SG_ 999 BU_NetCfg_TPM "0300000000000000h";
BA_ "GenSigSendType" SG_ 999 BU_NetCfg_TPM 1;
BA_ "GenSigSNA" SG_ 999 BU_NetCfg_TPM "0h";
BA_ "FlexKomComment" SG_ 999 BU_NetCfg_VSIM_C "Backup for network ECU config data for Powertrain";
BA_ "FlexKomIsMotorola" SG_ 999 BU_NetCfg_VSIM_C 1;
BA_ "FlexKomSID" SG_ 999 BU_NetCfg_VSIM_C 872;
BA_ "FlexKomSigLaenge" SG_ 999 BU_NetCfg_VSIM_C 64;
BA_ "FlexKomSigName" SG_ 999 BU_NetCfg_VSIM_C "BU_NET_CFG_DATA_PT";
BA_ "FlexKomSigStartPos" SG_ 999 BU_NetCfg_VSIM_C 7;
BA_ "FlexKomSigStartValue" SG_ 999 BU_NetCfg_VSIM_C "0300000000000000h";
BA_ "GenSigSendType" SG_ 999 BU_NetCfg_VSIM_C 1;
BA_ "GenSigSNA" SG_ 999 BU_NetCfg_VSIM_C "0h";
BA_ "FlexKomComment" SG_ 927 BU_NET_CFG_STAT_ePT "Backup for network ECU config data for hybrid netw";
BA_ "FlexKomIsMotorola" SG_ 927 BU_NET_CFG_STAT_ePT 1;
BA_ "FlexKomSID" SG_ 927 BU_NET_CFG_STAT_ePT 2470;
BA_ "FlexKomSigLaenge" SG_ 927 BU_NET_CFG_STAT_ePT 24;
BA_ "FlexKomSigName" SG_ 927 BU_NET_CFG_STAT_ePT "BU_NET_CFG_DATA_ePT";
BA_ "FlexKomSigStartPos" SG_ 927 BU_NET_CFG_STAT_ePT 7;
BA_ "FlexKomSigStartValue" SG_ 927 BU_NET_CFG_STAT_ePT "030000h";
BA_ "GenSigSendType" SG_ 927 BU_NET_CFG_STAT_ePT 1;
BA_ "GenSigSNA" SG_ 927 BU_NET_CFG_STAT_ePT "3h";
BA_ "GenSigStartValue" SG_ 927 BU_NET_CFG_STAT_ePT 3;
BA_ "FlexKomComment" SG_ 927 BU_NetCfg_AHCP_ePT "Backup for network ECU config data for hybrid netw";
BA_ "FlexKomIsMotorola" SG_ 927 BU_NetCfg_AHCP_ePT 1;
BA_ "FlexKomSID" SG_ 927 BU_NetCfg_AHCP_ePT 2470;
BA_ "FlexKomSigLaenge" SG_ 927 BU_NetCfg_AHCP_ePT 24;
BA_ "FlexKomSigName" SG_ 927 BU_NetCfg_AHCP_ePT "BU_NET_CFG_DATA_ePT";
BA_ "FlexKomSigStartPos" SG_ 927 BU_NetCfg_AHCP_ePT 7;
BA_ "FlexKomSigStartValue" SG_ 927 BU_NetCfg_AHCP_ePT "030000h";
BA_ "GenSigSendType" SG_ 927 BU_NetCfg_AHCP_ePT 1;
BA_ "GenSigSNA" SG_ 927 BU_NetCfg_AHCP_ePT "0h";
BA_ "FlexKomComment" SG_ 927 BU_NetCfg_APM_ePT "Backup for network ECU config data for hybrid netw";
BA_ "FlexKomIsMotorola" SG_ 927 BU_NetCfg_APM_ePT 1;
BA_ "FlexKomSID" SG_ 927 BU_NetCfg_APM_ePT 2470;
BA_ "FlexKomSigLaenge" SG_ 927 BU_NetCfg_APM_ePT 24;
BA_ "FlexKomSigName" SG_ 927 BU_NetCfg_APM_ePT "BU_NET_CFG_DATA_ePT";
BA_ "FlexKomSigStartPos" SG_ 927 BU_NetCfg_APM_ePT 7;
BA_ "FlexKomSigStartValue" SG_ 927 BU_NetCfg_APM_ePT "030000h";
BA_ "GenSigSendType" SG_ 927 BU_NetCfg_APM_ePT 1;
BA_ "GenSigSNA" SG_ 927 BU_NetCfg_APM_ePT "0h";
BA_ "FlexKomComment" SG_ 927 BU_NetCfg_BPCM_ePT "Backup for network ECU config data for hybrid netw";
BA_ "FlexKomIsMotorola" SG_ 927 BU_NetCfg_BPCM_ePT 1;
BA_ "FlexKomSID" SG_ 927 BU_NetCfg_BPCM_ePT 2470;
BA_ "FlexKomSigLaenge" SG_ 927 BU_NetCfg_BPCM_ePT 24;
BA_ "FlexKomSigName" SG_ 927 BU_NetCfg_BPCM_ePT "BU_NET_CFG_DATA_ePT";
BA_ "FlexKomSigStartPos" SG_ 927 BU_NetCfg_BPCM_ePT 7;
BA_ "FlexKomSigStartValue" SG_ 927 BU_NetCfg_BPCM_ePT "030000h";
BA_ "GenSigSendType" SG_ 927 BU_NetCfg_BPCM_ePT 1;
BA_ "GenSigSNA" SG_ 927 BU_NetCfg_BPCM_ePT "0h";
BA_ "FlexKomComment" SG_ 927 BU_NetCfg_BSMO_ePT "Backup for network ECU config data for hybrid netw";
BA_ "FlexKomIsMotorola" SG_ 927 BU_NetCfg_BSMO_ePT 1;
BA_ "FlexKomSID" SG_ 927 BU_NetCfg_BSMO_ePT 2470;
BA_ "FlexKomSigLaenge" SG_ 927 BU_NetCfg_BSMO_ePT 24;
BA_ "FlexKomSigName" SG_ 927 BU_NetCfg_BSMO_ePT "BU_NET_CFG_DATA_ePT";
BA_ "FlexKomSigStartPos" SG_ 927 BU_NetCfg_BSMO_ePT 7;
BA_ "FlexKomSigStartValue" SG_ 927 BU_NetCfg_BSMO_ePT "030000h";
BA_ "GenSigSendType" SG_ 927 BU_NetCfg_BSMO_ePT 1;
BA_ "GenSigSNA" SG_ 927 BU_NetCfg_BSMO_ePT "0h";
BA_ "FlexKomComment" SG_ 927 BU_NetCfg_EAC_ePT "Backup for network ECU config data for hybrid netw";
BA_ "FlexKomIsMotorola" SG_ 927 BU_NetCfg_EAC_ePT 1;
BA_ "FlexKomSID" SG_ 927 BU_NetCfg_EAC_ePT 2470;
BA_ "FlexKomSigLaenge" SG_ 927 BU_NetCfg_EAC_ePT 24;
BA_ "FlexKomSigName" SG_ 927 BU_NetCfg_EAC_ePT "BU_NET_CFG_DATA_ePT";
BA_ "FlexKomSigStartPos" SG_ 927 BU_NetCfg_EAC_ePT 7;
BA_ "FlexKomSigStartValue" SG_ 927 BU_NetCfg_EAC_ePT "030000h";
BA_ "GenSigSendType" SG_ 927 BU_NetCfg_EAC_ePT 1;
BA_ "GenSigSNA" SG_ 927 BU_NetCfg_EAC_ePT "0h";
BA_ "FlexKomComment" SG_ 927 BU_NetCfg_EBCM_ePT "Backup for network ECU config data for hybrid netw";
BA_ "FlexKomIsMotorola" SG_ 927 BU_NetCfg_EBCM_ePT 1;
BA_ "FlexKomSID" SG_ 927 BU_NetCfg_EBCM_ePT 2470;
BA_ "FlexKomSigLaenge" SG_ 927 BU_NetCfg_EBCM_ePT 24;
BA_ "FlexKomSigName" SG_ 927 BU_NetCfg_EBCM_ePT "BU_NET_CFG_DATA_ePT";
BA_ "FlexKomSigStartPos" SG_ 927 BU_NetCfg_EBCM_ePT 7;
BA_ "FlexKomSigStartValue" SG_ 927 BU_NetCfg_EBCM_ePT "030000h";
BA_ "GenSigSendType" SG_ 927 BU_NetCfg_EBCM_ePT 1;
BA_ "GenSigSNA" SG_ 927 BU_NetCfg_EBCM_ePT "0h";
BA_ "FlexKomComment" SG_ 927 BU_NetCfg_ECM_ePT "Backup for network ECU config data for hybrid netw";
BA_ "FlexKomIsMotorola" SG_ 927 BU_NetCfg_ECM_ePT 1;
BA_ "FlexKomSID" SG_ 927 BU_NetCfg_ECM_ePT 2470;
BA_ "FlexKomSigLaenge" SG_ 927 BU_NetCfg_ECM_ePT 24;
BA_ "FlexKomSigName" SG_ 927 BU_NetCfg_ECM_ePT "BU_NET_CFG_DATA_ePT";
BA_ "FlexKomSigStartPos" SG_ 927 BU_NetCfg_ECM_ePT 7;
BA_ "FlexKomSigStartValue" SG_ 927 BU_NetCfg_ECM_ePT "030000h";
BA_ "GenSigSendType" SG_ 927 BU_NetCfg_ECM_ePT 1;
BA_ "GenSigSNA" SG_ 927 BU_NetCfg_ECM_ePT "0h";
BA_ "FlexKomComment" SG_ 927 BU_NetCfg_ESC_ePT "Backup for network ECU config data for hybrid netw";
BA_ "FlexKomIsMotorola" SG_ 927 BU_NetCfg_ESC_ePT 1;
BA_ "FlexKomSID" SG_ 927 BU_NetCfg_ESC_ePT 2470;
BA_ "FlexKomSigLaenge" SG_ 927 BU_NetCfg_ESC_ePT 24;
BA_ "FlexKomSigName" SG_ 927 BU_NetCfg_ESC_ePT "BU_NET_CFG_DATA_ePT";
BA_ "FlexKomSigStartPos" SG_ 927 BU_NetCfg_ESC_ePT 7;
BA_ "FlexKomSigStartValue" SG_ 927 BU_NetCfg_ESC_ePT "030000h";
BA_ "GenSigSendType" SG_ 927 BU_NetCfg_ESC_ePT 1;
BA_ "GenSigSNA" SG_ 927 BU_NetCfg_ESC_ePT "0h";
BA_ "FlexKomComment" SG_ 927 BU_NetCfg_ESM_ePT "Backup for network ECU config data for hybrid netw";
BA_ "FlexKomIsMotorola" SG_ 927 BU_NetCfg_ESM_ePT 1;
BA_ "FlexKomSID" SG_ 927 BU_NetCfg_ESM_ePT 2470;
BA_ "FlexKomSigLaenge" SG_ 927 BU_NetCfg_ESM_ePT 24;
BA_ "FlexKomSigName" SG_ 927 BU_NetCfg_ESM_ePT "BU_NET_CFG_DATA_ePT";
BA_ "FlexKomSigStartPos" SG_ 927 BU_NetCfg_ESM_ePT 7;
BA_ "FlexKomSigStartValue" SG_ 927 BU_NetCfg_ESM_ePT "030000h";
BA_ "GenSigSendType" SG_ 927 BU_NetCfg_ESM_ePT 1;
BA_ "GenSigSNA" SG_ 927 BU_NetCfg_ESM_ePT "0h";
BA_ "FlexKomComment" SG_ 927 BU_NetCfg_HCP_ePT "Backup for network ECU config data for hybrid netw";
BA_ "FlexKomIsMotorola" SG_ 927 BU_NetCfg_HCP_ePT 1;
BA_ "FlexKomSID" SG_ 927 BU_NetCfg_HCP_ePT 2470;
BA_ "FlexKomSigLaenge" SG_ 927 BU_NetCfg_HCP_ePT 24;
BA_ "FlexKomSigName" SG_ 927 BU_NetCfg_HCP_ePT "BU_NET_CFG_DATA_ePT";
BA_ "FlexKomSigStartPos" SG_ 927 BU_NetCfg_HCP_ePT 7;
BA_ "FlexKomSigStartValue" SG_ 927 BU_NetCfg_HCP_ePT "030000h";
BA_ "GenSigSendType" SG_ 927 BU_NetCfg_HCP_ePT 1;
BA_ "GenSigSNA" SG_ 927 BU_NetCfg_HCP_ePT "0h";
BA_ "FlexKomComment" SG_ 927 BU_NetCfg_OBCM_ePT "Backup for network ECU config data for hybrid netw";
BA_ "FlexKomIsMotorola" SG_ 927 BU_NetCfg_OBCM_ePT 1;
BA_ "FlexKomSID" SG_ 927 BU_NetCfg_OBCM_ePT 2470;
BA_ "FlexKomSigLaenge" SG_ 927 BU_NetCfg_OBCM_ePT 24;
BA_ "FlexKomSigName" SG_ 927 BU_NetCfg_OBCM_ePT "BU_NET_CFG_DATA_ePT";
BA_ "FlexKomSigStartPos" SG_ 927 BU_NetCfg_OBCM_ePT 7;
BA_ "FlexKomSigStartValue" SG_ 927 BU_NetCfg_OBCM_ePT "030000h";
BA_ "GenSigSendType" SG_ 927 BU_NetCfg_OBCM_ePT 1;
BA_ "GenSigSNA" SG_ 927 BU_NetCfg_OBCM_ePT "0h";
BA_ "FlexKomComment" SG_ 927 BU_NetCfg_ORC_ePT "Backup for network ECU config data for hybrid netw";
BA_ "FlexKomIsMotorola" SG_ 927 BU_NetCfg_ORC_ePT 1;
BA_ "FlexKomSID" SG_ 927 BU_NetCfg_ORC_ePT 2470;
BA_ "FlexKomSigLaenge" SG_ 927 BU_NetCfg_ORC_ePT 24;
BA_ "FlexKomSigName" SG_ 927 BU_NetCfg_ORC_ePT "BU_NET_CFG_DATA_ePT";
BA_ "FlexKomSigStartPos" SG_ 927 BU_NetCfg_ORC_ePT 7;
BA_ "FlexKomSigStartValue" SG_ 927 BU_NetCfg_ORC_ePT "030000h";
BA_ "GenSigSendType" SG_ 927 BU_NetCfg_ORC_ePT 1;
BA_ "GenSigSNA" SG_ 927 BU_NetCfg_ORC_ePT "0h";
BA_ "FlexKomComment" SG_ 927 BU_NetCfg_SCA_ePT "Backup for network ECU config data for hybrid netw";
BA_ "FlexKomIsMotorola" SG_ 927 BU_NetCfg_SCA_ePT 1;
BA_ "FlexKomSID" SG_ 927 BU_NetCfg_SCA_ePT 2470;
BA_ "FlexKomSigLaenge" SG_ 927 BU_NetCfg_SCA_ePT 24;
BA_ "FlexKomSigName" SG_ 927 BU_NetCfg_SCA_ePT "BU_NET_CFG_DATA_ePT";
BA_ "FlexKomSigStartPos" SG_ 927 BU_NetCfg_SCA_ePT 7;
BA_ "FlexKomSigStartValue" SG_ 927 BU_NetCfg_SCA_ePT "030000h";
BA_ "GenSigSendType" SG_ 927 BU_NetCfg_SCA_ePT 1;
BA_ "GenSigSNA" SG_ 927 BU_NetCfg_SCA_ePT "0h";
BA_ "FlexKomComment" SG_ 937 CFG_AUTO_WPR "Configuration status CBC";
BA_ "FlexKomIsMotorola" SG_ 937 CFG_AUTO_WPR 1;
BA_ "FlexKomSID" SG_ 937 CFG_AUTO_WPR 843;
BA_ "FlexKomSigLaenge" SG_ 937 CFG_AUTO_WPR 48;
BA_ "FlexKomSigName" SG_ 937 CFG_AUTO_WPR "CBC_CFG_STAT";
BA_ "FlexKomSigStartPos" SG_ 937 CFG_AUTO_WPR 7;
BA_ "FlexKomSigStartValue" SG_ 937 CFG_AUTO_WPR "00FFFFFFFF00h";
BA_ "GenSigCycleTime" SG_ 937 CFG_AUTO_WPR 1000;
BA_ "GenSigSendType" SG_ 937 CFG_AUTO_WPR 5;
BA_ "GenSigSNA" SG_ 937 CFG_AUTO_WPR "0h";
BA_ "GenSigTimeout_IC" SG_ 937 CFG_AUTO_WPR 10500;
BA_ "FlexKomComment" SG_ 937 DRL_ON "Configuration status CBC";
BA_ "FlexKomIsMotorola" SG_ 937 DRL_ON 1;
BA_ "FlexKomSID" SG_ 937 DRL_ON 843;
BA_ "FlexKomSigLaenge" SG_ 937 DRL_ON 48;
BA_ "FlexKomSigName" SG_ 937 DRL_ON "CBC_CFG_STAT";
BA_ "FlexKomSigStartPos" SG_ 937 DRL_ON 7;
BA_ "FlexKomSigStartValue" SG_ 937 DRL_ON "00FFFFFFFF00h";
BA_ "GenSigCycleTime" SG_ 937 DRL_ON 1000;
BA_ "GenSigSendType" SG_ 937 DRL_ON 5;
BA_ "GenSigSNA" SG_ 937 DRL_ON "0h";
BA_ "GenSigTimeout_IC" SG_ 937 DRL_ON 10500;
BA_ "FlexKomComment" SG_ 937 FLASH_LK "Configuration status CBC";
BA_ "FlexKomIsMotorola" SG_ 937 FLASH_LK 1;
BA_ "FlexKomSID" SG_ 937 FLASH_LK 843;
BA_ "FlexKomSigLaenge" SG_ 937 FLASH_LK 48;
BA_ "FlexKomSigName" SG_ 937 FLASH_LK "CBC_CFG_STAT";
BA_ "FlexKomSigStartPos" SG_ 937 FLASH_LK 7;
BA_ "FlexKomSigStartValue" SG_ 937 FLASH_LK "00FFFFFFFF00h";
BA_ "GenSigCycleTime" SG_ 937 FLASH_LK 1000;
BA_ "GenSigSendType" SG_ 937 FLASH_LK 5;
BA_ "GenSigSNA" SG_ 937 FLASH_LK "0h";
BA_ "GenSigTimeout_IC" SG_ 937 FLASH_LK 10500;
BA_ "FlexKomComment" SG_ 937 HL_DLY_TIME "Configuration status CBC";
BA_ "FlexKomIsMotorola" SG_ 937 HL_DLY_TIME 1;
BA_ "FlexKomSID" SG_ 937 HL_DLY_TIME 843;
BA_ "FlexKomSigLaenge" SG_ 937 HL_DLY_TIME 48;
BA_ "FlexKomSigName" SG_ 937 HL_DLY_TIME "CBC_CFG_STAT";
BA_ "FlexKomSigStartPos" SG_ 937 HL_DLY_TIME 7;
BA_ "FlexKomSigStartValue" SG_ 937 HL_DLY_TIME "00FFFFFFFF00h";
BA_ "GenSigCycleTime" SG_ 937 HL_DLY_TIME 1000;
BA_ "GenSigSendType" SG_ 937 HL_DLY_TIME 5;
BA_ "GenSigSNA" SG_ 937 HL_DLY_TIME "FFh";
BA_ "GenSigStartValue" SG_ 937 HL_DLY_TIME 255;
BA_ "GenSigTimeout_IC" SG_ 937 HL_DLY_TIME 10500;
BA_ "FlexKomComment" SG_ 937 HL_WPR "Configuration status CBC";
BA_ "FlexKomIsMotorola" SG_ 937 HL_WPR 1;
BA_ "FlexKomSID" SG_ 937 HL_WPR 843;
BA_ "FlexKomSigLaenge" SG_ 937 HL_WPR 48;
BA_ "FlexKomSigName" SG_ 937 HL_WPR "CBC_CFG_STAT";
BA_ "FlexKomSigStartPos" SG_ 937 HL_WPR 7;
BA_ "FlexKomSigStartValue" SG_ 937 HL_WPR "00FFFFFFFF00h";
BA_ "GenSigCycleTime" SG_ 937 HL_WPR 1000;
BA_ "GenSigSendType" SG_ 937 HL_WPR 5;
BA_ "GenSigSNA" SG_ 937 HL_WPR "0h";
BA_ "GenSigTimeout_IC" SG_ 937 HL_WPR 10500;
BA_ "FlexKomComment" SG_ 937 ILL_APRCH_TIME "Configuration status CBC";
BA_ "FlexKomIsMotorola" SG_ 937 ILL_APRCH_TIME 1;
BA_ "FlexKomSID" SG_ 937 ILL_APRCH_TIME 843;
BA_ "FlexKomSigLaenge" SG_ 937 ILL_APRCH_TIME 48;
BA_ "FlexKomSigName" SG_ 937 ILL_APRCH_TIME "CBC_CFG_STAT";
BA_ "FlexKomSigStartPos" SG_ 937 ILL_APRCH_TIME 7;
BA_ "FlexKomSigStartValue" SG_ 937 ILL_APRCH_TIME "00FFFFFFFF00h";
BA_ "GenSigCycleTime" SG_ 937 ILL_APRCH_TIME 1000;
BA_ "GenSigSendType" SG_ 937 ILL_APRCH_TIME 5;
BA_ "GenSigSNA" SG_ 937 ILL_APRCH_TIME "FFh";
BA_ "GenSigStartValue" SG_ 937 ILL_APRCH_TIME 255;
BA_ "GenSigTimeout_IC" SG_ 937 ILL_APRCH_TIME 10500;
BA_ "FlexKomComment" SG_ 937 SOUND_LK "Configuration status CBC";
BA_ "FlexKomIsMotorola" SG_ 937 SOUND_LK 1;
BA_ "FlexKomSID" SG_ 937 SOUND_LK 843;
BA_ "FlexKomSigLaenge" SG_ 937 SOUND_LK 48;
BA_ "FlexKomSigName" SG_ 937 SOUND_LK "CBC_CFG_STAT";
BA_ "FlexKomSigStartPos" SG_ 937 SOUND_LK 7;
BA_ "FlexKomSigStartValue" SG_ 937 SOUND_LK "00FFFFFFFF00h";
BA_ "GenSigCycleTime" SG_ 937 SOUND_LK 1000;
BA_ "GenSigSendType" SG_ 937 SOUND_LK 5;
BA_ "GenSigSNA" SG_ 937 SOUND_LK "0h";
BA_ "GenSigTimeout_IC" SG_ 937 SOUND_LK 10500;
BA_ "FlexKomComment" SG_ 937 SOUND_LK_1ST_2ND "Sound horn on lock status";
BA_ "FlexKomIsMotorola" SG_ 937 SOUND_LK_1ST_2ND 1;
BA_ "FlexKomSID" SG_ 937 SOUND_LK_1ST_2ND 1956;
BA_ "FlexKomSigLaenge" SG_ 937 SOUND_LK_1ST_2ND 2;
BA_ "FlexKomSigName" SG_ 937 SOUND_LK_1ST_2ND "SOUND_LK_1ST_2ND";
BA_ "FlexKomSigStartPos" SG_ 937 SOUND_LK_1ST_2ND 57;
BA_ "FlexKomSigStartValue" SG_ 937 SOUND_LK_1ST_2ND "03h";
BA_ "GenSigCycleTime" SG_ 937 SOUND_LK_1ST_2ND 1000;
BA_ "GenSigSendType" SG_ 937 SOUND_LK_1ST_2ND 5;
BA_ "GenSigSNA" SG_ 937 SOUND_LK_1ST_2ND "3h";
BA_ "GenSigStartValue" SG_ 937 SOUND_LK_1ST_2ND 3;
BA_ "GenSigTimeout_IC" SG_ 937 SOUND_LK_1ST_2ND 10500;
BA_ "FlexKomComment" SG_ 937 SOUND_RS "Sound horn on Remote Start ; no = [0], yes = [1]";
BA_ "FlexKomIsMotorola" SG_ 937 SOUND_RS 1;
BA_ "FlexKomSID" SG_ 937 SOUND_RS 966;
BA_ "FlexKomSigLaenge" SG_ 937 SOUND_RS 1;
BA_ "FlexKomSigName" SG_ 937 SOUND_RS "SOUND_RS";
BA_ "FlexKomSigStartPos" SG_ 937 SOUND_RS 52;
BA_ "FlexKomSigStartValue" SG_ 937 SOUND_RS "00h";
BA_ "GenSigCycleTime" SG_ 937 SOUND_RS 1000;
BA_ "GenSigSendType" SG_ 937 SOUND_RS 5;
BA_ "GenSigSNA" SG_ 937 SOUND_RS "0h";
BA_ "GenSigTimeout_IC" SG_ 937 SOUND_RS 10500;
BA_ "FlexKomComment" SG_ 820 AHB_ACT "Automatic high beam active";
BA_ "FlexKomIsMotorola" SG_ 820 AHB_ACT 1;
BA_ "FlexKomSID" SG_ 820 AHB_ACT 732;
BA_ "FlexKomSigLaenge" SG_ 820 AHB_ACT 1;
BA_ "FlexKomSigName" SG_ 820 AHB_ACT "AHB_ACT";
BA_ "FlexKomSigStartPos" SG_ 820 AHB_ACT 14;
BA_ "FlexKomSigStartValue" SG_ 820 AHB_ACT "00h";
BA_ "GenSigCycleTime" SG_ 820 AHB_ACT 1000;
BA_ "GenSigSendType" SG_ 820 AHB_ACT 5;
BA_ "GenSigSNA" SG_ 820 AHB_ACT "0h";
BA_ "GenSigTimeout_IC" SG_ 820 AHB_ACT 10500;
BA_ "RID" SG_ 820 AHB_ACT "971";
BA_ "FlexKomComment" SG_ 820 BRK_FLUID_LO "Low brake fluid warning; low = [1]";
BA_ "FlexKomIsMotorola" SG_ 820 BRK_FLUID_LO 1;
BA_ "FlexKomSID" SG_ 820 BRK_FLUID_LO 885;
BA_ "FlexKomSigLaenge" SG_ 820 BRK_FLUID_LO 1;
BA_ "FlexKomSigName" SG_ 820 BRK_FLUID_LO "BRK_FLUID_LO";
BA_ "FlexKomSigStartPos" SG_ 820 BRK_FLUID_LO 62;
BA_ "FlexKomSigStartValue" SG_ 820 BRK_FLUID_LO "00h";
BA_ "GenSigCycleTime" SG_ 820 BRK_FLUID_LO 1000;
BA_ "GenSigSendType" SG_ 820 BRK_FLUID_LO 5;
BA_ "GenSigSNA" SG_ 820 BRK_FLUID_LO "0h";
BA_ "GenSigTimeout_ETM" SG_ 820 BRK_FLUID_LO 10500;
BA_ "GenSigTimeout_IC" SG_ 820 BRK_FLUID_LO 10500;
BA_ "FlexKomComment" SG_ 820 DAY_LGT_MD "Interior lighting status powertrain";
BA_ "FlexKomIsMotorola" SG_ 820 DAY_LGT_MD 1;
BA_ "FlexKomSID" SG_ 820 DAY_LGT_MD 1417;
BA_ "FlexKomSigLaenge" SG_ 820 DAY_LGT_MD 24;
BA_ "FlexKomSigName" SG_ 820 DAY_LGT_MD "IntLtSt_PT";
BA_ "FlexKomSigStartPos" SG_ 820 DAY_LGT_MD 47;
BA_ "FlexKomSigStartValue" SG_ 820 DAY_LGT_MD "000000h";
BA_ "GenSigCycleTime" SG_ 820 DAY_LGT_MD 1000;
BA_ "GenSigSendType" SG_ 820 DAY_LGT_MD 5;
BA_ "GenSigSNA" SG_ 820 DAY_LGT_MD "0h";
BA_ "GenSigTimeout_RHSC2" SG_ 820 DAY_LGT_MD 10500;
BA_ "GenSigTimeout_IC" SG_ 820 DAY_LGT_MD 10500;
BA_ "GenSigTimeout_RF_HUB" SG_ 820 DAY_LGT_MD 10500;
BA_ "GenSigTimeout_SCCM" SG_ 820 DAY_LGT_MD 10500;
BA_ "RID" SG_ 820 DAY_LGT_MD "9743";
BA_ "FlexKomComment" SG_ 820 DRV_AJAR "Door ajar";
BA_ "FlexKomIsMotorola" SG_ 820 DRV_AJAR 1;
BA_ "FlexKomSID" SG_ 820 DRV_AJAR 797;
BA_ "FlexKomSigLaenge" SG_ 820 DRV_AJAR 6;
BA_ "FlexKomSigName" SG_ 820 DRV_AJAR "DR_AJAR";
BA_ "FlexKomSigStartPos" SG_ 820 DRV_AJAR 22;
BA_ "FlexKomSigStartValue" SG_ 820 DRV_AJAR "00h";
BA_ "GenSigCycleTime" SG_ 820 DRV_AJAR 1000;
BA_ "GenSigSendType" SG_ 820 DRV_AJAR 5;
BA_ "GenSigSNA" SG_ 820 DRV_AJAR "0h";
BA_ "GenSigTimeout_IC" SG_ 820 DRV_AJAR 10500;
BA_ "GenSigTimeout_RF_HUB" SG_ 820 DRV_AJAR 10500;
BA_ "FlexKomComment" SG_ 820 DR_LK_STAT "Door lock status";
BA_ "FlexKomIsMotorola" SG_ 820 DR_LK_STAT 1;
BA_ "FlexKomSID" SG_ 820 DR_LK_STAT 861;
BA_ "FlexKomSigLaenge" SG_ 820 DR_LK_STAT 2;
BA_ "FlexKomSigName" SG_ 820 DR_LK_STAT "DR_LK_STAT";
BA_ "FlexKomSigStartPos" SG_ 820 DR_LK_STAT 6;
BA_ "FlexKomSigStartValue" SG_ 820 DR_LK_STAT "03h";
BA_ "GenSigCycleTime" SG_ 820 DR_LK_STAT 1000;
BA_ "GenSigSendType" SG_ 820 DR_LK_STAT 5;
BA_ "GenSigSNA" SG_ 820 DR_LK_STAT "3h";
BA_ "GenSigStartValue" SG_ 820 DR_LK_STAT 3;
BA_ "GenSigTimeout_IC" SG_ 820 DR_LK_STAT 10500;
BA_ "GenSigTimeout_RF_HUB" SG_ 820 DR_LK_STAT 10500;
BA_ "FlexKomComment" SG_ 820 FOB_SrchRq "FOB search request";
BA_ "FlexKomIsMotorola" SG_ 820 FOB_SrchRq 1;
BA_ "FlexKomSID" SG_ 820 FOB_SrchRq 1392;
BA_ "FlexKomSigLaenge" SG_ 820 FOB_SrchRq 2;
BA_ "FlexKomSigName" SG_ 820 FOB_SrchRq "FOB_SrchRq";
BA_ "FlexKomSigStartPos" SG_ 820 FOB_SrchRq 9;
BA_ "FlexKomSigStartValue" SG_ 820 FOB_SrchRq "00h";
BA_ "GenSigCycleTime" SG_ 820 FOB_SrchRq 1000;
BA_ "GenSigSendType" SG_ 820 FOB_SrchRq 5;
BA_ "GenSigSNA" SG_ 820 FOB_SrchRq "0h";
BA_ "GenSigTimeout_RF_HUB" SG_ 820 FOB_SrchRq 5500;
BA_ "FlexKomComment" SG_ 820 FT_FOG_RQ "Front fog request; off=[0], on=[1]";
BA_ "FlexKomIsMotorola" SG_ 820 FT_FOG_RQ 1;
BA_ "FlexKomSID" SG_ 820 FT_FOG_RQ 758;
BA_ "FlexKomSigLaenge" SG_ 820 FT_FOG_RQ 1;
BA_ "FlexKomSigName" SG_ 820 FT_FOG_RQ "FT_FOG_RQ";
BA_ "FlexKomSigStartPos" SG_ 820 FT_FOG_RQ 2;
BA_ "FlexKomSigStartValue" SG_ 820 FT_FOG_RQ "00h";
BA_ "GenSigCycleTime" SG_ 820 FT_FOG_RQ 1000;
BA_ "GenSigSendType" SG_ 820 FT_FOG_RQ 5;
BA_ "GenSigSNA" SG_ 820 FT_FOG_RQ "0h";
BA_ "GenSigTimeout_IC" SG_ 820 FT_FOG_RQ 10500;
BA_ "FlexKomComment" SG_ 820 FT_WPR_NOT_PRK "Front wiper outside park position";
BA_ "FlexKomIsMotorola" SG_ 820 FT_WPR_NOT_PRK 1;
BA_ "FlexKomSID" SG_ 820 FT_WPR_NOT_PRK 1046;
BA_ "FlexKomSigLaenge" SG_ 820 FT_WPR_NOT_PRK 1;
BA_ "FlexKomSigName" SG_ 820 FT_WPR_NOT_PRK "FT_WPR_NOT_PRK";
BA_ "FlexKomSigStartPos" SG_ 820 FT_WPR_NOT_PRK 56;
BA_ "FlexKomSigStartValue" SG_ 820 FT_WPR_NOT_PRK "00h";
BA_ "GenSigCycleTime" SG_ 820 FT_WPR_NOT_PRK 1000;
BA_ "GenSigSendType" SG_ 820 FT_WPR_NOT_PRK 5;
BA_ "GenSigSNA" SG_ 820 FT_WPR_NOT_PRK "0h";
BA_ "FlexKomComment" SG_ 820 HIBEAM_ON "High beam is on; off=[0], on=[1]";
BA_ "FlexKomIsMotorola" SG_ 820 HIBEAM_ON 1;
BA_ "FlexKomSID" SG_ 820 HIBEAM_ON 884;
BA_ "FlexKomSigLaenge" SG_ 820 HIBEAM_ON 1;
BA_ "FlexKomSigName" SG_ 820 HIBEAM_ON "HIBEAM_ON";
BA_ "FlexKomSigStartPos" SG_ 820 HIBEAM_ON 58;
BA_ "FlexKomSigStartValue" SG_ 820 HIBEAM_ON "00h";
BA_ "GenSigCycleTime" SG_ 820 HIBEAM_ON 1000;
BA_ "GenSigSendType" SG_ 820 HIBEAM_ON 5;
BA_ "GenSigSNA" SG_ 820 HIBEAM_ON "0h";
BA_ "GenSigTimeout_IC" SG_ 820 HIBEAM_ON 10500;
BA_ "FlexKomComment" SG_ 820 IGN_OFF_TIME_LNG "Time since last ignition on (long)";
BA_ "FlexKomIsMotorola" SG_ 820 IGN_OFF_TIME_LNG 1;
BA_ "FlexKomSID" SG_ 820 IGN_OFF_TIME_LNG 998;
BA_ "FlexKomSigLaenge" SG_ 820 IGN_OFF_TIME_LNG 16;
BA_ "FlexKomSigName" SG_ 820 IGN_OFF_TIME_LNG "IGN_OFF_TIME_LNG";
BA_ "FlexKomSigStartPos" SG_ 820 IGN_OFF_TIME_LNG 31;
BA_ "FlexKomSigStartValue" SG_ 820 IGN_OFF_TIME_LNG "0FFFh";
BA_ "GenSigCycleTime" SG_ 820 IGN_OFF_TIME_LNG 1000;
BA_ "GenSigSendType" SG_ 820 IGN_OFF_TIME_LNG 5;
BA_ "GenSigSNA" SG_ 820 IGN_OFF_TIME_LNG "FFFh";
BA_ "GenSigStartValue" SG_ 820 IGN_OFF_TIME_LNG 4095;
BA_ "GenSigTimeout_IC" SG_ 820 IGN_OFF_TIME_LNG 10500;
BA_ "GenSigTimeout_RF_HUB" SG_ 820 IGN_OFF_TIME_LNG 10500;
BA_ "FlexKomComment" SG_ 820 LOBEAM_ON "Low beam is on; off=[0], on=[1]";
BA_ "FlexKomIsMotorola" SG_ 820 LOBEAM_ON 1;
BA_ "FlexKomSID" SG_ 820 LOBEAM_ON 883;
BA_ "FlexKomSigLaenge" SG_ 820 LOBEAM_ON 1;
BA_ "FlexKomSigName" SG_ 820 LOBEAM_ON "LOBEAM_ON";
BA_ "FlexKomSigStartPos" SG_ 820 LOBEAM_ON 57;
BA_ "FlexKomSigStartValue" SG_ 820 LOBEAM_ON "00h";
BA_ "GenSigCycleTime" SG_ 820 LOBEAM_ON 1000;
BA_ "GenSigSendType" SG_ 820 LOBEAM_ON 5;
BA_ "GenSigSNA" SG_ 820 LOBEAM_ON "0h";
BA_ "GenSigTimeout_IC" SG_ 820 LOBEAM_ON 10500;
BA_ "FlexKomComment" SG_ 820 L_R_AJAR "Door ajar";
BA_ "FlexKomIsMotorola" SG_ 820 L_R_AJAR 1;
BA_ "FlexKomSID" SG_ 820 L_R_AJAR 797;
BA_ "FlexKomSigLaenge" SG_ 820 L_R_AJAR 6;
BA_ "FlexKomSigName" SG_ 820 L_R_AJAR "DR_AJAR";
BA_ "FlexKomSigStartPos" SG_ 820 L_R_AJAR 22;
BA_ "FlexKomSigStartValue" SG_ 820 L_R_AJAR "00h";
BA_ "GenSigCycleTime" SG_ 820 L_R_AJAR 1000;
BA_ "GenSigSendType" SG_ 820 L_R_AJAR 5;
BA_ "GenSigSNA" SG_ 820 L_R_AJAR "0h";
BA_ "GenSigTimeout_IC" SG_ 820 L_R_AJAR 10500;
BA_ "GenSigTimeout_RF_HUB" SG_ 820 L_R_AJAR 10500;
BA_ "FlexKomComment" SG_ 820 PANEL_INTS "Interior lighting status powertrain";
BA_ "FlexKomIsMotorola" SG_ 820 PANEL_INTS 1;
BA_ "FlexKomSID" SG_ 820 PANEL_INTS 1417;
BA_ "FlexKomSigLaenge" SG_ 820 PANEL_INTS 24;
BA_ "FlexKomSigName" SG_ 820 PANEL_INTS "IntLtSt_PT";
BA_ "FlexKomSigStartPos" SG_ 820 PANEL_INTS 47;
BA_ "FlexKomSigStartValue" SG_ 820 PANEL_INTS "000000h";
BA_ "GenSigCycleTime" SG_ 820 PANEL_INTS 1000;
BA_ "GenSigSendType" SG_ 820 PANEL_INTS 5;
BA_ "GenSigSNA" SG_ 820 PANEL_INTS "FFh";
BA_ "GenSigTimeout_RHSC2" SG_ 820 PANEL_INTS 10500;
BA_ "GenSigTimeout_IC" SG_ 820 PANEL_INTS 10500;
BA_ "GenSigTimeout_RF_HUB" SG_ 820 PANEL_INTS 10500;
BA_ "GenSigTimeout_SCCM" SG_ 820 PANEL_INTS 10500;
BA_ "RID" SG_ 820 PANEL_INTS "9744";
BA_ "FlexKomComment" SG_ 820 PARK_LMP_ON "Parklamps are on; off=[0], on=[1]";
BA_ "FlexKomIsMotorola" SG_ 820 PARK_LMP_ON 1;
BA_ "FlexKomSID" SG_ 820 PARK_LMP_ON 767;
BA_ "FlexKomSigLaenge" SG_ 820 PARK_LMP_ON 1;
BA_ "FlexKomSigName" SG_ 820 PARK_LMP_ON "PARK_LMP_ON";
BA_ "FlexKomSigStartPos" SG_ 820 PARK_LMP_ON 16;
BA_ "FlexKomSigStartValue" SG_ 820 PARK_LMP_ON "00h";
BA_ "GenSigCycleTime" SG_ 820 PARK_LMP_ON 1000;
BA_ "GenSigSendType" SG_ 820 PARK_LMP_ON 5;
BA_ "GenSigSNA" SG_ 820 PARK_LMP_ON "0h";
BA_ "GenSigTimeout_IC" SG_ 820 PARK_LMP_ON 10500;
BA_ "FlexKomComment" SG_ 820 PSG_AJAR "Door ajar";
BA_ "FlexKomIsMotorola" SG_ 820 PSG_AJAR 1;
BA_ "FlexKomSID" SG_ 820 PSG_AJAR 797;
BA_ "FlexKomSigLaenge" SG_ 820 PSG_AJAR 6;
BA_ "FlexKomSigName" SG_ 820 PSG_AJAR "DR_AJAR";
BA_ "FlexKomSigStartPos" SG_ 820 PSG_AJAR 22;
BA_ "FlexKomSigStartValue" SG_ 820 PSG_AJAR "00h";
BA_ "GenSigCycleTime" SG_ 820 PSG_AJAR 1000;
BA_ "GenSigSendType" SG_ 820 PSG_AJAR 5;
BA_ "GenSigSNA" SG_ 820 PSG_AJAR "0h";
BA_ "GenSigTimeout_IC" SG_ 820 PSG_AJAR 10500;
BA_ "GenSigTimeout_ORC" SG_ 820 PSG_AJAR 3500;
BA_ "GenSigTimeout_RF_HUB" SG_ 820 PSG_AJAR 10500;
BA_ "FlexKomComment" SG_ 820 REV_GEAR "Reverse Gear (manual trans)";
BA_ "FlexKomIsMotorola" SG_ 820 REV_GEAR 1;
BA_ "FlexKomSID" SG_ 820 REV_GEAR 685;
BA_ "FlexKomSigLaenge" SG_ 820 REV_GEAR 1;
BA_ "FlexKomSigName" SG_ 820 REV_GEAR "REV_GEAR";
BA_ "FlexKomSigStartPos" SG_ 820 REV_GEAR 4;
BA_ "FlexKomSigStartValue" SG_ 820 REV_GEAR "00h";
BA_ "GenSigCycleTime" SG_ 820 REV_GEAR 1000;
BA_ "GenSigSendType" SG_ 820 REV_GEAR 5;
BA_ "GenSigSNA" SG_ 820 REV_GEAR "0h";
BA_ "GenSigTimeout_IC" SG_ 820 REV_GEAR 10500;
BA_ "GenSigTimeout_ORC" SG_ 820 REV_GEAR 3500;
BA_ "GenSigTimeout_PTS" SG_ 820 REV_GEAR 3500;
BA_ "GenSigTimeout_RF_HUB" SG_ 820 REV_GEAR 10500;
BA_ "RID" SG_ 820 REV_GEAR "9766";
BA_ "FlexKomComment" SG_ 820 R_FOG_RQ "Rear fog request; [0] = off, [1] = on";
BA_ "FlexKomIsMotorola" SG_ 820 R_FOG_RQ 1;
BA_ "FlexKomSID" SG_ 820 R_FOG_RQ 427;
BA_ "FlexKomSigLaenge" SG_ 820 R_FOG_RQ 1;
BA_ "FlexKomSigName" SG_ 820 R_FOG_RQ "R_FOG_RQ";
BA_ "FlexKomSigStartPos" SG_ 820 R_FOG_RQ 3;
BA_ "FlexKomSigStartValue" SG_ 820 R_FOG_RQ "00h";
BA_ "GenSigCycleTime" SG_ 820 R_FOG_RQ 1000;
BA_ "GenSigSendType" SG_ 820 R_FOG_RQ 5;
BA_ "GenSigSNA" SG_ 820 R_FOG_RQ "0h";
BA_ "GenSigTimeout_IC" SG_ 820 R_FOG_RQ 10500;
BA_ "FlexKomComment" SG_ 820 R_R_AJAR "Door ajar";
BA_ "FlexKomIsMotorola" SG_ 820 R_R_AJAR 1;
BA_ "FlexKomSID" SG_ 820 R_R_AJAR 797;
BA_ "FlexKomSigLaenge" SG_ 820 R_R_AJAR 6;
BA_ "FlexKomSigName" SG_ 820 R_R_AJAR "DR_AJAR";
BA_ "FlexKomSigStartPos" SG_ 820 R_R_AJAR 22;
BA_ "FlexKomSigStartValue" SG_ 820 R_R_AJAR "00h";
BA_ "GenSigCycleTime" SG_ 820 R_R_AJAR 1000;
BA_ "GenSigSendType" SG_ 820 R_R_AJAR 5;
BA_ "GenSigSNA" SG_ 820 R_R_AJAR "0h";
BA_ "GenSigTimeout_IC" SG_ 820 R_R_AJAR 10500;
BA_ "GenSigTimeout_RF_HUB" SG_ 820 R_R_AJAR 10500;
BA_ "FlexKomComment" SG_ 820 SHIP_STAT "Shipping status";
BA_ "FlexKomIsMotorola" SG_ 820 SHIP_STAT 1;
BA_ "FlexKomSID" SG_ 820 SHIP_STAT 869;
BA_ "FlexKomSigLaenge" SG_ 820 SHIP_STAT 2;
BA_ "FlexKomSigName" SG_ 820 SHIP_STAT "SHIP_STAT";
BA_ "FlexKomSigStartPos" SG_ 820 SHIP_STAT 29;
BA_ "FlexKomSigStartValue" SG_ 820 SHIP_STAT "03h";
BA_ "GenSigCycleTime" SG_ 820 SHIP_STAT 1000;
BA_ "GenSigSendType" SG_ 820 SHIP_STAT 5;
BA_ "GenSigSNA" SG_ 820 SHIP_STAT "3h";
BA_ "GenSigStartValue" SG_ 820 SHIP_STAT 3;
BA_ "GenSigTimeout_IC" SG_ 820 SHIP_STAT 10500;
BA_ "GenSigTimeout_ORC" SG_ 820 SHIP_STAT 3500;
BA_ "GenSigTimeout_RF_HUB" SG_ 820 SHIP_STAT 10500;
BA_ "FlexKomComment" SG_ 820 TLG_AJAR "Door ajar";
BA_ "FlexKomIsMotorola" SG_ 820 TLG_AJAR 1;
BA_ "FlexKomSID" SG_ 820 TLG_AJAR 797;
BA_ "FlexKomSigLaenge" SG_ 820 TLG_AJAR 6;
BA_ "FlexKomSigName" SG_ 820 TLG_AJAR "DR_AJAR";
BA_ "FlexKomSigStartPos" SG_ 820 TLG_AJAR 22;
BA_ "FlexKomSigStartValue" SG_ 820 TLG_AJAR "00h";
BA_ "GenSigCycleTime" SG_ 820 TLG_AJAR 1000;
BA_ "GenSigSendType" SG_ 820 TLG_AJAR 5;
BA_ "GenSigSNA" SG_ 820 TLG_AJAR "0h";
BA_ "GenSigTimeout_IC" SG_ 820 TLG_AJAR 10500;
BA_ "GenSigTimeout_RF_HUB" SG_ 820 TLG_AJAR 10500;
BA_ "FlexKomComment" SG_ 820 TurnInd_LT_ON "Turn indication status";
BA_ "FlexKomIsMotorola" SG_ 820 TurnInd_LT_ON 1;
BA_ "FlexKomSID" SG_ 820 TurnInd_LT_ON 759;
BA_ "FlexKomSigLaenge" SG_ 820 TurnInd_LT_ON 2;
BA_ "FlexKomSigName" SG_ 820 TurnInd_LT_ON "TurnInd_STAT";
BA_ "FlexKomSigStartPos" SG_ 820 TurnInd_LT_ON 31;
BA_ "FlexKomSigStartValue" SG_ 820 TurnInd_LT_ON "00h";
BA_ "GenSigCycleTime" SG_ 820 TurnInd_LT_ON 1000;
BA_ "GenSigSendType" SG_ 820 TurnInd_LT_ON 5;
BA_ "GenSigSNA" SG_ 820 TurnInd_LT_ON "0h";
BA_ "GenSigTimeout_IC" SG_ 820 TurnInd_LT_ON 10500;
BA_ "GenSigTimeout_PTS" SG_ 820 TurnInd_LT_ON 10500;
BA_ "FlexKomComment" SG_ 820 TurnInd_RT_ON "Turn indication status";
BA_ "FlexKomIsMotorola" SG_ 820 TurnInd_RT_ON 1;
BA_ "FlexKomSID" SG_ 820 TurnInd_RT_ON 759;
BA_ "FlexKomSigLaenge" SG_ 820 TurnInd_RT_ON 2;
BA_ "FlexKomSigName" SG_ 820 TurnInd_RT_ON "TurnInd_STAT";
BA_ "FlexKomSigStartPos" SG_ 820 TurnInd_RT_ON 31;
BA_ "FlexKomSigStartValue" SG_ 820 TurnInd_RT_ON "00h";
BA_ "GenSigCycleTime" SG_ 820 TurnInd_RT_ON 1000;
BA_ "GenSigSendType" SG_ 820 TurnInd_RT_ON 5;
BA_ "GenSigSNA" SG_ 820 TurnInd_RT_ON "0h";
BA_ "GenSigTimeout_IC" SG_ 820 TurnInd_RT_ON 10500;
BA_ "GenSigTimeout_PTS" SG_ 820 TurnInd_RT_ON 10500;
BA_ "FlexKomComment" SG_ 820 WASH_FLUID_LO "Low washer fluid warning (1=Fluid is low)";
BA_ "FlexKomIsMotorola" SG_ 820 WASH_FLUID_LO 1;
BA_ "FlexKomSID" SG_ 820 WASH_FLUID_LO 965;
BA_ "FlexKomSigLaenge" SG_ 820 WASH_FLUID_LO 1;
BA_ "FlexKomSigName" SG_ 820 WASH_FLUID_LO "WASH_FLUID_LO";
BA_ "FlexKomSigStartPos" SG_ 820 WASH_FLUID_LO 63;
BA_ "FlexKomSigStartValue" SG_ 820 WASH_FLUID_LO "00h";
BA_ "GenSigCycleTime" SG_ 820 WASH_FLUID_LO 1000;
BA_ "GenSigSendType" SG_ 820 WASH_FLUID_LO 5;
BA_ "GenSigSNA" SG_ 820 WASH_FLUID_LO "0h";
BA_ "GenSigTimeout_ETM" SG_ 820 WASH_FLUID_LO 10500;
BA_ "GenSigTimeout_IC" SG_ 820 WASH_FLUID_LO 10500;
BA_ "FlexKomComment" SG_ 274 CmdIgnStat "Vehicle start packet";
BA_ "FlexKomIsMotorola" SG_ 274 CmdIgnStat 1;
BA_ "FlexKomSID" SG_ 274 CmdIgnStat 880;
BA_ "FlexKomSigLaenge" SG_ 274 CmdIgnStat 16;
BA_ "FlexKomSigName" SG_ 274 CmdIgnStat "VehStart_PKT";
BA_ "FlexKomSigStartPos" SG_ 274 CmdIgnStat 7;
BA_ "FlexKomSigStartValue" SG_ 274 CmdIgnStat "0000h";
BA_ "GenSigCycleTime" SG_ 274 CmdIgnStat 20;
BA_ "GenSigSNA" SG_ 274 CmdIgnStat "7h";
BA_ "GenSigTimeout_EPS" SG_ 274 CmdIgnStat 210;
BA_ "GenSigTimeout_ESL" SG_ 274 CmdIgnStat 110;
BA_ "GenSigTimeout_IC" SG_ 274 CmdIgnStat 210;
BA_ "GenSigTimeout_ORC" SG_ 274 CmdIgnStat 70;
BA_ "GenSigTimeout_PTS" SG_ 274 CmdIgnStat 210;
BA_ "GenSigTimeout_SCCM" SG_ 274 CmdIgnStat 210;
BA_ "RID" SG_ 274 CmdIgnStat "9600";
BA_ "FlexKomComment" SG_ 274 KeyInIgn "Vehicle start packet";
BA_ "FlexKomIsMotorola" SG_ 274 KeyInIgn 1;
BA_ "FlexKomSID" SG_ 274 KeyInIgn 880;
BA_ "FlexKomSigLaenge" SG_ 274 KeyInIgn 16;
BA_ "FlexKomSigName" SG_ 274 KeyInIgn "VehStart_PKT";
BA_ "FlexKomSigStartPos" SG_ 274 KeyInIgn 7;
BA_ "FlexKomSigStartValue" SG_ 274 KeyInIgn "0000h";
BA_ "GenSigCycleTime" SG_ 274 KeyInIgn 20;
BA_ "GenSigSNA" SG_ 274 KeyInIgn "3h";
BA_ "GenSigTimeout_ESL" SG_ 274 KeyInIgn 110;
BA_ "GenSigTimeout_IC" SG_ 274 KeyInIgn 210;
BA_ "GenSigTimeout_ORC" SG_ 274 KeyInIgn 70;
BA_ "RID" SG_ 274 KeyInIgn "9745";
BA_ "FlexKomComment" SG_ 274 RemStActv "Vehicle start packet";
BA_ "FlexKomIsMotorola" SG_ 274 RemStActv 1;
BA_ "FlexKomSID" SG_ 274 RemStActv 880;
BA_ "FlexKomSigLaenge" SG_ 274 RemStActv 16;
BA_ "FlexKomSigName" SG_ 274 RemStActv "VehStart_PKT";
BA_ "FlexKomSigStartPos" SG_ 274 RemStActv 7;
BA_ "FlexKomSigStartValue" SG_ 274 RemStActv "0000h";
BA_ "GenSigCycleTime" SG_ 274 RemStActv 20;
BA_ "GenSigSNA" SG_ 274 RemStActv "0h";
BA_ "GenSigTimeout_IC" SG_ 274 RemStActv 210;
BA_ "GenSigTimeout_ORC" SG_ 274 RemStActv 70;
BA_ "RID" SG_ 274 RemStActv "9746";
BA_ "FlexKomComment" SG_ 274 StTyp "Vehicle start packet";
BA_ "FlexKomIsMotorola" SG_ 274 StTyp 1;
BA_ "FlexKomSID" SG_ 274 StTyp 880;
BA_ "FlexKomSigLaenge" SG_ 274 StTyp 16;
BA_ "FlexKomSigName" SG_ 274 StTyp "VehStart_PKT";
BA_ "FlexKomSigStartPos" SG_ 274 StTyp 7;
BA_ "FlexKomSigStartValue" SG_ 274 StTyp "0000h";
BA_ "GenSigCycleTime" SG_ 274 StTyp 20;
BA_ "GenSigSNA" SG_ 274 StTyp "7h";
BA_ "GenSigTimeout_IC" SG_ 274 StTyp 210;
BA_ "GenSigTimeout_ORC" SG_ 274 StTyp 70;
BA_ "FlexKomComment" SG_ 274 StartRelayBCMFault "CBC starter relay fault detected";
BA_ "FlexKomIsMotorola" SG_ 274 StartRelayBCMFault 1;
BA_ "FlexKomSID" SG_ 274 StartRelayBCMFault 1573;
BA_ "FlexKomSigLaenge" SG_ 274 StartRelayBCMFault 1;
BA_ "FlexKomSigName" SG_ 274 StartRelayBCMFault "StartRelayBCMFault";
BA_ "FlexKomSigStartPos" SG_ 274 StartRelayBCMFault 14;
BA_ "FlexKomSigStartValue" SG_ 274 StartRelayBCMFault "00h";
BA_ "GenSigCycleTime" SG_ 274 StartRelayBCMFault 20;
BA_ "GenSigSNA" SG_ 274 StartRelayBCMFault "0h";
BA_ "GenSigTimeout_ORC" SG_ 274 StartRelayBCMFault 70;
BA_ "FlexKomComment" SG_ 274 StartRelayBCMSts "CBC starter relay status; [1] = ON";
BA_ "FlexKomIsMotorola" SG_ 274 StartRelayBCMSts 1;
BA_ "FlexKomSID" SG_ 274 StartRelayBCMSts 1526;
BA_ "FlexKomSigLaenge" SG_ 274 StartRelayBCMSts 1;
BA_ "FlexKomSigName" SG_ 274 StartRelayBCMSts "StartRelayBCMSts";
BA_ "FlexKomSigStartPos" SG_ 274 StartRelayBCMSts 13;
BA_ "FlexKomSigStartValue" SG_ 274 StartRelayBCMSts "00h";
BA_ "GenSigCycleTime" SG_ 274 StartRelayBCMSts 20;
BA_ "GenSigSNA" SG_ 274 StartRelayBCMSts "0h";
BA_ "FlexKomComment" SG_ 274 TeenKeyPrsnt "Vehicle start packet";
BA_ "FlexKomIsMotorola" SG_ 274 TeenKeyPrsnt 1;
BA_ "FlexKomSID" SG_ 274 TeenKeyPrsnt 880;
BA_ "FlexKomSigLaenge" SG_ 274 TeenKeyPrsnt 16;
BA_ "FlexKomSigName" SG_ 274 TeenKeyPrsnt "VehStart_PKT";
BA_ "FlexKomSigStartPos" SG_ 274 TeenKeyPrsnt 7;
BA_ "FlexKomSigStartValue" SG_ 274 TeenKeyPrsnt "0000h";
BA_ "GenSigCycleTime" SG_ 274 TeenKeyPrsnt 20;
BA_ "GenSigSNA" SG_ 274 TeenKeyPrsnt "0h";
BA_ "GenSigTimeout_ETM" SG_ 274 TeenKeyPrsnt 210;
BA_ "GenSigTimeout_IC" SG_ 274 TeenKeyPrsnt 210;
BA_ "FlexKomComment" SG_ 512 AMB_TEMP_AVG "Averaged ambient temperature";
BA_ "FlexKomIsMotorola" SG_ 512 AMB_TEMP_AVG 1;
BA_ "FlexKomSID" SG_ 512 AMB_TEMP_AVG 840;
BA_ "FlexKomSigLaenge" SG_ 512 AMB_TEMP_AVG 16;
BA_ "FlexKomSigName" SG_ 512 AMB_TEMP_AVG "AMB_TEMP_AVG";
BA_ "FlexKomSigStartPos" SG_ 512 AMB_TEMP_AVG 15;
BA_ "FlexKomSigStartValue" SG_ 512 AMB_TEMP_AVG "FFFFh";
BA_ "GenSigCycleTime" SG_ 512 AMB_TEMP_AVG 100;
BA_ "GenSigSNA" SG_ 512 AMB_TEMP_AVG "FFFFh";
BA_ "GenSigStartValue" SG_ 512 AMB_TEMP_AVG 65535;
BA_ "GenSigTimeout_IC" SG_ 512 AMB_TEMP_AVG 1050;
BA_ "GenSigTimeout_ORC" SG_ 512 AMB_TEMP_AVG 350;
BA_ "GenSigTimeout_RF_HUB" SG_ 512 AMB_TEMP_AVG 1050;
BA_ "RID" SG_ 512 AMB_TEMP_AVG "9768";
BA_ "FlexKomComment" SG_ 512 AMB_TEMP_VOLT "Ambient Temp Sensor A/D Voltage";
BA_ "FlexKomIsMotorola" SG_ 512 AMB_TEMP_VOLT 1;
BA_ "FlexKomSID" SG_ 512 AMB_TEMP_VOLT 1201;
BA_ "FlexKomSigLaenge" SG_ 512 AMB_TEMP_VOLT 8;
BA_ "FlexKomSigName" SG_ 512 AMB_TEMP_VOLT "AMB_TEMP_VOLT";
BA_ "FlexKomSigStartPos" SG_ 512 AMB_TEMP_VOLT 31;
BA_ "FlexKomSigStartValue" SG_ 512 AMB_TEMP_VOLT "FFh";
BA_ "GenSigCycleTime" SG_ 512 AMB_TEMP_VOLT 100;
BA_ "GenSigSNA" SG_ 512 AMB_TEMP_VOLT "FFh";
BA_ "GenSigStartValue" SG_ 512 AMB_TEMP_VOLT 255;
BA_ "GenSigTimeout_ORC" SG_ 512 AMB_TEMP_VOLT 350;
BA_ "RID" SG_ 512 AMB_TEMP_VOLT "1805";
BA_ "FlexKomComment" SG_ 512 AirTemp_Outsd "Outside air temperature";
BA_ "FlexKomIsMotorola" SG_ 512 AirTemp_Outsd 1;
BA_ "FlexKomSID" SG_ 512 AirTemp_Outsd 773;
BA_ "FlexKomSigLaenge" SG_ 512 AirTemp_Outsd 8;
BA_ "FlexKomSigName" SG_ 512 AirTemp_Outsd "AirTemp_Outsd";
BA_ "FlexKomSigStartPos" SG_ 512 AirTemp_Outsd 7;
BA_ "FlexKomSigStartValue" SG_ 512 AirTemp_Outsd "FFh";
BA_ "GenSigCycleTime" SG_ 512 AirTemp_Outsd 100;
BA_ "GenSigSNA" SG_ 512 AirTemp_Outsd "FFh";
BA_ "GenSigStartValue" SG_ 512 AirTemp_Outsd 255;
BA_ "GenSigTimeout_IC" SG_ 512 AirTemp_Outsd 1050;
BA_ "GenSigTimeout_ORC" SG_ 512 AirTemp_Outsd 350;
BA_ "GenSigTimeout_RF_HUB" SG_ 512 AirTemp_Outsd 1050;
BA_ "RID" SG_ 512 AirTemp_Outsd "9767";
BA_ "FlexKomComment" SG_ 512 BATT_VOLT "System voltage";
BA_ "FlexKomIsMotorola" SG_ 512 BATT_VOLT 1;
BA_ "FlexKomSID" SG_ 512 BATT_VOLT 839;
BA_ "FlexKomSigLaenge" SG_ 512 BATT_VOLT 8;
BA_ "FlexKomSigName" SG_ 512 BATT_VOLT "BATT_VOLT";
BA_ "FlexKomSigStartPos" SG_ 512 BATT_VOLT 55;
BA_ "FlexKomSigStartValue" SG_ 512 BATT_VOLT "FFh";
BA_ "GenSigCycleTime" SG_ 512 BATT_VOLT 100;
BA_ "GenSigSNA" SG_ 512 BATT_VOLT "FFh";
BA_ "GenSigStartValue" SG_ 512 BATT_VOLT 255;
BA_ "GenSigTimeout_EPS" SG_ 512 BATT_VOLT 1050;
BA_ "GenSigTimeout_RHSC2" SG_ 512 BATT_VOLT 1050;
BA_ "GenSigTimeout_IC" SG_ 512 BATT_VOLT 1050;
BA_ "GenSigTimeout_ORC" SG_ 512 BATT_VOLT 350;
BA_ "GenSigTimeout_RF_HUB" SG_ 512 BATT_VOLT 1050;
BA_ "GenSigTimeout_SCCM" SG_ 512 BATT_VOLT 1050;
BA_ "RID" SG_ 512 BATT_VOLT "9601";
BA_ "FlexKomComment" SG_ 512 FUEL_VOLT "Fuel level A/D Voltage (Single tank OR Primary on ";
BA_ "FlexKomIsMotorola" SG_ 512 FUEL_VOLT 1;
BA_ "FlexKomSID" SG_ 512 FUEL_VOLT 881;
BA_ "FlexKomSigLaenge" SG_ 512 FUEL_VOLT 8;
BA_ "FlexKomSigName" SG_ 512 FUEL_VOLT "FUEL_VOLT";
BA_ "FlexKomSigStartPos" SG_ 512 FUEL_VOLT 39;
BA_ "FlexKomSigStartValue" SG_ 512 FUEL_VOLT "FFh";
BA_ "GenSigCycleTime" SG_ 512 FUEL_VOLT 100;
BA_ "GenSigSNA" SG_ 512 FUEL_VOLT "FFh";
BA_ "GenSigStartValue" SG_ 512 FUEL_VOLT 255;
BA_ "GenSigTimeout_IC" SG_ 512 FUEL_VOLT 1050;
BA_ "FlexKomComment" SG_ 804 ACC_DLY_ACT "Accessory Delay Active";
BA_ "FlexKomIsMotorola" SG_ 804 ACC_DLY_ACT 1;
BA_ "FlexKomSID" SG_ 804 ACC_DLY_ACT 841;
BA_ "FlexKomSigLaenge" SG_ 804 ACC_DLY_ACT 1;
BA_ "FlexKomSigName" SG_ 804 ACC_DLY_ACT "ACC_DLY_ACT";
BA_ "FlexKomSigStartPos" SG_ 804 ACC_DLY_ACT 26;
BA_ "FlexKomSigStartValue" SG_ 804 ACC_DLY_ACT "00h";
BA_ "GenSigCycleTime" SG_ 804 ACC_DLY_ACT 1000;
BA_ "GenSigSendType" SG_ 804 ACC_DLY_ACT 5;
BA_ "GenSigSNA" SG_ 804 ACC_DLY_ACT "0h";
BA_ "GenSigTimeout_IC" SG_ 804 ACC_DLY_ACT 10500;
BA_ "GenSigTimeout_SCCM" SG_ 804 ACC_DLY_ACT 10500;
BA_ "FlexKomComment" SG_ 804 ExteriorRearReleaseSwitchSts "Exterior rear release switch status";
BA_ "FlexKomIsMotorola" SG_ 804 ExteriorRearReleaseSwitchSts 1;
BA_ "FlexKomSID" SG_ 804 ExteriorRearReleaseSwitchSts 1846;
BA_ "FlexKomSigLaenge" SG_ 804 ExteriorRearReleaseSwitchSts 1;
BA_ "FlexKomSigName" SG_ 804 ExteriorRearReleaseSwitchSts "ExteriorRearReleaseSwitchSts";
BA_ "FlexKomSigStartPos" SG_ 804 ExteriorRearReleaseSwitchSts 21;
BA_ "FlexKomSigStartValue" SG_ 804 ExteriorRearReleaseSwitchSts "00h";
BA_ "GenSigCycleTime" SG_ 804 ExteriorRearReleaseSwitchSts 1000;
BA_ "GenSigSendType" SG_ 804 ExteriorRearReleaseSwitchSts 5;
BA_ "GenSigSNA" SG_ 804 ExteriorRearReleaseSwitchSts "0h";
BA_ "GenSigTimeout_RF_HUB" SG_ 804 ExteriorRearReleaseSwitchSts 10500;
BA_ "FlexKomComment" SG_ 804 HdAjar "Hood latch ajar, left or single (1=ajar)";
BA_ "FlexKomIsMotorola" SG_ 804 HdAjar 1;
BA_ "FlexKomSID" SG_ 804 HdAjar 1818;
BA_ "FlexKomSigLaenge" SG_ 804 HdAjar 1;
BA_ "FlexKomSigName" SG_ 804 HdAjar "HdAjar";
BA_ "FlexKomSigStartPos" SG_ 804 HdAjar 10;
BA_ "FlexKomSigStartValue" SG_ 804 HdAjar "01h";
BA_ "GenSigCycleTime" SG_ 804 HdAjar 1000;
BA_ "GenSigSendType" SG_ 804 HdAjar 5;
BA_ "GenSigSNA" SG_ 804 HdAjar "1h";
BA_ "GenSigStartValue" SG_ 804 HdAjar 1;
BA_ "GenSigTimeout_IC" SG_ 804 HdAjar 10500;
BA_ "FlexKomComment" SG_ 804 RemSt_Inhibit "Remote start inhibit";
BA_ "FlexKomIsMotorola" SG_ 804 RemSt_Inhibit 1;
BA_ "FlexKomSID" SG_ 804 RemSt_Inhibit 1047;
BA_ "FlexKomSigLaenge" SG_ 804 RemSt_Inhibit 8;
BA_ "FlexKomSigName" SG_ 804 RemSt_Inhibit "RemSt_Inhibit";
BA_ "FlexKomSigStartPos" SG_ 804 RemSt_Inhibit 39;
BA_ "FlexKomSigStartValue" SG_ 804 RemSt_Inhibit "00h";
BA_ "GenSigCycleTime" SG_ 804 RemSt_Inhibit 1000;
BA_ "GenSigSendType" SG_ 804 RemSt_Inhibit 5;
BA_ "GenSigSNA" SG_ 804 RemSt_Inhibit "FFh";
BA_ "GenSigTimeout_ETM" SG_ 804 RemSt_Inhibit 10500;
BA_ "GenSigTimeout_IC" SG_ 804 RemSt_Inhibit 10500;
BA_ "FlexKomComment" SG_ 804 TurnLmp_FL_Flt "Turn indication lamp front fault";
BA_ "FlexKomIsMotorola" SG_ 804 TurnLmp_FL_Flt 1;
BA_ "FlexKomSID" SG_ 804 TurnLmp_FL_Flt 973;
BA_ "FlexKomSigLaenge" SG_ 804 TurnLmp_FL_Flt 2;
BA_ "FlexKomSigName" SG_ 804 TurnLmp_FL_Flt "TurnLmp_F_Flt";
BA_ "FlexKomSigStartPos" SG_ 804 TurnLmp_FL_Flt 14;
BA_ "FlexKomSigStartValue" SG_ 804 TurnLmp_FL_Flt "00h";
BA_ "GenSigCycleTime" SG_ 804 TurnLmp_FL_Flt 1000;
BA_ "GenSigSendType" SG_ 804 TurnLmp_FL_Flt 5;
BA_ "GenSigSNA" SG_ 804 TurnLmp_FL_Flt "0h";
BA_ "GenSigTimeout_IC" SG_ 804 TurnLmp_FL_Flt 10500;
BA_ "FlexKomComment" SG_ 804 TurnLmp_FR_Flt "Turn indication lamp front fault";
BA_ "FlexKomIsMotorola" SG_ 804 TurnLmp_FR_Flt 1;
BA_ "FlexKomSID" SG_ 804 TurnLmp_FR_Flt 973;
BA_ "FlexKomSigLaenge" SG_ 804 TurnLmp_FR_Flt 2;
BA_ "FlexKomSigName" SG_ 804 TurnLmp_FR_Flt "TurnLmp_F_Flt";
BA_ "FlexKomSigStartPos" SG_ 804 TurnLmp_FR_Flt 14;
BA_ "FlexKomSigStartValue" SG_ 804 TurnLmp_FR_Flt "00h";
BA_ "GenSigCycleTime" SG_ 804 TurnLmp_FR_Flt 1000;
BA_ "GenSigSendType" SG_ 804 TurnLmp_FR_Flt 5;
BA_ "GenSigSNA" SG_ 804 TurnLmp_FR_Flt "0h";
BA_ "GenSigTimeout_IC" SG_ 804 TurnLmp_FR_Flt 10500;
BA_ "FlexKomComment" SG_ 804 TurnLmp_RL_Flt "Turn indication lamp rear fault";
BA_ "FlexKomIsMotorola" SG_ 804 TurnLmp_RL_Flt 1;
BA_ "FlexKomSID" SG_ 804 TurnLmp_RL_Flt 1033;
BA_ "FlexKomSigLaenge" SG_ 804 TurnLmp_RL_Flt 2;
BA_ "FlexKomSigName" SG_ 804 TurnLmp_RL_Flt "TurnLmp_R_Flt";
BA_ "FlexKomSigStartPos" SG_ 804 TurnLmp_RL_Flt 25;
BA_ "FlexKomSigStartValue" SG_ 804 TurnLmp_RL_Flt "00h";
BA_ "GenSigCycleTime" SG_ 804 TurnLmp_RL_Flt 1000;
BA_ "GenSigSendType" SG_ 804 TurnLmp_RL_Flt 5;
BA_ "GenSigSNA" SG_ 804 TurnLmp_RL_Flt "0h";
BA_ "GenSigTimeout_IC" SG_ 804 TurnLmp_RL_Flt 10500;
BA_ "FlexKomComment" SG_ 804 TurnLmp_RR_Flt "Turn indication lamp rear fault";
BA_ "FlexKomIsMotorola" SG_ 804 TurnLmp_RR_Flt 1;
BA_ "FlexKomSID" SG_ 804 TurnLmp_RR_Flt 1033;
BA_ "FlexKomSigLaenge" SG_ 804 TurnLmp_RR_Flt 2;
BA_ "FlexKomSigName" SG_ 804 TurnLmp_RR_Flt "TurnLmp_R_Flt";
BA_ "FlexKomSigStartPos" SG_ 804 TurnLmp_RR_Flt 25;
BA_ "FlexKomSigStartValue" SG_ 804 TurnLmp_RR_Flt "00h";
BA_ "GenSigCycleTime" SG_ 804 TurnLmp_RR_Flt 1000;
BA_ "GenSigSendType" SG_ 804 TurnLmp_RR_Flt 5;
BA_ "GenSigSNA" SG_ 804 TurnLmp_RR_Flt "0h";
BA_ "GenSigTimeout_IC" SG_ 804 TurnLmp_RR_Flt 10500;
BA_ "FlexKomComment" SG_ 804 WPR_SYS_AUTO "Wiper System Status";
BA_ "FlexKomIsMotorola" SG_ 804 WPR_SYS_AUTO 1;
BA_ "FlexKomSID" SG_ 804 WPR_SYS_AUTO 1048;
BA_ "FlexKomSigLaenge" SG_ 804 WPR_SYS_AUTO 8;
BA_ "FlexKomSigName" SG_ 804 WPR_SYS_AUTO "WPR_SYS_STAT";
BA_ "FlexKomSigStartPos" SG_ 804 WPR_SYS_AUTO 47;
BA_ "FlexKomSigStartValue" SG_ 804 WPR_SYS_AUTO "01h";
BA_ "GenSigCycleTime" SG_ 804 WPR_SYS_AUTO 1000;
BA_ "GenSigSNA" SG_ 804 WPR_SYS_AUTO "0h";
BA_ "FlexKomComment" SG_ 804 WPR_SYS_FLT "Wiper System Status";
BA_ "FlexKomIsMotorola" SG_ 804 WPR_SYS_FLT 1;
BA_ "FlexKomSID" SG_ 804 WPR_SYS_FLT 1048;
BA_ "FlexKomSigLaenge" SG_ 804 WPR_SYS_FLT 8;
BA_ "FlexKomSigName" SG_ 804 WPR_SYS_FLT "WPR_SYS_STAT";
BA_ "FlexKomSigStartPos" SG_ 804 WPR_SYS_FLT 47;
BA_ "FlexKomSigStartValue" SG_ 804 WPR_SYS_FLT "01h";
BA_ "GenSigCycleTime" SG_ 804 WPR_SYS_FLT 1000;
BA_ "GenSigSNA" SG_ 804 WPR_SYS_FLT "0h";
BA_ "FlexKomComment" SG_ 804 WPR_SYS_HIGH "Wiper System Status";
BA_ "FlexKomIsMotorola" SG_ 804 WPR_SYS_HIGH 1;
BA_ "FlexKomSID" SG_ 804 WPR_SYS_HIGH 1048;
BA_ "FlexKomSigLaenge" SG_ 804 WPR_SYS_HIGH 8;
BA_ "FlexKomSigName" SG_ 804 WPR_SYS_HIGH "WPR_SYS_STAT";
BA_ "FlexKomSigStartPos" SG_ 804 WPR_SYS_HIGH 47;
BA_ "FlexKomSigStartValue" SG_ 804 WPR_SYS_HIGH "01h";
BA_ "GenSigCycleTime" SG_ 804 WPR_SYS_HIGH 1000;
BA_ "GenSigSNA" SG_ 804 WPR_SYS_HIGH "0h";
BA_ "FlexKomComment" SG_ 804 WPR_SYS_INT "Wiper System Status";
BA_ "FlexKomIsMotorola" SG_ 804 WPR_SYS_INT 1;
BA_ "FlexKomSID" SG_ 804 WPR_SYS_INT 1048;
BA_ "FlexKomSigLaenge" SG_ 804 WPR_SYS_INT 8;
BA_ "FlexKomSigName" SG_ 804 WPR_SYS_INT "WPR_SYS_STAT";
BA_ "FlexKomSigStartPos" SG_ 804 WPR_SYS_INT 47;
BA_ "FlexKomSigStartValue" SG_ 804 WPR_SYS_INT "01h";
BA_ "GenSigCycleTime" SG_ 804 WPR_SYS_INT 1000;
BA_ "GenSigSNA" SG_ 804 WPR_SYS_INT "0h";
BA_ "FlexKomComment" SG_ 804 WPR_SYS_LOW "Wiper System Status";
BA_ "FlexKomIsMotorola" SG_ 804 WPR_SYS_LOW 1;
BA_ "FlexKomSID" SG_ 804 WPR_SYS_LOW 1048;
BA_ "FlexKomSigLaenge" SG_ 804 WPR_SYS_LOW 8;
BA_ "FlexKomSigName" SG_ 804 WPR_SYS_LOW "WPR_SYS_STAT";
BA_ "FlexKomSigStartPos" SG_ 804 WPR_SYS_LOW 47;
BA_ "FlexKomSigStartValue" SG_ 804 WPR_SYS_LOW "01h";
BA_ "GenSigCycleTime" SG_ 804 WPR_SYS_LOW 1000;
BA_ "GenSigSNA" SG_ 804 WPR_SYS_LOW "0h";
BA_ "FlexKomComment" SG_ 804 WPR_SYS_MIST "Wiper System Status";
BA_ "FlexKomIsMotorola" SG_ 804 WPR_SYS_MIST 1;
BA_ "FlexKomSID" SG_ 804 WPR_SYS_MIST 1048;
BA_ "FlexKomSigLaenge" SG_ 804 WPR_SYS_MIST 8;
BA_ "FlexKomSigName" SG_ 804 WPR_SYS_MIST "WPR_SYS_STAT";
BA_ "FlexKomSigStartPos" SG_ 804 WPR_SYS_MIST 47;
BA_ "FlexKomSigStartValue" SG_ 804 WPR_SYS_MIST "01h";
BA_ "GenSigCycleTime" SG_ 804 WPR_SYS_MIST 1000;
BA_ "GenSigSNA" SG_ 804 WPR_SYS_MIST "0h";
BA_ "FlexKomComment" SG_ 804 WPR_SYS_OFF "Wiper System Status";
BA_ "FlexKomIsMotorola" SG_ 804 WPR_SYS_OFF 1;
BA_ "FlexKomSID" SG_ 804 WPR_SYS_OFF 1048;
BA_ "FlexKomSigLaenge" SG_ 804 WPR_SYS_OFF 8;
BA_ "FlexKomSigName" SG_ 804 WPR_SYS_OFF "WPR_SYS_STAT";
BA_ "FlexKomSigStartPos" SG_ 804 WPR_SYS_OFF 47;
BA_ "FlexKomSigStartValue" SG_ 804 WPR_SYS_OFF "01h";
BA_ "GenSigCycleTime" SG_ 804 WPR_SYS_OFF 1000;
BA_ "GenSigSNA" SG_ 804 WPR_SYS_OFF "1h";
BA_ "GenSigStartValue" SG_ 804 WPR_SYS_OFF 1;
BA_ "FlexKomComment" SG_ 804 WPR_SYS_WASH "Wiper System Status";
BA_ "FlexKomIsMotorola" SG_ 804 WPR_SYS_WASH 1;
BA_ "FlexKomSID" SG_ 804 WPR_SYS_WASH 1048;
BA_ "FlexKomSigLaenge" SG_ 804 WPR_SYS_WASH 8;
BA_ "FlexKomSigName" SG_ 804 WPR_SYS_WASH "WPR_SYS_STAT";
BA_ "FlexKomSigStartPos" SG_ 804 WPR_SYS_WASH 47;
BA_ "FlexKomSigStartValue" SG_ 804 WPR_SYS_WASH "01h";
BA_ "GenSigCycleTime" SG_ 804 WPR_SYS_WASH 1000;
BA_ "GenSigSNA" SG_ 804 WPR_SYS_WASH "0h";
BA_ "FlexKomComment" SG_ 520 BonnetAjarRawValSts "CBC_PT6 message packet";
BA_ "FlexKomIsMotorola" SG_ 520 BonnetAjarRawValSts 1;
BA_ "FlexKomSID" SG_ 520 BonnetAjarRawValSts 1943;
BA_ "FlexKomSigLaenge" SG_ 520 BonnetAjarRawValSts 64;
BA_ "FlexKomSigName" SG_ 520 BonnetAjarRawValSts "CBC_PT6_Pkt";
BA_ "FlexKomSigStartPos" SG_ 520 BonnetAjarRawValSts 7;
BA_ "FlexKomSigStartValue" SG_ 520 BonnetAjarRawValSts "3FFF0C0000000000h";
BA_ "GenSigCycleTime" SG_ 520 BonnetAjarRawValSts 20;
BA_ "GenSigSNA" SG_ 520 BonnetAjarRawValSts "Fh";
BA_ "GenSigTimeout_ORC" SG_ 520 BonnetAjarRawValSts 70;
BA_ "FlexKomComment" SG_ 520 BrkPdlStat_CBC "CBC_PT6 message packet";
BA_ "FlexKomIsMotorola" SG_ 520 BrkPdlStat_CBC 1;
BA_ "FlexKomSID" SG_ 520 BrkPdlStat_CBC 1943;
BA_ "FlexKomSigLaenge" SG_ 520 BrkPdlStat_CBC 64;
BA_ "FlexKomSigName" SG_ 520 BrkPdlStat_CBC "CBC_PT6_Pkt";
BA_ "FlexKomSigStartPos" SG_ 520 BrkPdlStat_CBC 7;
BA_ "FlexKomSigStartValue" SG_ 520 BrkPdlStat_CBC "3FFF0C0000000000h";
BA_ "GenSigCycleTime" SG_ 520 BrkPdlStat_CBC 20;
BA_ "GenSigSNA" SG_ 520 BrkPdlStat_CBC "3h";
BA_ "GenSigStartValue" SG_ 520 BrkPdlStat_CBC 3;
BA_ "GenSigTimeout_RF_HUB" SG_ 520 BrkPdlStat_CBC 210;
BA_ "FlexKomComment" SG_ 520 DriverDoor2AjarRawValSts "CBC_PT6 message packet";
BA_ "FlexKomIsMotorola" SG_ 520 DriverDoor2AjarRawValSts 1;
BA_ "FlexKomSID" SG_ 520 DriverDoor2AjarRawValSts 1943;
BA_ "FlexKomSigLaenge" SG_ 520 DriverDoor2AjarRawValSts 64;
BA_ "FlexKomSigName" SG_ 520 DriverDoor2AjarRawValSts "CBC_PT6_Pkt";
BA_ "FlexKomSigStartPos" SG_ 520 DriverDoor2AjarRawValSts 7;
BA_ "FlexKomSigStartValue" SG_ 520 DriverDoor2AjarRawValSts "3FFF0C0000000000h";
BA_ "GenSigCycleTime" SG_ 520 DriverDoor2AjarRawValSts 20;
BA_ "GenSigSNA" SG_ 520 DriverDoor2AjarRawValSts "Fh";
BA_ "FlexKomComment" SG_ 520 DriverDoor2AjarXtionSts "CBC_PT6 message packet";
BA_ "FlexKomIsMotorola" SG_ 520 DriverDoor2AjarXtionSts 1;
BA_ "FlexKomSID" SG_ 520 DriverDoor2AjarXtionSts 1943;
BA_ "FlexKomSigLaenge" SG_ 520 DriverDoor2AjarXtionSts 64;
BA_ "FlexKomSigName" SG_ 520 DriverDoor2AjarXtionSts "CBC_PT6_Pkt";
BA_ "FlexKomSigStartPos" SG_ 520 DriverDoor2AjarXtionSts 7;
BA_ "FlexKomSigStartValue" SG_ 520 DriverDoor2AjarXtionSts "3FFF0C0000000000h";
BA_ "GenSigCycleTime" SG_ 520 DriverDoor2AjarXtionSts 20;
BA_ "GenSigSNA" SG_ 520 DriverDoor2AjarXtionSts "3h";
BA_ "GenSigStartValue" SG_ 520 DriverDoor2AjarXtionSts 3;
BA_ "FlexKomComment" SG_ 520 DriverDoorAjarRawValSts "CBC_PT6 message packet";
BA_ "FlexKomIsMotorola" SG_ 520 DriverDoorAjarRawValSts 1;
BA_ "FlexKomSID" SG_ 520 DriverDoorAjarRawValSts 1943;
BA_ "FlexKomSigLaenge" SG_ 520 DriverDoorAjarRawValSts 64;
BA_ "FlexKomSigName" SG_ 520 DriverDoorAjarRawValSts "CBC_PT6_Pkt";
BA_ "FlexKomSigStartPos" SG_ 520 DriverDoorAjarRawValSts 7;
BA_ "FlexKomSigStartValue" SG_ 520 DriverDoorAjarRawValSts "3FFF0C0000000000h";
BA_ "GenSigCycleTime" SG_ 520 DriverDoorAjarRawValSts 20;
BA_ "GenSigSNA" SG_ 520 DriverDoorAjarRawValSts "Fh";
BA_ "GenSigTimeout_ORC" SG_ 520 DriverDoorAjarRawValSts 70;
BA_ "FlexKomComment" SG_ 520 DriverDoorAjarXtionSts "CBC_PT6 message packet";
BA_ "FlexKomIsMotorola" SG_ 520 DriverDoorAjarXtionSts 1;
BA_ "FlexKomSID" SG_ 520 DriverDoorAjarXtionSts 1943;
BA_ "FlexKomSigLaenge" SG_ 520 DriverDoorAjarXtionSts 64;
BA_ "FlexKomSigName" SG_ 520 DriverDoorAjarXtionSts "CBC_PT6_Pkt";
BA_ "FlexKomSigStartPos" SG_ 520 DriverDoorAjarXtionSts 7;
BA_ "FlexKomSigStartValue" SG_ 520 DriverDoorAjarXtionSts "3FFF0C0000000000h";
BA_ "GenSigCycleTime" SG_ 520 DriverDoorAjarXtionSts 20;
BA_ "GenSigSNA" SG_ 520 DriverDoorAjarXtionSts "3h";
BA_ "GenSigStartValue" SG_ 520 DriverDoorAjarXtionSts 3;
BA_ "FlexKomComment" SG_ 520 FuelDrRelSwRawSt "CBC_PT6 message packet";
BA_ "FlexKomIsMotorola" SG_ 520 FuelDrRelSwRawSt 1;
BA_ "FlexKomSID" SG_ 520 FuelDrRelSwRawSt 1943;
BA_ "FlexKomSigLaenge" SG_ 520 FuelDrRelSwRawSt 64;
BA_ "FlexKomSigName" SG_ 520 FuelDrRelSwRawSt "CBC_PT6_Pkt";
BA_ "FlexKomSigStartPos" SG_ 520 FuelDrRelSwRawSt 7;
BA_ "FlexKomSigStartValue" SG_ 520 FuelDrRelSwRawSt "3FFF0C0000000000h";
BA_ "GenSigCycleTime" SG_ 520 FuelDrRelSwRawSt 20;
BA_ "GenSigSNA" SG_ 520 FuelDrRelSwRawSt "FFh";
BA_ "FlexKomComment" SG_ 520 LeakCheckTimerExpired "CBC_PT6 message packet";
BA_ "FlexKomIsMotorola" SG_ 520 LeakCheckTimerExpired 1;
BA_ "FlexKomSID" SG_ 520 LeakCheckTimerExpired 1943;
BA_ "FlexKomSigLaenge" SG_ 520 LeakCheckTimerExpired 64;
BA_ "FlexKomSigName" SG_ 520 LeakCheckTimerExpired "CBC_PT6_Pkt";
BA_ "FlexKomSigStartPos" SG_ 520 LeakCheckTimerExpired 7;
BA_ "FlexKomSigStartValue" SG_ 520 LeakCheckTimerExpired "3FFF0C0000000000h";
BA_ "GenSigCycleTime" SG_ 520 LeakCheckTimerExpired 20;
BA_ "GenSigSNA" SG_ 520 LeakCheckTimerExpired "3h";
BA_ "FlexKomComment" SG_ 520 PsngrDoorAjarRawValSts "CBC_PT6 message packet";
BA_ "FlexKomIsMotorola" SG_ 520 PsngrDoorAjarRawValSts 1;
BA_ "FlexKomSID" SG_ 520 PsngrDoorAjarRawValSts 1943;
BA_ "FlexKomSigLaenge" SG_ 520 PsngrDoorAjarRawValSts 64;
BA_ "FlexKomSigName" SG_ 520 PsngrDoorAjarRawValSts "CBC_PT6_Pkt";
BA_ "FlexKomSigStartPos" SG_ 520 PsngrDoorAjarRawValSts 7;
BA_ "FlexKomSigStartValue" SG_ 520 PsngrDoorAjarRawValSts "3FFF0C0000000000h";
BA_ "GenSigCycleTime" SG_ 520 PsngrDoorAjarRawValSts 20;
BA_ "GenSigSNA" SG_ 520 PsngrDoorAjarRawValSts "Fh";
BA_ "GenSigTimeout_ORC" SG_ 520 PsngrDoorAjarRawValSts 70;
BA_ "FlexKomComment" SG_ 520 PsngrDoorAjarXtionSts "CBC_PT6 message packet";
BA_ "FlexKomIsMotorola" SG_ 520 PsngrDoorAjarXtionSts 1;
BA_ "FlexKomSID" SG_ 520 PsngrDoorAjarXtionSts 1943;
BA_ "FlexKomSigLaenge" SG_ 520 PsngrDoorAjarXtionSts 64;
BA_ "FlexKomSigName" SG_ 520 PsngrDoorAjarXtionSts "CBC_PT6_Pkt";
BA_ "FlexKomSigStartPos" SG_ 520 PsngrDoorAjarXtionSts 7;
BA_ "FlexKomSigStartValue" SG_ 520 PsngrDoorAjarXtionSts "3FFF0C0000000000h";
BA_ "GenSigCycleTime" SG_ 520 PsngrDoorAjarXtionSts 20;
BA_ "GenSigSNA" SG_ 520 PsngrDoorAjarXtionSts "3h";
BA_ "GenSigStartValue" SG_ 520 PsngrDoorAjarXtionSts 3;
BA_ "FlexKomComment" SG_ 520 RefuelRequest "CBC_PT6 message packet";
BA_ "FlexKomIsMotorola" SG_ 520 RefuelRequest 1;
BA_ "FlexKomSID" SG_ 520 RefuelRequest 1943;
BA_ "FlexKomSigLaenge" SG_ 520 RefuelRequest 64;
BA_ "FlexKomSigName" SG_ 520 RefuelRequest "CBC_PT6_Pkt";
BA_ "FlexKomSigStartPos" SG_ 520 RefuelRequest 7;
BA_ "FlexKomSigStartValue" SG_ 520 RefuelRequest "3FFF0C0000000000h";
BA_ "GenSigCycleTime" SG_ 520 RefuelRequest 20;
BA_ "GenSigSNA" SG_ 520 RefuelRequest "3h";
BA_ "FlexKomComment" SG_ 564 AM_ECM_Trace "Aftermarket ECM trace";
BA_ "FlexKomIsMotorola" SG_ 564 AM_ECM_Trace 1;
BA_ "FlexKomSID" SG_ 564 AM_ECM_Trace 1942;
BA_ "FlexKomSigLaenge" SG_ 564 AM_ECM_Trace 2;
BA_ "FlexKomSigName" SG_ 564 AM_ECM_Trace "AM_ECM_Trace";
BA_ "FlexKomSigStartPos" SG_ 564 AM_ECM_Trace 23;
BA_ "FlexKomSigStartValue" SG_ 564 AM_ECM_Trace "00h";
BA_ "GenSigCycleTime" SG_ 564 AM_ECM_Trace 100;
BA_ "GenSigSNA" SG_ 564 AM_ECM_Trace "3h";
BA_ "FlexKomComment" SG_ 564 IBS_Error_Calib "IBS Battery Information additional";
BA_ "FlexKomIsMotorola" SG_ 564 IBS_Error_Calib 1;
BA_ "FlexKomSID" SG_ 564 IBS_Error_Calib 1405;
BA_ "FlexKomSigLaenge" SG_ 564 IBS_Error_Calib 32;
BA_ "FlexKomSigName" SG_ 564 IBS_Error_Calib "PN14_IBS_DATA_2";
BA_ "FlexKomSigStartPos" SG_ 564 IBS_Error_Calib 7;
BA_ "FlexKomSigStartValue" SG_ 564 IBS_Error_Calib "FF0300FFh";
BA_ "GenSigCycleTime" SG_ 564 IBS_Error_Calib 100;
BA_ "GenSigSNA" SG_ 564 IBS_Error_Calib "0h";
BA_ "RID" SG_ 564 IBS_Error_Calib "966";
BA_ "FlexKomComment" SG_ 564 IBS_Error_Ident "IBS Battery Information additional";
BA_ "FlexKomIsMotorola" SG_ 564 IBS_Error_Ident 1;
BA_ "FlexKomSID" SG_ 564 IBS_Error_Ident 1405;
BA_ "FlexKomSigLaenge" SG_ 564 IBS_Error_Ident 32;
BA_ "FlexKomSigName" SG_ 564 IBS_Error_Ident "PN14_IBS_DATA_2";
BA_ "FlexKomSigStartPos" SG_ 564 IBS_Error_Ident 7;
BA_ "FlexKomSigStartValue" SG_ 564 IBS_Error_Ident "FF0300FFh";
BA_ "GenSigCycleTime" SG_ 564 IBS_Error_Ident 100;
BA_ "GenSigSNA" SG_ 564 IBS_Error_Ident "0h";
BA_ "RID" SG_ 564 IBS_Error_Ident "963";
BA_ "FlexKomComment" SG_ 564 IBS_Error_NVM "IBS Battery Information additional";
BA_ "FlexKomIsMotorola" SG_ 564 IBS_Error_NVM 1;
BA_ "FlexKomSID" SG_ 564 IBS_Error_NVM 1405;
BA_ "FlexKomSigLaenge" SG_ 564 IBS_Error_NVM 32;
BA_ "FlexKomSigName" SG_ 564 IBS_Error_NVM "PN14_IBS_DATA_2";
BA_ "FlexKomSigStartPos" SG_ 564 IBS_Error_NVM 7;
BA_ "FlexKomSigStartValue" SG_ 564 IBS_Error_NVM "FF0300FFh";
BA_ "GenSigCycleTime" SG_ 564 IBS_Error_NVM 100;
BA_ "GenSigSNA" SG_ 564 IBS_Error_NVM "0h";
BA_ "RID" SG_ 564 IBS_Error_NVM "967";
BA_ "FlexKomComment" SG_ 564 IBS_SOF_V "IBS Battery Information additional";
BA_ "FlexKomIsMotorola" SG_ 564 IBS_SOF_V 1;
BA_ "FlexKomSID" SG_ 564 IBS_SOF_V 1405;
BA_ "FlexKomSigLaenge" SG_ 564 IBS_SOF_V 32;
BA_ "FlexKomSigName" SG_ 564 IBS_SOF_V "PN14_IBS_DATA_2";
BA_ "FlexKomSigStartPos" SG_ 564 IBS_SOF_V 7;
BA_ "FlexKomSigStartValue" SG_ 564 IBS_SOF_V "FF0300FFh";
BA_ "GenSigCycleTime" SG_ 564 IBS_SOF_V 100;
BA_ "GenSigSNA" SG_ 564 IBS_SOF_V "FFh";
BA_ "GenSigStartValue" SG_ 564 IBS_SOF_V 255;
BA_ "RID" SG_ 564 IBS_SOF_V "965";
BA_ "FlexKomComment" SG_ 564 IBS_SOF_V1 "IBS Battery Information additional";
BA_ "FlexKomIsMotorola" SG_ 564 IBS_SOF_V1 1;
BA_ "FlexKomSID" SG_ 564 IBS_SOF_V1 1405;
BA_ "FlexKomSigLaenge" SG_ 564 IBS_SOF_V1 32;
BA_ "FlexKomSigName" SG_ 564 IBS_SOF_V1 "PN14_IBS_DATA_2";
BA_ "FlexKomSigStartPos" SG_ 564 IBS_SOF_V1 7;
BA_ "FlexKomSigStartValue" SG_ 564 IBS_SOF_V1 "FF0300FFh";
BA_ "GenSigCycleTime" SG_ 564 IBS_SOF_V1 100;
BA_ "GenSigSNA" SG_ 564 IBS_SOF_V1 "FFh";
BA_ "GenSigStartValue" SG_ 564 IBS_SOF_V1 255;
BA_ "RID" SG_ 564 IBS_SOF_V1 "999";
BA_ "FlexKomComment" SG_ 564 IBS_SOF_V_Accuracy "IBS Battery Information additional";
BA_ "FlexKomIsMotorola" SG_ 564 IBS_SOF_V_Accuracy 1;
BA_ "FlexKomSID" SG_ 564 IBS_SOF_V_Accuracy 1405;
BA_ "FlexKomSigLaenge" SG_ 564 IBS_SOF_V_Accuracy 32;
BA_ "FlexKomSigName" SG_ 564 IBS_SOF_V_Accuracy "PN14_IBS_DATA_2";
BA_ "FlexKomSigStartPos" SG_ 564 IBS_SOF_V_Accuracy 7;
BA_ "FlexKomSigStartValue" SG_ 564 IBS_SOF_V_Accuracy "FF0300FFh";
BA_ "GenSigCycleTime" SG_ 564 IBS_SOF_V_Accuracy 100;
BA_ "GenSigSNA" SG_ 564 IBS_SOF_V_Accuracy "3h";
BA_ "GenSigStartValue" SG_ 564 IBS_SOF_V_Accuracy 3;
BA_ "RID" SG_ 564 IBS_SOF_V_Accuracy "962";
BA_ "FlexKomComment" SG_ 861 IBS2_Error_Calib "IBS2 Battery Information additional";
BA_ "FlexKomIsMotorola" SG_ 861 IBS2_Error_Calib 1;
BA_ "FlexKomSID" SG_ 861 IBS2_Error_Calib 9204;
BA_ "FlexKomSigLaenge" SG_ 861 IBS2_Error_Calib 32;
BA_ "FlexKomSigName" SG_ 861 IBS2_Error_Calib "PN14_IBS2_DATA_2";
BA_ "FlexKomSigStartPos" SG_ 861 IBS2_Error_Calib 7;
BA_ "FlexKomSigStartValue" SG_ 861 IBS2_Error_Calib "FF0300FFh";
BA_ "GenSigCycleTime" SG_ 861 IBS2_Error_Calib 100;
BA_ "GenSigSNA" SG_ 861 IBS2_Error_Calib "0h";
BA_ "RID" SG_ 861 IBS2_Error_Calib "9941";
BA_ "FlexKomComment" SG_ 861 IBS2_Error_Ident "IBS2 Battery Information additional";
BA_ "FlexKomIsMotorola" SG_ 861 IBS2_Error_Ident 1;
BA_ "FlexKomSID" SG_ 861 IBS2_Error_Ident 9204;
BA_ "FlexKomSigLaenge" SG_ 861 IBS2_Error_Ident 32;
BA_ "FlexKomSigName" SG_ 861 IBS2_Error_Ident "PN14_IBS2_DATA_2";
BA_ "FlexKomSigStartPos" SG_ 861 IBS2_Error_Ident 7;
BA_ "FlexKomSigStartValue" SG_ 861 IBS2_Error_Ident "FF0300FFh";
BA_ "GenSigCycleTime" SG_ 861 IBS2_Error_Ident 100;
BA_ "GenSigSNA" SG_ 861 IBS2_Error_Ident "0h";
BA_ "RID" SG_ 861 IBS2_Error_Ident "9942";
BA_ "FlexKomComment" SG_ 861 IBS2_Error_NVM "IBS2 Battery Information additional";
BA_ "FlexKomIsMotorola" SG_ 861 IBS2_Error_NVM 1;
BA_ "FlexKomSID" SG_ 861 IBS2_Error_NVM 9204;
BA_ "FlexKomSigLaenge" SG_ 861 IBS2_Error_NVM 32;
BA_ "FlexKomSigName" SG_ 861 IBS2_Error_NVM "PN14_IBS2_DATA_2";
BA_ "FlexKomSigStartPos" SG_ 861 IBS2_Error_NVM 7;
BA_ "FlexKomSigStartValue" SG_ 861 IBS2_Error_NVM "FF0300FFh";
BA_ "GenSigCycleTime" SG_ 861 IBS2_Error_NVM 100;
BA_ "GenSigSNA" SG_ 861 IBS2_Error_NVM "0h";
BA_ "RID" SG_ 861 IBS2_Error_NVM "9937";
BA_ "FlexKomComment" SG_ 861 IBS2_SOF_V "IBS2 Battery Information additional";
BA_ "FlexKomIsMotorola" SG_ 861 IBS2_SOF_V 1;
BA_ "FlexKomSID" SG_ 861 IBS2_SOF_V 9204;
BA_ "FlexKomSigLaenge" SG_ 861 IBS2_SOF_V 32;
BA_ "FlexKomSigName" SG_ 861 IBS2_SOF_V "PN14_IBS2_DATA_2";
BA_ "FlexKomSigStartPos" SG_ 861 IBS2_SOF_V 7;
BA_ "FlexKomSigStartValue" SG_ 861 IBS2_SOF_V "FF0300FFh";
BA_ "GenSigCycleTime" SG_ 861 IBS2_SOF_V 100;
BA_ "GenSigSNA" SG_ 861 IBS2_SOF_V "FFh";
BA_ "GenSigStartValue" SG_ 861 IBS2_SOF_V 255;
BA_ "RID" SG_ 861 IBS2_SOF_V "9945";
BA_ "FlexKomComment" SG_ 861 IBS2_SOF_V1 "IBS2 Battery Information additional";
BA_ "FlexKomIsMotorola" SG_ 861 IBS2_SOF_V1 1;
BA_ "FlexKomSID" SG_ 861 IBS2_SOF_V1 9204;
BA_ "FlexKomSigLaenge" SG_ 861 IBS2_SOF_V1 32;
BA_ "FlexKomSigName" SG_ 861 IBS2_SOF_V1 "PN14_IBS2_DATA_2";
BA_ "FlexKomSigStartPos" SG_ 861 IBS2_SOF_V1 7;
BA_ "FlexKomSigStartValue" SG_ 861 IBS2_SOF_V1 "FF0300FFh";
BA_ "GenSigCycleTime" SG_ 861 IBS2_SOF_V1 100;
BA_ "GenSigSNA" SG_ 861 IBS2_SOF_V1 "FFh";
BA_ "GenSigStartValue" SG_ 861 IBS2_SOF_V1 255;
BA_ "RID" SG_ 861 IBS2_SOF_V1 "9949";
BA_ "FlexKomComment" SG_ 861 IBS2_SOF_V_Accuracy "IBS2 Battery Information additional";
BA_ "FlexKomIsMotorola" SG_ 861 IBS2_SOF_V_Accuracy 1;
BA_ "FlexKomSID" SG_ 861 IBS2_SOF_V_Accuracy 9204;
BA_ "FlexKomSigLaenge" SG_ 861 IBS2_SOF_V_Accuracy 32;
BA_ "FlexKomSigName" SG_ 861 IBS2_SOF_V_Accuracy "PN14_IBS2_DATA_2";
BA_ "FlexKomSigStartPos" SG_ 861 IBS2_SOF_V_Accuracy 7;
BA_ "FlexKomSigStartValue" SG_ 861 IBS2_SOF_V_Accuracy "FF0300FFh";
BA_ "GenSigCycleTime" SG_ 861 IBS2_SOF_V_Accuracy 100;
BA_ "GenSigSNA" SG_ 861 IBS2_SOF_V_Accuracy "3h";
BA_ "GenSigStartValue" SG_ 861 IBS2_SOF_V_Accuracy 3;
BA_ "RID" SG_ 861 IBS2_SOF_V_Accuracy "9952";
VAL_ 549 RHSC_VehicleOpMode 7 "SNA" ;
VAL_ 549 RHSC_DampingScalarReq 255 "SNA" ;
VAL_ 549 RHSC_MotorTorqueCommand 2047 "SNA" ;
VAL_ 549 RHSC_OverlayIntActivation 0 "NOT_ACTIVE" 1 "ACTIVE" ;
VAL_ 549 RHSCSystemSts 0 "NO_FAULT" 1 "FAULT" ;
VAL_ 547 EPS_MotorTorqueAvailable 1023 "SNA" ;
VAL_ 547 EPS_LastSDSTorqueRequest 2047 "SNA" ;
VAL_ 547 EPS_SDSTorqueApplied 2047 "SNA" ;
VAL_ 546 EPS_SteerVelocity 32767 "SNA" ;
VAL_ 546 EPS_SteerAngle 32767 "SNA" ;
VAL_ 969 AMB_TEMP_AVG_C 255 "SNA" ;
VAL_ 969 AMB_TEMP_AVG_F 255 "SNA" ;
VAL_ 838 AS_CHIME_TYPE 0 "NONE" 1 "TYP_1" 2 "TYP_2" 3 "TYP_3" 4 "TYP_4" 5 "TYP_5" 6 "TYP_6" 7 "TYP_7" 8 "TYP_8" 9 "TYP_9" 10 "TYP_10" 11 "TYP_11" 12 "TYP_12" 13 "TYP_13" 14 "TYP_14" 15 "SNA" ;
VAL_ 168 DrvrIntndedAxleTorq 16383 "SNA" ;
VAL_ 523 ESLLockUnlockReq 0 "Not_Request" 1 "Unlock" 2 "Lock" ;
VAL_ 720 BSM_CFG_STAT 0 "NT_ENB" 1 "ENB_LED" 2 "ENB_LED_CHM" 3 "SNA" ;
VAL_ 720 BSM_CFG_STAT_TeenKey 0 "NT_ENB" 1 "ENB_LED" 2 "ENB_LED_CHM" 3 "SNA" ;
VAL_ 720 BSM_LT_WRN 0 "NW" 2 "RM_LED" 3 "RBM_LED" 4 "FM_LED" 5 "FBM_LED" 7 "SNA" ;
VAL_ 720 BSM_RT_WRN 0 "NW" 2 "RM_LED" 3 "RBM_LED" 4 "FM_LED" 5 "FBM_LED" 7 "SNA" ;
VAL_ 998 BU_NET_CFG_STAT_INT 0 "NA" 1 "PROGAMMED" 2 "NA1" 3 "SNA" ;
VAL_ 998 BU_NetCfg_ANC_I 0 "Not_Present" 1 "Present" ;
VAL_ 999 BU_NET_CFG_STAT_PT 0 "NA" 1 "PROGAMMED" 2 "NA1" 3 "SNA" ;
VAL_ 999 BU_NetCfg_BSMO 0 "Not_Present" 1 "Present" ;
VAL_ 999 BU_NetCfg_RHSC2 0 "Not_Present" 1 "Present" ;
VAL_ 927 BU_NET_CFG_STAT_ePT 0 "NA" 1 "PROGAMMED" 2 "NA1" 3 "SNA" ;
VAL_ 927 BU_NetCfg_BSMO_ePT 0 "Not_Present" 1 "Present" ;
VAL_ 937 HL_DLY_TIME 255 "SNA" ;
VAL_ 937 ILL_APRCH_TIME 255 "SNA" ;
VAL_ 937 SOUND_LK_1ST_2ND 0 "OFF" 1 "FIRST" 2 "SECOND" 3 "SNA" ;
VAL_ 820 DR_LK_STAT 0 "LKD" 1 "DRV_DR_UNLKD" 2 "ALL_DR_UNLKD" 3 "SNA" ;
VAL_ 820 FOB_SrchRq 0 "NO_ACT" 1 "SEARCH" 2 "RCVD_RSLT" ;
VAL_ 820 IGN_OFF_TIME_LNG 4095 "SNA" ;
VAL_ 820 PANEL_INTS 255 "SNA" ;
VAL_ 820 SHIP_STAT 0 "CUST_MD" 1 "ABBRV_MD" 2 "SHIP_MD" 3 "NOT_PROG" ;
VAL_ 274 CmdIgnStat 0 "IGN_LK" 3 "IGN_OFF_ACC" 4 "IGN_RUN" 5 "IGN_START" 7 "SNA" ;
VAL_ 274 KeyInIgn 0 "KEY_DEF" 1 "KEY_NOT_IN_IGN" 2 "KEY_IN_IGN" 3 "SNA" ;
VAL_ 274 StTyp 0 "ST_NOT_ACT" 1 "NOR_ST" 2 "TIP_ST" 3 "REM_ST" 7 "SNA" ;
VAL_ 512 AMB_TEMP_AVG 65535 "SNA" ;
VAL_ 512 AMB_TEMP_VOLT 255 "SNA" ;
VAL_ 512 AirTemp_Outsd 255 "SNA" ;
VAL_ 512 BATT_VOLT 255 "SNA" ;
VAL_ 512 FUEL_VOLT 255 "SNA" ;
VAL_ 804 RemSt_Inhibit 0 "INHIBIT_DEFAUILT" 1 "TIME_OUT_RUN" 2 "TIME_OUT_CUST_MODE" 3 "KEY_IN_RUN" 4 "DRV_DOOR_AJAR" 5 "PASS_DOOR_AJAR" 6 "LR_DOOR_AJAR" 7 "RR_DOOR_AJAR" 8 "START_COUNTER" 9 "FAIL_COUNTER" 10 "LOW_RPM_SHUTDOWN" 11 "KEY_IN_IGN" 12 "BRAKE_PRESSED" 13 "HAZARD_LAMP_ON" 14 "NOT_IN_PARK" 15 "VEH_SPEED_HIGH" 16 "HOOD_AJAR" 17 "TRUNK_LIFTGATE" 18 "VTA_ALARM" 19 "PANIC_MODE" 20 "BATT_VOLT_HIGH" 21 "BATT_VOLT_LOW" 22 "POWER_LOSS" 23 "MIL_ON" 24 "OIL_PRESSURE_LOW" 25 "COOLANT_TEMP_HIGH" 26 "RPM_HIGH" 27 "CRANK_NO_START" 28 "REMOTE_OFF_RQ" 29 "RS_DISABLED_PREV" 30 "NOT_CONFIGURED" 31 "NO_HOOD_SWITCH" 32 "NO_AUTO_TRANS" 33 "NOT_ENABLED" 34 "INVALID_SKIM_KEY" 35 "IGN_SNA" 36 "IGN_NOT_LOCK" 37 "GLOW_PLUG_TIMEOUT" 38 "LOW_FUEL" 39 "ETC_LAMP_ON" 40 "LOGISTIC_MODE" 41 "COLD_START_LAMP" 42 "ESL_NOT_UNLOCK" 43 "RFHUB_HS_FAIL" 44 "PSA_Not_Active" 255 "SNA" ;
VAL_ 804 WPR_SYS_AUTO 0 "SNA" ;
VAL_ 804 WPR_SYS_FLT 0 "SNA" ;
VAL_ 804 WPR_SYS_HIGH 0 "SNA" ;
VAL_ 804 WPR_SYS_INT 0 "SNA" ;
VAL_ 804 WPR_SYS_LOW 0 "SNA" ;
VAL_ 804 WPR_SYS_MIST 0 "SNA" ;
VAL_ 804 WPR_SYS_OFF 1 "SNA" ;
VAL_ 804 WPR_SYS_WASH 0 "SNA" ;
VAL_ 520 BonnetAjarRawValSts 0 "DEFAULT" 1 "FL_SSA" 2 "FL_SSB" 3 "FL_SSC" 4 "FL_SSD" 5 "FL_SSE" 6 "OPEN_SSA" 7 "OPEN_SSB" 8 "CLOSED_SSA" 9 "CLOSED_SSB" 10 "FH_SSA" 11 "FH_SSB" 12 "FH_SSC" 13 "FH_SSD" 14 "FH_SSE" 15 "SNA" ;
VAL_ 520 BrkPdlStat_CBC 0 "UPSTOP" 1 "PSD" 2 "NDEF2" 3 "SNA" ;
VAL_ 520 DriverDoor2AjarRawValSts 0 "DEFAULT" 1 "FL_SSA" 2 "FL_SSB" 3 "FL_SSC" 4 "FL_SSD" 5 "FL_SSE" 6 "OPEN_SSA" 7 "OPEN_SSB" 8 "CLOSED_SSA" 9 "CLOSED_SSB" 10 "FH_SSA" 11 "FH_SSB" 12 "FH_SSC" 13 "FH_SSD" 14 "FH_SSE" 15 "SNA" ;
VAL_ 520 DriverDoor2AjarXtionSts 1 "NONE" 2 "TRNS" 3 "SNA" ;
VAL_ 520 DriverDoorAjarRawValSts 0 "DEFAULT" 1 "FL_SSA" 2 "FL_SSB" 3 "FL_SSC" 4 "FL_SSD" 5 "FL_SSE" 6 "OPEN_SSA" 7 "OPEN_SSB" 8 "CLOSED_SSA" 9 "CLOSED_SSB" 10 "FH_SSA" 11 "FH_SSB" 12 "FH_SSC" 13 "FH_SSD" 14 "FH_SSE" 15 "SNA" ;
VAL_ 520 DriverDoorAjarXtionSts 1 "NONE" 2 "TRNS" 3 "SNA" ;
VAL_ 520 FuelDrRelSwRawSt 255 "SNA" ;
VAL_ 520 LeakCheckTimerExpired 0 "NOT" 1 "ELAPSED" 3 "SNA" ;
VAL_ 520 PsngrDoorAjarRawValSts 0 "DEFAULT" 1 "FL_SSA" 2 "FL_SSB" 3 "FL_SSC" 4 "FL_SSD" 5 "FL_SSE" 6 "OPEN_SSA" 7 "OPEN_SSB" 8 "CLOSED_SSA" 9 "CLOSED_SSB" 10 "FH_SSA" 11 "FH_SSB" 12 "FH_SSC" 13 "FH_SSD" 14 "FH_SSE" 15 "SNA" ;
VAL_ 520 PsngrDoorAjarXtionSts 1 "NONE" 2 "TRNS" 3 "SNA" ;
VAL_ 520 RefuelRequest 0 "NO" 1 "REFUEL" 3 "SNA" ;
VAL_ 564 AM_ECM_Trace 0 "DEFAULT" 2 "AM_ECM_TRACE" 3 "SNA" ;
VAL_ 564 IBS_SOF_V 255 "SNA" ;
VAL_ 564 IBS_SOF_V1 255 "SNA" ;
VAL_ 564 IBS_SOF_V_Accuracy 0 "ACCURACY_0" 1 "ACCURACY_1" 2 "ACCURACY_2" 3 "SNA" ;
VAL_ 861 IBS2_SOF_V 255 "SNA" ;
VAL_ 861 IBS2_SOF_V1 255 "SNA" ;
VAL_ 861 IBS2_SOF_V_Accuracy 0 "ACCURACY_0" 1 "ACCURACY_1" 2 "ACCURACY_2" 3 "SNA" ;
